VERSION "Generated from PQ35_46 ACAN KMatrix"

NS_ :

BS_:

BU_: XXX AFS Airbag Allrad AppGW_SK BAP_Tester BMS_Hybrid Bremse_ESP_AU714 Bremse_ESP_EPB_EBC460Vi Bremse_MK100_ESC Bremse_MK60EC Bremse_MK70MABS Bremse_TRW_EBC450M Bremse_TRW_ESP Daempfer EPB_TRW EPB_TRW_VW411CS ESP_AU316 FLA Gateway_PQ35 Getriebe_AG6 Getriebe_DL800_R8 Getriebe_DL800_ZSG_R8 Getriebe_DQ Getriebe_DQ_Hyb Getriebe_Sele Gurtmikro_PQ35 HCA LEH_Hybrid LH_EPS_APA LH_EPS_ZF_2G LH_EPS_ZF_3G LPG_Interface_Box LWR LWS Magne_Ride Motor_Diesel Motor_Hybrid Motor_Otto Motor_Slave PDC_PLA Quersperre_VAQ RKA_Plus SAK Waehlhebel Waehlhebel_Sele

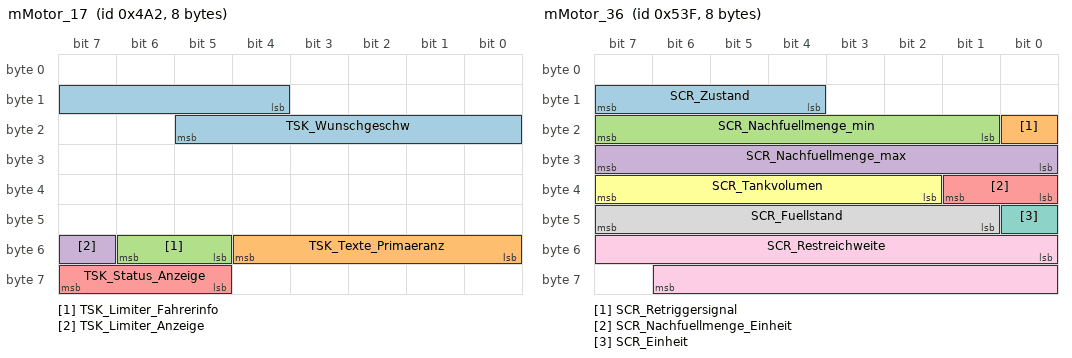
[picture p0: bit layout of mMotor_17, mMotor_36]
BO_ 1186 mMotor_17: 8 XXX
 SG_ TSK_Wunschgeschw : 12|10@1+ (0.32,0) [0|326.72] "Unit_KiloMeterPerHour" Gateway_PQ35
 SG_ TSK_Texte_Primaeranz : 48|5@1+ (1,0) [0|14] "" Gateway_PQ35
 SG_ TSK_Limiter_Fahrerinfo : 53|2@1+ (1,0) [0|3] "" Gateway_PQ35
 SG_ TSK_Limiter_Anzeige : 55|1@1+ (1,0) [0|1] "" Gateway_PQ35
 SG_ TSK_Status_Anzeige : 61|3@1+ (1,0) [0|7] "" Gateway_PQ35

BO_ 1343 mMotor_36: 8 XXX
 SG_ SCR_Zustand : 12|4@1+ (1,0) [0|15] "" Gateway_PQ35
 SG_ SCR_Retriggersignal : 16|1@1+ (1,0) [0|1] "" Gateway_PQ35
 SG_ SCR_Nachfuellmenge_min : 17|7@1+ (0.25,0) [0|31.5] "" Gateway_PQ35
 SG_ SCR_Nachfuellmenge_max : 24|8@1+ (0.25,0) [0|63.5] "" Gateway_PQ35
 SG_ SCR_Nachfuellmenge_Einheit : 32|2@1+ (1,0) [0|3] "" Gateway_PQ35
 SG_ SCR_Tankvolumen : 34|6@1+ (1,0) [0|63] "" Gateway_PQ35
 SG_ SCR_Einheit : 40|1@1+ (1,0) [0|1] "" Gateway_PQ35
 SG_ SCR_Fuellstand : 41|7@1+ (1,0) [0|100] "Unit_PerCent" Gateway_PQ35
 SG_ SCR_Restreichweite : 48|15@1+ (1,0) [0|32767] "" Gateway_PQ35

BO_ 1160 mMotor_6: 8 XXX
 SG_ MO6_Checksum : 0|8@1+ (1,0) [0|255] "" Getriebe_AG6
 SG_ MO6_SollM_Getr : 8|8@1+ (0.39,0) [0|99.06] "Unit_PerCent" Getriebe_DL800_R8,Getriebe_DQ,Getriebe_DQ_Hyb,Getriebe_Sele
 SG_ MO6_Ist_Moment : 16|8@1+ (0.39,0) [0|99.06] "Unit_PerCent" Gateway_PQ35,Getriebe_AG6,Getriebe_DL800_R8,Getriebe_DQ,Getriebe_DQ_Hyb,Getriebe_Sele
 SG_ MO6_Hoeheninfo : 24|8@1+ (0.0078125,0) [0|1.984375] "" Getriebe_AG6,Getriebe_DL800_R8,Getriebe_DQ,Getriebe_DQ_Hyb
 SG_ MO6_GRA_Soll : 32|8@1+ (0.024,-3.984) [-3.984|2.088] "Unit_MeterPerSeconSquar" Getriebe_AG6,Getriebe_DL800_R8,Getriebe_DQ,Getriebe_DQ_Hyb
 SG_ MO6_MomIntGeEing : 40|8@1+ (0.3921568627450980392156862745098,0) [0|100] "Unit_PerCent" Getriebe_DL800_R8,Getriebe_DQ,Getriebe_DQ_Hyb
 SG_ MO6_FF_Mux00 : 48|8@1+ (0.3921568627450980392156862745098,0) [0|100] "Unit_PerCent" BMS_Hybrid,Getriebe_AG6,Getriebe_DL800_R8,Getriebe_DL800_ZSG_R8,Getriebe_DQ,Getriebe_DQ_Hyb,Getriebe_Sele,LEH_Hybrid
 SG_ MO6_FF_Mux01 : 48|8@1+ (0.3921568627450980392156862745098,0) [0|100] "Unit_PerCent" BMS_Hybrid,Getriebe_AG6,Getriebe_DL800_R8,Getriebe_DL800_ZSG_R8,Getriebe_DQ,Getriebe_DQ_Hyb,Getriebe_Sele,LEH_Hybrid
 SG_ MO6_FF_Mux02 : 48|8@1+ (1,-40) [-40|215] "Unit_DegreCelsi" BMS_Hybrid,Getriebe_AG6,Getriebe_DL800_R8,Getriebe_DL800_ZSG_R8,Getriebe_DQ,Getriebe_DQ_Hyb,Getriebe_Sele,LEH_Hybrid
 SG_ MO6_FF_Mux03 : 48|8@1+ (3.13725490196078,0) [0|799.9999999999989] "Unit_PerCent" BMS_Hybrid,Getriebe_AG6,Getriebe_DL800_R8,Getriebe_DL800_ZSG_R8,Getriebe_DQ,Getriebe_DQ_Hyb,Getriebe_Sele,LEH_Hybrid
 SG_ MO6_FF_Mux04 : 48|8@1+ (0.3921568627450980392156862745098,0) [0|100] "Unit_PerCent" BMS_Hybrid,Getriebe_AG6,Getriebe_DL800_R8,Getriebe_DL800_ZSG_R8,Getriebe_DQ,Getriebe_DQ_Hyb,Getriebe_Sele,LEH_Hybrid
 SG_ MO6_FF_Mux05 : 48|8@1+ (1,0) [255|255] "" XXX
 SG_ MO6_FF_Mux06 : 48|8@1+ (1,0) [255|255] "" XXX
 SG_ MO6_FF_Mux07 : 48|8@1+ (1,0) [255|255] "" XXX
 SG_ MO6_FF_Mux08 : 48|8@1+ (1,0) [255|255] "" XXX
 SG_ MO6_FF_Mux09 : 48|8@1+ (1,0) [255|255] "" XXX
 SG_ MO6_FF_Mux10 : 48|8@1+ (1,0) [255|255] "" XXX
 SG_ MO6_FF_Mux11 : 48|8@1+ (1,0) [255|255] "" XXX
 SG_ MO6_FF_Mux12 : 48|8@1+ (1,0) [255|255] "" XXX
 SG_ MO6_FF_Mux13 : 48|8@1+ (1,0) [255|255] "" XXX
 SG_ MO6_FF_Mux14 : 48|8@1+ (1,0) [255|255] "" XXX
 SG_ MO6_FF_Mux15 : 48|8@1+ (1,0) [255|255] "" XXX
 SG_ MO6_Freigabe_GRA : 56|1@1+ (1,0) [0|1] "" Getriebe_AG6,Getriebe_DL800_R8,Getriebe_DQ,Getriebe_DQ_Hyb
 SG_ MO6_Schutz_Toel : 57|1@1+ (1,0) [0|1] "" Getriebe_AG6
 SG_ MO6_Luftpfad_akt : 58|1@1+ (1,0) [0|1] "" XXX
 SG_ MO6_RegPartikel : 59|1@1+ (1,0) [0|1] "" Getriebe_AG6,Getriebe_DL800_R8,Getriebe_DQ,Getriebe_DQ_Hyb
 SG_ MO6_Zaehler : 60|4@1+ (1,0) [0|15] "" BMS_Hybrid,Getriebe_AG6,Getriebe_DL800_R8,Getriebe_DL800_ZSG_R8,Getriebe_DQ,Getriebe_DQ_Hyb,LEH_Hybrid

BO_ 1162 mMotor_8: 8 XXX
 SG_ MO8_Checksumme : 0|8@1+ (1,0) [0|255] "" Gateway_PQ35,Magne_Ride
 SG_ MO8_AnzeigeDZ : 8|12@1+ (3,0) [0|12282] "Unit_MinutInver" AppGW_SK,Gateway_PQ35
 SG_ MO_Effizienzmodus : 20|1@1+ (1,0) [0|1] "" Gateway_PQ35
 SG_ MO8_SGT_Soundakt : 21|1@1+ (1,0) [0|1] "" Gateway_PQ35,SAK
 SG_ MO8_Spoiler_ausf : 22|1@1+ (1,0) [0|1] "" Gateway_PQ35
 SG_ MO8_Sportschalter : 23|1@1+ (1,0) [0|1] "" Gateway_PQ35,Getriebe_Sele,Magne_Ride
 SG_ MO8_LampeDZBegr : 24|1@1+ (1,0) [0|1] "" Gateway_PQ35,Getriebe_Sele
 SG_ MO8_Enable_Oeldr_Motor : 25|1@1+ (1,0) [0|1] "" Gateway_PQ35
 SG_ MO8_Oeldr_Warn_Motor : 26|1@1+ (1,0) [0|1] "" Gateway_PQ35
 SG_ MO8_Avus_Motorschutz : 27|2@1+ (1,0) [0|3] "" Gateway_PQ35,Getriebe_Sele
 SG_ MO8_Anzeigecode : 29|1@1+ (1,0) [0|1] "" AppGW_SK,Gateway_PQ35
 SG_ MO_P_verriegelt : 30|2@1+ (1,0) [0|3] "" Gateway_PQ35
 SG_ MO8_GRA_v_Wunsch : 32|9@1+ (1,0) [0|511] "Unit_KiloMeterPerHour" Gateway_PQ35
 SG_ MO_Schaltempf_verfbar : 41|1@1+ (1,0) [0|1] "" AppGW_SK,Gateway_PQ35
 SG_ MO8_Nachlauf_ZWP : 42|6@1+ (15,0) [0|945] "Unit_Secon" Gateway_PQ35
 SG_ MO_Istgang : 48|4@1+ (1,0) [0|9] "" Gateway_PQ35
 SG_ MO_Sollgang : 52|4@1+ (1,0) [0|15] "" AppGW_SK,Gateway_PQ35
 SG_ MO8_Zaehler : 60|4@1+ (1,0) [0|15] "" Gateway_PQ35,Magne_Ride

BO_ 1800 mMotor_CNG_1: 8 XXX
 SG_ MC1_Anz_Betrieb : 0|1@1+ (1,0) [0|1] "" Gateway_PQ35
 SG_ MC1_Schalter : 1|1@1+ (1,0) [0|1] "" Gateway_PQ35
 SG_ MC1_akt_Betrieb : 2|1@1+ (1,0) [0|1] "" Gateway_PQ35
 SG_ MC1_CNG_LPG : 3|1@1+ (1,0) [0|1] "" Gateway_PQ35
 SG_ MO_LPG_Tankstopp : 4|1@1+ (1,0) [0|1] "" Gateway_PQ35
 SG_ MO_Erdgasqualitaet : 5|3@1+ (1,0) [0|7] "" Gateway_PQ35
 SG_ MC1_Fuellungsgrad : 8|8@1+ (0.4,0) [0|101.2] "Unit_PerCent" Gateway_PQ35
 SG_ MC1_Verbrauch : 16|15@1+ (1,0) [0|32767] "Unit_MilliGram" Gateway_PQ35
 SG_ MC1_Verbrauch_LPG : 16|15@1+ (1,0) [0|32767] "Unit_MicroLiter" Gateway_PQ35
 SG_ MC1_Ueb_Verbr : 31|1@1+ (1,0) [0|1] "" Gateway_PQ35
 SG_ MO_AnzeigeGasbetrieb : 32|4@1+ (1,0) [0|7] "" Gateway_PQ35
 SG_ MO_Gastemperatur : 48|8@1+ (1,-51) [-50|150] "Unit_DegreCelsi" Gateway_PQ35
 SG_ MO_Verbrauchsaequivalent : 56|8@1+ (0.008,0) [0.008|2] "Unit_None" Gateway_PQ35

BO_ 1562 mMotor_EV_1: 8 XXX
 SG_ MEV1_Checksumme : 0|8@1+ (1,0) [0|255] "" XXX
 SG_ MEV1_Zaehler : 8|4@1+ (1,0) [0|15] "" XXX
 SG_ MO_Red_FahrleistungsLampe : 12|1@1+ (1,0) [0|1] "" XXX
 SG_ Ladestecker_gesteckt : 13|1@1+ (1,0) [0|1] "" XXX
 SG_ Ladevorgang_aktiv : 14|1@1+ (1,0) [0|1] "" Gateway_PQ35
 SG_ HV_Bordnetz_aktiv : 15|1@1+ (1,0) [0|1] "" Gateway_PQ35
 SG_ HV_Bordnetz_A_Status : 16|5@1+ (1,0) [0|31] "" XXX
 SG_ HV_PTC_LeistRed : 21|2@1+ (1,0) [0|3] "" XXX
 SG_ HV_PTC_aus : 23|1@1+ (1,0) [0|1] "" XXX
 SG_ Ladestecker_verr_Status : 24|2@1+ (1,0) [0|3] "" XXX
 SG_ HV_Anf_ReichweiteNV : 26|2@1+ (1,0) [0|3] "" Gateway_PQ35
 SG_ MO_Wahl_Pos : 28|3@1+ (1,0) [0|6] "" XXX
 SG_ QB_Ladestecker_gesteckt : 32|1@1+ (1,0) [0|1] "" XXX
 SG_ MO_Fehler_Notabschaltung_Klima : 33|2@1+ (1,0) [0|3] "" XXX
 SG_ QB_Ladezustand_HV_Batterie : 37|1@1+ (1,0) [0|1] "" XXX
 SG_ BMS_Temperierung_Anf : 44|3@1+ (1,0) [0|7] "" XXX
 SG_ Energieinhalt_HV_Batt : 47|9@1+ (0.1,0) [0|50.9] "Unit_KiloWattHour" XXX
 SG_ Ladezustand_HV_Batterie : 56|8@1+ (0.5,0) [0|100] "Unit_PerCent" XXX

BO_ 1154 mMotor_Hybrid_1: 8 XXX
 SG_ MH1_VM_Mom_oE : 0|8@1+ (0.8,-100) [-100|103.2] "Unit_PerCent" Getriebe_DQ_Hyb
 SG_ MH1_IstStatusK0 : 8|2@1+ (1,0) [0|3] "" Getriebe_DQ_Hyb
 SG_ MH1_Startmodus_PQ35 : 10|1@1+ (1,0) [0|1] "" Getriebe_DQ_Hyb
 SG_ MH1_VM_aktiv : 11|1@1+ (1,0) [0|1] "" Getriebe_DQ_Hyb
 SG_ MH1_Zielzustand_Hybrid : 12|3@1+ (1,0) [0|7] "" Getriebe_DQ_Hyb
 SG_ MH1_Schaltverh : 15|1@1+ (1,0) [0|1] "" Getriebe_DQ_Hyb
 SG_ MH1_VerlParam_Msum : 16|2@1+ (1,0) [0|3] "" Getriebe_DQ_Hyb
 SG_ MH1_MomVerlauf_EM : 18|6@1+ (5,0) [0|315] "Unit_NewtoMeter" Getriebe_DQ_Hyb
 SG_ MH1_E_Faktor : 20|4@1+ (1,0) [0|15] "" Getriebe_DQ_Hyb
 SG_ MH1_Drehzahl_VM : 24|16@1+ (0.25,0) [0|16256] "Unit_MinutInver" BMS_Hybrid,Getriebe_DQ_Hyb,LEH_Hybrid
 SG_ MH1_max_ind_VM_Mom : 40|8@1+ (0.39,0) [0|99.06] "Unit_PerCent" XXX
 SG_ MH1_Notstart : 48|1@1+ (1,0) [0|1] "" Getriebe_DQ_Hyb
 SG_ MH1_LowSpeedModus : 51|1@1+ (1,0) [0|1] "" Getriebe_DQ_Hyb
 SG_ MH1_ACCGRA_aktiv : 52|1@1+ (1,0) [0|1] "" Getriebe_DQ_Hyb
 SG_ MH1_EMode_Info : 53|2@1+ (1,0) [0|3] "" Getriebe_DQ_Hyb
 SG_ MH1_QB_Bremspedalwert : 55|1@1+ (1,0) [0|1] "" XXX
 SG_ MH1_Bremspedalwert : 56|8@1+ (0.4,0) [0|100] "Unit_PerCent" Getriebe_DQ_Hyb

BO_ 399 mMotor_LPG_01: 8 XXX
 SG_ Motor_LPG_01_Reserve : 0|64@1+ (1,0) [0|0] "" LPG_Interface_Box

BO_ 1823 mMotorslave_Istverbau: 1 XXX
 SG_ MSI_KD_Fehler : 0|1@1+ (1,0) [0|1] "" Gateway_PQ35

BO_ 1428 mNiveau_2: 8 XXX
 SG_ NI2_Checksum : 0|8@1+ (1,0) [0|255] "" AFS,Gateway_PQ35,LWR
 SG_ NI2_Zaehler : 8|4@1+ (1,0) [0|15] "" AFS,Gateway_PQ35,LWR
 SG_ NI2_Hoehenflag : 12|1@1+ (1,0) [0|1] "" AFS,Gateway_PQ35
 SG_ NI2_Hoehe_VL : 16|8@1+ (1,-127) [-127|126] "Unit_MilliMeter" AFS,Gateway_PQ35,LWR
 SG_ NI2_Hoehe_VL_Roh : 16|8@1+ (0.4,0) [0|100] "Unit_PerCent" AFS,Gateway_PQ35
 SG_ NI2_Hoehe_VR : 24|8@1+ (1,-127) [-127|126] "Unit_MilliMeter" AFS,Gateway_PQ35,LWR
 SG_ NI2_Hoehe_VR_Roh : 24|8@1+ (0.4,0) [0|100] "Unit_PerCent" AFS,Gateway_PQ35
 SG_ NI2_Hoehe_HL : 32|8@1+ (1,-127) [-127|126] "Unit_MilliMeter" AFS,Gateway_PQ35,LWR
 SG_ NI2_Hoehe_HL_Roh : 32|8@1+ (0.4,0) [0|100] "Unit_PerCent" AFS,Gateway_PQ35
 SG_ NI2_Hoehe_HR : 40|8@1+ (1,-127) [-127|126] "Unit_MilliMeter" AFS,Gateway_PQ35,LWR
 SG_ NI2_Hoehe_HR_Roh : 40|8@1+ (0.4,0) [0|100] "Unit_PerCent" AFS,Gateway_PQ35
 SG_ NI2_AufbBeschl_VL : 48|8@1+ (0.08,-10.08) [-10.08|10.08] "Unit_MeterPerSeconSquar" AFS,Gateway_PQ35
 SG_ NI2_AufbBeschl_VR : 56|8@1+ (0.08,-10.08) [-10.08|10.08] "Unit_MeterPerSeconSquar" AFS,Gateway_PQ35

BO_ 1349 mParkhilfe_3: 4 XXX
 SG_ PA3_System_codierung : 0|1@1+ (1,0) [0|1] "" Gateway_PQ35
 SG_ PA3_Anlage_defekt : 1|1@1+ (1,0) [0|1] "" Gateway_PQ35
 SG_ PA3_Taster_aktiviert : 2|1@1+ (1,0) [0|1] "" Gateway_PQ35
 SG_ PA3_Rueckwaertsgang_aktiv : 3|1@1+ (1,0) [0|1] "" Gateway_PQ35
 SG_ PA3_Geschwindigkeit_aus : 4|1@1+ (1,0) [0|1] "" Gateway_PQ35
 SG_ PA3_Tongeber_v_defekt : 5|1@1+ (1,0) [0|1] "" Gateway_PQ35
 SG_ PA3_Tongeber_h_defekt : 6|1@1+ (1,0) [0|1] "" Gateway_PQ35
 SG_ PA3_Audioabsenkung_Anforderung : 7|1@1+ (1,0) [0|1] "" Gateway_PQ35
 SG_ PA3_Eis_aus : 8|1@1+ (1,0) [0|1] "" Gateway_PQ35
 SG_ PA3_Schlechtweg_aus : 9|1@1+ (1,0) [0|1] "" Gateway_PQ35
 SG_ PA3_KD_Fehler : 15|1@1+ (1,0) [0|1] "" Gateway_PQ35
 SG_ PA3_Sensor_hll_defekt : 16|1@1+ (1,0) [0|1] "" Gateway_PQ35
 SG_ PA3_Sensor_hlm_defekt : 17|1@1+ (1,0) [0|1] "" Gateway_PQ35
 SG_ PA3_Sensor_hrm_defekt : 18|1@1+ (1,0) [0|1] "" Gateway_PQ35
 SG_ PA3_Sensor_hrr_defekt : 19|1@1+ (1,0) [0|1] "" Gateway_PQ35
 SG_ PA3_Sensor_vll_defekt : 20|1@1+ (1,0) [0|1] "" Gateway_PQ35
 SG_ PA3_Sensor_vlm_defekt : 21|1@1+ (1,0) [0|1] "" Gateway_PQ35
 SG_ PA3_Sensor_vrm_defekt : 22|1@1+ (1,0) [0|1] "" Gateway_PQ35
 SG_ PA3_Sensor_vrr_defekt : 23|1@1+ (1,0) [0|1] "" Gateway_PQ35
 SG_ PA3_Bereit : 24|1@1+ (1,0) [0|1] "" Gateway_PQ35
 SG_ PA3_Bereich_vo : 26|2@1+ (1,0) [0|3] "" Gateway_PQ35
 SG_ PA3_Bereich_hi : 28|2@1+ (1,0) [0|3] "" Gateway_PQ35
 SG_ PA3_Akust_aus : 30|1@1+ (1,0) [0|1] "" Gateway_PQ35
 SG_ PA3_Aufbau_erk : 31|1@1+ (1,0) [0|1] "" Gateway_PQ35

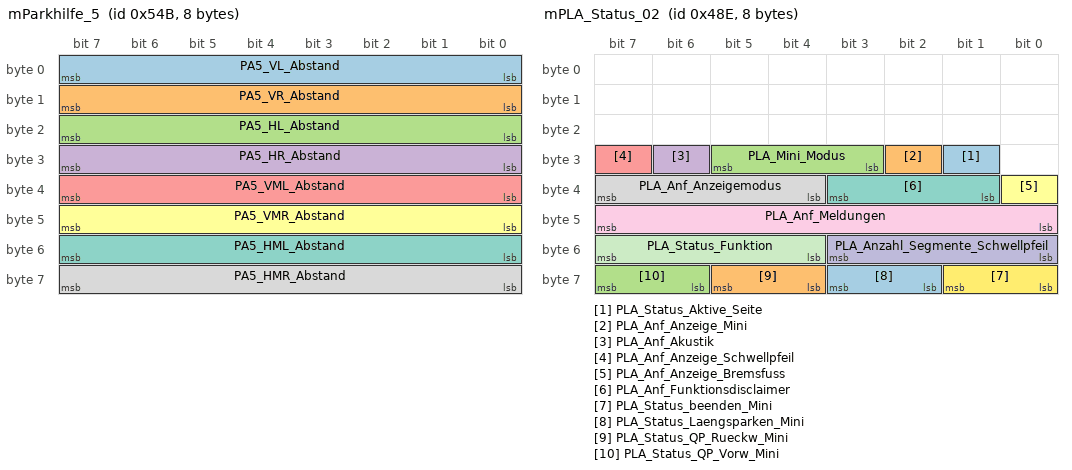
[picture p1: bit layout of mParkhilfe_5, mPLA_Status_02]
BO_ 1355 mParkhilfe_5: 8 XXX
 SG_ PA5_VL_Abstand : 0|8@1+ (1,0) [0|254] "Unit_CentiMeter" Gateway_PQ35
 SG_ PA5_VR_Abstand : 8|8@1+ (1,0) [0|254] "Unit_CentiMeter" Gateway_PQ35
 SG_ PA5_HL_Abstand : 16|8@1+ (1,0) [0|254] "Unit_CentiMeter" Gateway_PQ35
 SG_ PA5_HR_Abstand : 24|8@1+ (1,0) [0|254] "Unit_CentiMeter" Gateway_PQ35
 SG_ PA5_VML_Abstand : 32|8@1+ (1,0) [0|254] "Unit_CentiMeter" Gateway_PQ35
 SG_ PA5_VMR_Abstand : 40|8@1+ (1,0) [0|254] "Unit_CentiMeter" Gateway_PQ35
 SG_ PA5_HML_Abstand : 48|8@1+ (1,0) [0|254] "Unit_CentiMeter" Gateway_PQ35
 SG_ PA5_HMR_Abstand : 56|8@1+ (1,0) [0|254] "Unit_CentiMeter" Gateway_PQ35

BO_ 1166 mPLA_Status_02: 8 XXX
 SG_ PLA_Status_Aktive_Seite : 25|1@1+ (1,0) [0|1] "" Gateway_PQ35
 SG_ PLA_Anf_Anzeige_Mini : 26|1@1+ (1,0) [0|1] "" Gateway_PQ35
 SG_ PLA_Mini_Modus : 27|3@1+ (1,0) [0|3] "" Gateway_PQ35
 SG_ PLA_Anf_Akustik : 30|1@1+ (1,0) [0|1] "" Gateway_PQ35
 SG_ PLA_Anf_Anzeige_Schwellpfeil : 31|1@1+ (1,0) [0|1] "" Gateway_PQ35
 SG_ PLA_Anf_Anzeige_Bremsfuss : 32|1@1+ (1,0) [0|1] "" Gateway_PQ35
 SG_ PLA_Anf_Funktionsdisclaimer : 33|3@1+ (1,0) [0|3] "" Gateway_PQ35
 SG_ PLA_Anf_Anzeigemodus : 36|4@1+ (1,0) [0|15] "" Gateway_PQ35
 SG_ PLA_Anf_Meldungen : 40|8@1+ (1,0) [0|0] "" Gateway_PQ35
 SG_ PLA_Anzahl_Segmente_Schwellpfeil : 48|4@1+ (1,0) [0|15] "" Gateway_PQ35
 SG_ PLA_Status_Funktion : 52|4@1+ (1,0) [0|15] "" Gateway_PQ35
 SG_ PLA_Status_beenden_Mini : 56|2@1+ (1,0) [0|3] "" Gateway_PQ35
 SG_ PLA_Status_Laengsparken_Mini : 58|2@1+ (1,0) [0|3] "" Gateway_PQ35
 SG_ PLA_Status_QP_Rueckw_Mini : 60|2@1+ (1,0) [0|3] "" Gateway_PQ35
 SG_ PLA_Status_QP_Vorw_Mini : 62|2@1+ (1,0) [0|3] "" Gateway_PQ35

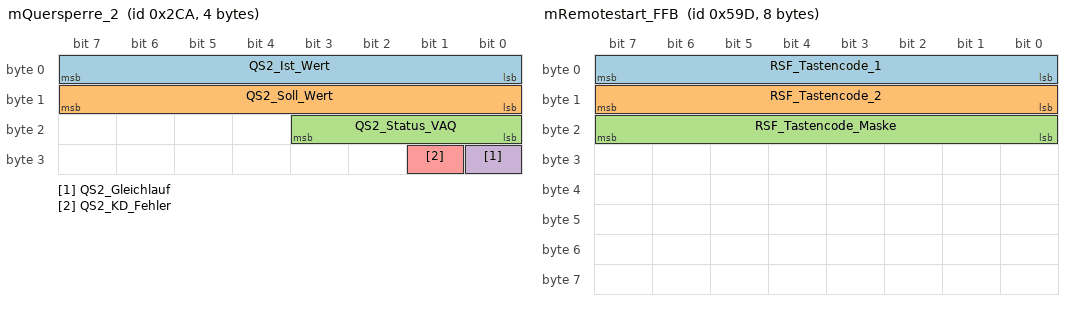
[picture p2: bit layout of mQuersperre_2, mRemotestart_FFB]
BO_ 714 mQuersperre_2: 4 XXX
 SG_ QS2_Ist_Wert : 0|8@1+ (10,0) [0|2540] "Unit_NewtoMeter" Bremse_MK60EC
 SG_ QS2_Soll_Wert : 8|8@1+ (10,0) [0|2540] "Unit_NewtoMeter" Bremse_MK60EC
 SG_ QS2_Status_VAQ : 16|4@1+ (1,0) [0|6] "" Bremse_MK60EC
 SG_ QS2_Gleichlauf : 24|1@1+ (1,0) [0|1] "" Bremse_MK60EC
 SG_ QS2_KD_Fehler : 25|1@1+ (1,0) [0|1] "" Gateway_PQ35

BO_ 1437 mRemotestart_FFB: 8 XXX
 SG_ RSF_Tastencode_1 : 0|8@1+ (1,0) [1|255] "Unit_None" Motor_Diesel,Motor_Otto
 SG_ RSF_Tastencode_2 : 8|8@1+ (1,0) [1|255] "Unit_None" Motor_Diesel,Motor_Otto
 SG_ RSF_Tastencode_Maske : 16|8@1+ (1,0) [1|255] "Unit_None" Motor_Diesel,Motor_Otto

BO_ 16 MSG1_WFS_Anfrage: 8 XXX
 SG_ MSG1_WFS_RND : 0|32@1+ (1,0) [0|4294967295] "" Gateway_PQ35
 SG_ MSG1_WFS_CRC : 32|32@1+ (1,0) [0|4294967295] "" Gateway_PQ35

BO_ 20 MSG2_WFS_Anfrage: 8 XXX
 SG_ MSG2_WFS_RND : 0|32@1+ (1,0) [0|4294967295] "" Gateway_PQ35
 SG_ MSG2_WFS_CRC : 32|32@1+ (1,0) [0|4294967295] "" Gateway_PQ35

BO_ 22 MSG3_WFS_Anfrage: 8 XXX
 SG_ MSG3_WFS_RND : 0|32@1+ (1,0) [0|4294967295] "" Gateway_PQ35
 SG_ MSG3_WFS_CRC : 32|32@1+ (1,0) [0|4294967295] "" Gateway_PQ35

BO_ 24 MSG4_WFS_Anfrage: 8 XXX
 SG_ MSG4_WFS_RND : 0|32@1+ (1,0) [0|4294967295] "" Gateway_PQ35
 SG_ MSG4_WFS_CRC : 32|32@1+ (1,0) [0|4294967295] "" Gateway_PQ35

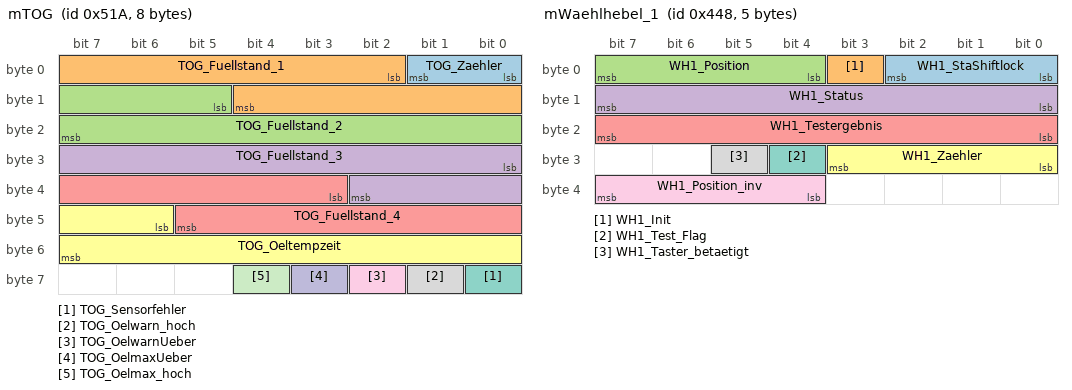
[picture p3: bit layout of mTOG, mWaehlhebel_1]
BO_ 1306 mTOG: 8 XXX
 SG_ TOG_Zaehler : 0|2@1+ (1,0) [0|3] "" XXX
 SG_ TOG_Fuellstand_1 : 2|11@1+ (0.5,100) [101|1123] "Unit_MilliSecon" Motor_Diesel,Motor_Hybrid,Motor_Otto
 SG_ TOG_Fuellstand_2 : 13|11@1+ (0.5,100) [101|1123] "Unit_MilliSecon" Motor_Diesel,Motor_Hybrid,Motor_Otto
 SG_ TOG_Fuellstand_3 : 24|11@1+ (0.5,100) [101|1123] "Unit_MilliSecon" Motor_Diesel,Motor_Hybrid,Motor_Otto
 SG_ TOG_Fuellstand_4 : 35|11@1+ (0.5,100) [101|1123] "Unit_MilliSecon" Motor_Diesel,Motor_Hybrid,Motor_Otto
 SG_ TOG_Oeltempzeit : 46|10@1+ (0.125,0) [0.25|127] "Unit_MilliSecon" Motor_Diesel,Motor_Hybrid,Motor_Otto
 SG_ TOG_Sensorfehler : 56|1@1+ (1,0) [0|1] "" Motor_Diesel,Motor_Hybrid,Motor_Otto
 SG_ TOG_Oelwarn_hoch : 57|1@1+ (1,0) [0|1] "" Motor_Diesel,Motor_Hybrid,Motor_Otto
 SG_ TOG_OelwarnUeber : 58|1@1+ (1,0) [0|1] "" XXX
 SG_ TOG_OelmaxUeber : 59|1@1+ (1,0) [0|1] "" XXX
 SG_ TOG_Oelmax_hoch : 60|1@1+ (1,0) [0|1] "" XXX

BO_ 1937 mTP_Dyn_ABS_2: 8 XXX
 SG_ TPDyn_ABS_2 : 0|64@1+ (1,0) [0|0] "" XXX

BO_ 1904 mTP_Dyn_ADR_1: 8 XXX
 SG_ TPDyn_ADR_1 : 0|64@1+ (1,0) [0|0] "" XXX

BO_ 1896 mTP_Dyn_Airbag_1: 8 XXX
 SG_ TPDyn_Airbag_1 : 0|64@1+ (1,0) [0|0] "" Airbag

BO_ 1906 mTP_Dyn_Daempfer_1: 8 XXX
 SG_ TPDyn_Daempfer_1 : 0|64@1+ (1,0) [0|0] "" Daempfer,Magne_Ride

BO_ 1940 mTP_Dyn_EPB_1: 8 XXX
 SG_ TPDyn_EPB_1 : 0|64@1+ (1,0) [0|0] "" EPB_TRW

BO_ 1864 mTP_Dyn_FLA_1: 8 XXX
 SG_ TPDyn_FLA_1 : 0|64@1+ (1,0) [0|0] "" FLA

BO_ 1888 mTP_Dyn_Getriebe_1: 8 XXX
 SG_ TPDyn_Getriebe_1 : 0|64@1+ (1,0) [0|0] "" Getriebe_AG6,Getriebe_DQ,Getriebe_DQ_Hyb,Getriebe_Sele

BO_ 1889 mTP_Dyn_Getriebe_2: 8 XXX
 SG_ TPDyn_Getriebe_2 : 0|64@1+ (1,0) [0|0] "" Getriebe_AG6,Getriebe_DQ,Getriebe_DQ_Hyb,Getriebe_Sele

BO_ 1956 mTP_Dyn_LDW_1: 8 XXX
 SG_ TPDyn_LDW_1 : 0|64@1+ (1,0) [0|0] "" XXX

BO_ 1957 mTP_Dyn_LDW_2: 8 XXX
 SG_ TPDyn_LDW_2 : 0|64@1+ (1,0) [0|0] "" HCA

BO_ 1960 mTP_Dyn_Lenkhilfe_1: 8 XXX
 SG_ TPDyn_Lenkhilfe_1 : 0|64@1+ (1,0) [0|0] "" LH_EPS_APA,LH_EPS_ZF_2G

BO_ 1961 mTP_Dyn_Lenkhilfe_2: 8 XXX
 SG_ TPDyn_Lenkhilfe_2 : 0|64@1+ (1,0) [0|0] "" LH_EPS_APA,LH_EPS_ZF_2G

BO_ 1924 mTP_Dyn_LWR_1: 8 XXX
 SG_ TPDyn_Dyn_LWR_1 : 0|64@1+ (1,0) [0|0] "" AFS,LWR

BO_ 1925 mTP_Dyn_LWR_2: 8 XXX
 SG_ TPDyn_Dyn_LWR_2 : 0|64@1+ (1,0) [0|0] "" AFS,LWR

BO_ 1952 mTP_Dyn_LWS: 8 XXX
 SG_ TPDyn_LWS : 0|64@1+ (1,0) [0|0] "" XXX

BO_ 1856 mTP_Dyn_Motor_1: 8 XXX
 SG_ TPDyn_Motor_1 : 0|64@1+ (1,0) [0|0] "" Motor_Diesel,Motor_Hybrid,Motor_Otto

BO_ 1857 mTP_Dyn_Motor_2: 8 XXX
 SG_ TPDyn_Motor_2 : 0|64@1+ (1,0) [0|0] "" Motor_Diesel,Motor_Hybrid,Motor_Otto

BO_ 1858 mTP_Dyn_Motor_3: 8 XXX
 SG_ TPDyn_Motor_3 : 0|64@1+ (1,0) [0|0] "" Motor_Diesel,Motor_Hybrid,Motor_Otto

BO_ 1859 mTP_Dyn_Motor_4: 8 XXX
 SG_ TPDyn_Motor_4 : 0|64@1+ (1,0) [0|0] "" Motor_Diesel,Motor_Hybrid,Motor_Otto

BO_ 1978 mTP_Dyn_PLA_PDC: 8 XXX
 SG_ TPDyn_PLA_PDC : 0|64@1+ (1,0) [0|0] "" PDC_PLA

BO_ 1880 mTP_Dyn_Quersperre_1: 8 XXX
 SG_ TPDyn_Quersperre_1 : 0|64@1+ (1,0) [0|0] "" Quersperre_VAQ

BO_ 1881 mTP_Dyn_Quersperre_2: 8 XXX
 SG_ TPDyn_Quersperre_2 : 0|64@1+ (1,0) [0|0] "" Quersperre_VAQ

BO_ 1875 mTP_Dyn_RKA_Plus_2: 8 XXX
 SG_ TPDyn_RKA_Plus_2 : 0|64@1+ (1,0) [0|0] "" RKA_Plus

BO_ 1920 mTP_Dyn_WFS_1: 8 XXX
 SG_ TPDyn_WFS_1 : 0|64@1+ (1,0) [0|0] "" Gateway_PQ35

BO_ 1921 mTP_Dyn_WFS_2: 8 XXX
 SG_ TPDyn_WFS_2 : 0|64@1+ (1,0) [0|0] "" Gateway_PQ35

BO_ 523 mTP_Er_ADR: 7 XXX
 SG_ ADR_TP_Er : 0|56@1+ (1,0) [0|0] "" Gateway_PQ35

BO_ 517 mTP_Er_Airbag: 7 XXX
 SG_ Airbag_TP_Er : 0|56@1+ (1,0) [0|0] "" Gateway_PQ35

BO_ 522 mTP_Er_Allrad: 7 XXX
 SG_ Allrad_TP_Er : 0|56@1+ (1,0) [0|0] "" Gateway_PQ35

BO_ 524 mTP_Er_Daempfer: 7 XXX
 SG_ Daempfer_TP_Er : 0|56@1+ (1,0) [0|0] "" Gateway_PQ35

BO_ 537 mTP_Er_EPB: 7 XXX
 SG_ EPB_TP_Er : 0|56@1+ (1,0) [0|0] "" Gateway_PQ35

BO_ 534 mTP_Er_FLA: 7 XXX
 SG_ FLA_TP_Er : 0|56@1+ (1,0) [0|0] "" Gateway_PQ35

BO_ 514 mTP_Er_Getriebe: 7 XXX
 SG_ Getriebe_TP_Er : 0|56@1+ (1,0) [0|0] "" Gateway_PQ35

BO_ 538 mTP_Er_LDW: 7 XXX
 SG_ LDW_TP_Er : 0|56@1+ (1,0) [0|0] "" Gateway_PQ35

BO_ 521 mTP_Er_Lenkhilfe: 7 XXX
 SG_ Lenkhilfe_TP_Er : 0|56@1+ (1,0) [0|0] "" Gateway_PQ35

BO_ 518 mTP_Er_LWR: 7 XXX
 SG_ Dyn_LWR_TP_Er : 0|56@1+ (1,0) [0|0] "" Gateway_PQ35

BO_ 531 mTP_Er_LWS: 7 XXX
 SG_ LWS_TP_Er : 0|56@1+ (1,0) [0|0] "" Gateway_PQ35

BO_ 533 mTP_Er_Mot_Slave_1: 7 XXX
 SG_ Mot_Slave_1_TP_Er : 0|56@1+ (1,0) [0|0] "" Gateway_PQ35

BO_ 513 mTP_Er_Motor: 7 XXX
 SG_ Motor_TP_Er : 0|56@1+ (1,0) [0|0] "" Gateway_PQ35

BO_ 541 mTP_Er_PLA_PDC: 7 XXX
 SG_ PLA_PDC_TP_Er : 0|56@1+ (1,0) [0|0] "" Gateway_PQ35

BO_ 536 mTP_Er_Quersperre: 7 XXX
 SG_ Quersperre_TP_Er : 0|56@1+ (1,0) [0|0] "" Gateway_PQ35

BO_ 520 mTP_Er_RKA_Plus: 7 XXX
 SG_ RKA_Plus_TP_Er : 0|56@1+ (1,0) [0|0] "" Gateway_PQ35

BO_ 532 mTP_Er_WFS: 7 XXX
 SG_ WFS_TP_Er : 0|56@1+ (1,0) [0|0] "" XXX

BO_ 1096 mWaehlhebel_1: 5 XXX
 SG_ WH1_StaShiftlock : 0|3@1+ (1,0) [0|7] "" Getriebe_DQ,Getriebe_DQ_Hyb
 SG_ WH1_Init : 3|1@1+ (1,0) [0|1] "" Getriebe_DQ,Getriebe_DQ_Hyb
 SG_ WH1_Position : 4|4@1+ (1,0) [1|15] "" Getriebe_DQ,Getriebe_DQ_Hyb
 SG_ WH1_Status : 8|8@1+ (1,0) [0|128] "" Getriebe_DQ,Getriebe_DQ_Hyb
 SG_ WH1_Testergebnis : 16|8@1+ (1,0) [0|255] "" Getriebe_DQ,Getriebe_DQ_Hyb
 SG_ WH1_Zaehler : 24|4@1+ (1,0) [0|15] "" Getriebe_DQ,Getriebe_DQ_Hyb
 SG_ WH1_Test_Flag : 28|1@1+ (1,0) [0|1] "" Getriebe_DQ,Getriebe_DQ_Hyb
 SG_ WH1_Taster_betaetigt : 29|1@1+ (1,0) [0|1] "" XXX
 SG_ WH1_Position_inv : 36|4@1+ (1,0) [0|15] "" Getriebe_DQ,Getriebe_DQ_Hyb

BO_ 1102 mWaehlhebel_2: 5 XXX
 SG_ WH2_Checksumme : 0|8@1+ (1,0) [0|255] "" Getriebe_DL800_R8,Getriebe_Sele
 SG_ WH2_Zaehler : 8|4@1+ (1,0) [0|15] "" Getriebe_DL800_R8,Getriebe_Sele
 SG_ WH2_Init : 12|1@1+ (1,0) [0|1] "" Getriebe_DL800_R8,Getriebe_Sele
 SG_ WH2_Test_Flag : 13|1@1+ (1,0) [0|1] "" Getriebe_DL800_R8,Getriebe_Sele
 SG_ WH2_Sport : 14|1@1+ (1,0) [0|1] "" Getriebe_DL800_R8,Getriebe_Sele
 SG_ WH2_Winter : 15|1@1+ (1,0) [0|1] "" Getriebe_Sele
 SG_ WH2_Position : 16|3@1+ (1,0) [0|7] "" Getriebe_DL800_R8,Getriebe_Sele
 SG_ WH2_P_Taster : 21|2@1+ (1,0) [0|3] "" Getriebe_DL800_R8
 SG_ WH2_Ruhestromfehler : 23|1@1+ (1,0) [0|1] "" Getriebe_DL800_R8,Getriebe_Sele
 SG_ WH2_Sensorarray_Einfachfehler : 24|1@1+ (1,0) [0|1] "" Getriebe_DL800_R8,Getriebe_Sele
 SG_ WH2_Sensorarray_Mehrfachfehler : 25|1@1+ (1,0) [0|1] "" Getriebe_DL800_R8,Getriebe_Sele
 SG_ WH2_Fehler_Sporttaster : 26|1@1+ (1,0) [0|1] "" Getriebe_DL800_R8,Getriebe_Sele
 SG_ WH2_Fehler_Fahrstufenanzeige : 27|1@1+ (1,0) [0|1] "" Getriebe_DL800_R8,Getriebe_Sele
 SG_ WH2_Fehler_Spannungsversorgung : 28|1@1+ (1,0) [0|1] "" Getriebe_DL800_R8,Getriebe_Sele
 SG_ WH2_Timeout_Kombi_2 : 29|1@1+ (1,0) [0|1] "" Getriebe_DL800_R8,Getriebe_Sele
 SG_ WH2_Timeout_Getriebe_5 : 30|1@1+ (1,0) [0|1] "" Getriebe_DL800_R8,Getriebe_Sele
 SG_ WH2_Timeout_Gate_Komf_1 : 31|1@1+ (1,0) [0|1] "" Getriebe_DL800_R8,Getriebe_Sele
 SG_ WH2_Testergebnis : 32|8@1+ (1,0) [0|255] "" Getriebe_DL800_R8,Getriebe_Sele

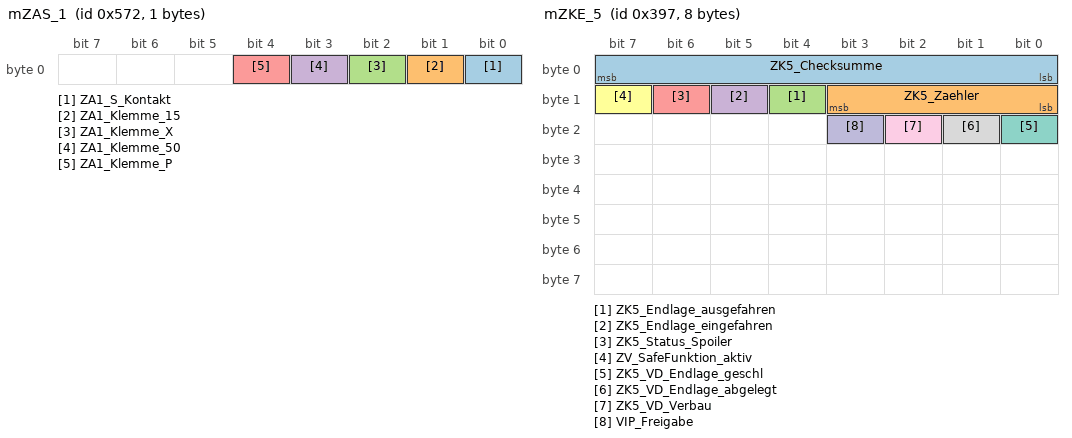
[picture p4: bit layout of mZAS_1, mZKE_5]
BO_ 1394 mZAS_1: 1 XXX
 SG_ ZA1_S_Kontakt : 0|1@1+ (1,0) [0|1] "" XXX
 SG_ ZA1_Klemme_15 : 1|1@1+ (1,0) [0|1] "" PDC_PLA
 SG_ ZA1_Klemme_X : 2|1@1+ (1,0) [0|1] "" PDC_PLA
 SG_ ZA1_Klemme_50 : 3|1@1+ (1,0) [0|1] "" XXX
 SG_ ZA1_Klemme_P : 4|1@1+ (1,0) [0|1] "" XXX

BO_ 919 mZKE_5: 8 XXX
 SG_ ZK5_Checksumme : 0|8@1+ (1,0) [0|255] "" Bremse_ESP_AU714,Bremse_MK60EC
 SG_ ZK5_Zaehler : 8|4@1+ (1,0) [0|15] "" Bremse_ESP_AU714,Bremse_MK60EC
 SG_ ZK5_Endlage_ausgefahren : 12|1@1+ (1,0) [0|1] "" Bremse_ESP_AU714,Bremse_MK60EC
 SG_ ZK5_Endlage_eingefahren : 13|1@1+ (1,0) [0|1] "" Bremse_MK60EC
 SG_ ZK5_Status_Spoiler : 14|1@1+ (1,0) [0|1] "" Bremse_MK60EC
 SG_ ZV_SafeFunktion_aktiv : 15|1@1+ (1,0) [0|1] "" XXX
 SG_ ZK5_VD_Endlage_geschl : 16|1@1+ (1,0) [0|1] "" Bremse_MK60EC,PDC_PLA
 SG_ ZK5_VD_Endlage_abgelegt : 17|1@1+ (1,0) [0|1] "" Bremse_MK60EC,PDC_PLA
 SG_ ZK5_VD_Verbau : 18|1@1+ (1,0) [0|1] "" Bremse_MK60EC,PDC_PLA
 SG_ VIP_Freigabe : 19|1@1+ (1,0) [0|1] "" XXX

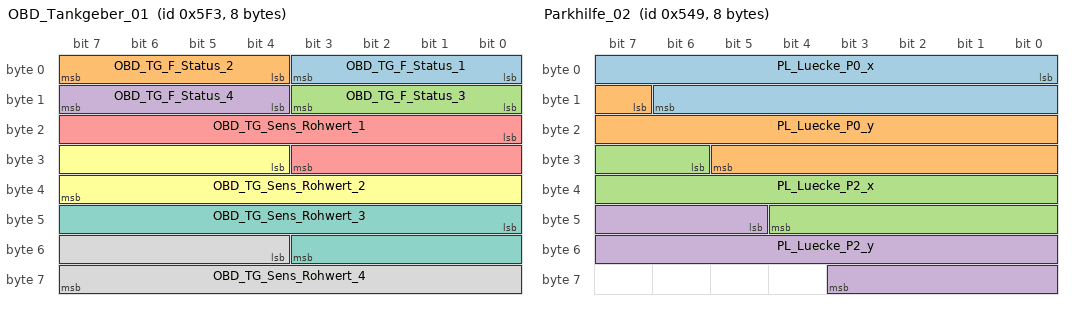
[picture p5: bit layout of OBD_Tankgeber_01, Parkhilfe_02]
BO_ 1523 OBD_Tankgeber_01: 8 XXX
 SG_ OBD_TG_F_Status_1 : 0|4@1+ (1,0) [0|15] "" Motor_Otto
 SG_ OBD_TG_F_Status_2 : 4|4@1+ (1,0) [0|15] "" Motor_Otto
 SG_ OBD_TG_F_Status_3 : 8|4@1+ (1,0) [0|15] "" Motor_Otto
 SG_ OBD_TG_F_Status_4 : 12|4@1+ (1,0) [0|15] "" Motor_Otto
 SG_ OBD_TG_Sens_Rohwert_1 : 16|12@1+ (0.5,0) [0|2047.5] "Unit_Ohm" Motor_Otto
 SG_ OBD_TG_Sens_Rohwert_2 : 28|12@1+ (0.5,0) [0|2047.5] "Unit_Ohm" Motor_Otto
 SG_ OBD_TG_Sens_Rohwert_3 : 40|12@1+ (0.5,0) [0|2047.5] "Unit_Ohm" Motor_Otto
 SG_ OBD_TG_Sens_Rohwert_4 : 52|12@1+ (0.5,0) [0|2047.5] "Unit_Ohm" Motor_Otto

BO_ 1175 Parkhilfe_01: 8 XXX
 SG_ PH_Freie_Weglaenge_Heck : 0|9@1+ (0.01,0) [0|5] "Unit_Meter" Gateway_PQ35
 SG_ PH_Freie_Weglaenge_Heck_Typ : 9|1@1+ (1,0) [0|1] "" Gateway_PQ35
 SG_ PH_nachtr_Stopp_Anf : 12|1@1+ (1,0) [0|1] "" Gateway_PQ35,Motor_Diesel,Motor_Otto
 SG_ PH_Abschaltursache : 13|3@1+ (1,0) [0|7] "" Gateway_PQ35
 SG_ PH_Opt_Anzeige_V_ein : 16|1@1+ (1,0) [1|1] "" Gateway_PQ35
 SG_ PH_Opt_Anzeige_H_ein : 17|1@1+ (1,0) [1|1] "" Gateway_PQ35
 SG_ PH_Opt_Anz_V_Hindernis : 18|1@1+ (1,0) [1|1] "" Gateway_PQ35
 SG_ PH_Opt_Anz_H_Hindernis : 19|1@1+ (1,0) [1|1] "" Gateway_PQ35
 SG_ PH_Tongeber_V_aktiv : 20|1@1+ (1,0) [1|1] "" Gateway_PQ35
 SG_ PH_Tongeber_H_aktiv : 21|1@1+ (1,0) [1|1] "" Gateway_PQ35
 SG_ PH_Tongeber_mute : 22|1@1+ (1,0) [1|1] "" Gateway_PQ35
 SG_ PH_Anf_Audioabsenkung : 23|1@1+ (1,0) [1|1] "" Gateway_PQ35
 SG_ PH_Tongeber_H_verfuegbar : 24|1@1+ (1,0) [0|1] "" Gateway_PQ35
 SG_ PLA_Anf_Aufschaltung_RVC : 25|1@1+ (1,0) [0|1] "" Gateway_PQ35
 SG_ PH_Stoermeldung : 26|4@1+ (1,0) [0|6] "" Gateway_PQ35
 SG_ PH_Anf_Verdeck : 30|2@1+ (1,0) [0|3] "" Gateway_PQ35
 SG_ PH_Frequenz_hinten : 32|4@1+ (1,0) [0|15] "" Gateway_PQ35
 SG_ PH_Lautstaerke_hinten : 36|4@1+ (1,0) [0|15] "" Gateway_PQ35
 SG_ PH_Frequenz_vorn : 40|4@1+ (1,0) [0|15] "" Gateway_PQ35
 SG_ PH_Lautstaerke_vorn : 44|4@1+ (1,0) [0|15] "" Gateway_PQ35
 SG_ PH_Trigger_Bildaufschaltung : 48|1@1+ (1,0) [0|1] "" Gateway_PQ35
 SG_ PH_StartStopp_Info : 49|2@1+ (1,0) [0|3] "" Gateway_PQ35,Motor_Diesel,Motor_Otto
 SG_ PH_Aufbauten_erk : 51|1@1+ (1,0) [0|1] "" Gateway_PQ35
 SG_ PH_BerErk_vorn : 52|2@1+ (1,0) [0|3] "" Gateway_PQ35
 SG_ PH_BerErk_hinten : 54|2@1+ (1,0) [0|3] "" Gateway_PQ35
 SG_ PH_defekt : 56|1@1+ (1,0) [1|1] "" Gateway_PQ35
 SG_ PH_gestoert : 57|1@1+ (1,0) [1|1] "" Gateway_PQ35
 SG_ PH_Systemzustand : 58|3@1+ (1,0) [0|7] "" Gateway_PQ35
 SG_ PH_Display_Kundenwunsch : 61|2@1+ (1,0) [0|3] "" Gateway_PQ35
 SG_ PH_KD_Fehler : 63|1@1+ (1,0) [0|1] "" Gateway_PQ35

BO_ 1353 Parkhilfe_02: 8 XXX
 SG_ PL_Luecke_P0_x : 0|15@1+ (2,-32767) [-32767|32767] "Unit_CentiMeter" Gateway_PQ35
 SG_ PL_Luecke_P0_y : 15|15@1+ (2,-32767) [-32767|32767] "Unit_CentiMeter" Gateway_PQ35
 SG_ PL_Luecke_P2_x : 30|15@1+ (2,-32767) [-32767|32767] "Unit_CentiMeter" Gateway_PQ35
 SG_ PL_Luecke_P2_y : 45|15@1+ (2,-32767) [-32767|32767] "Unit_CentiMeter" Gateway_PQ35

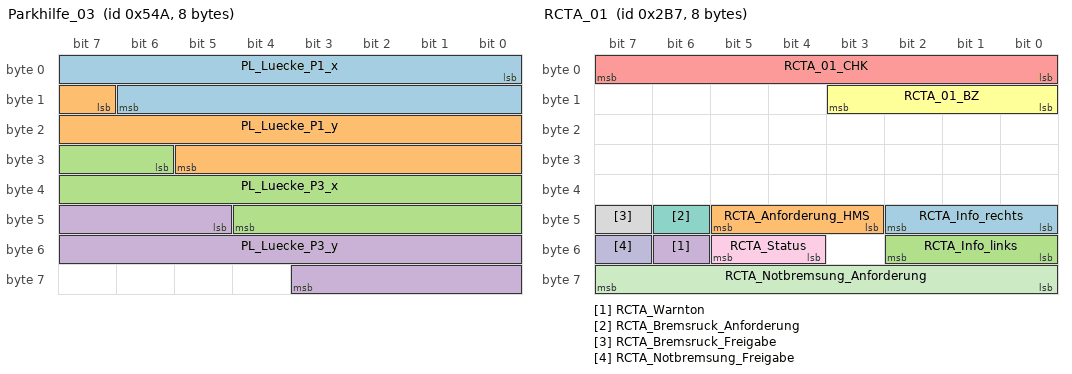
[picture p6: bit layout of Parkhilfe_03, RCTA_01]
BO_ 1354 Parkhilfe_03: 8 XXX
 SG_ PL_Luecke_P1_x : 0|15@1+ (2,-32767) [-32767|32767] "Unit_CentiMeter" Gateway_PQ35
 SG_ PL_Luecke_P1_y : 15|15@1+ (2,-32767) [-32767|32767] "Unit_CentiMeter" Gateway_PQ35
 SG_ PL_Luecke_P3_x : 30|15@1+ (2,-32767) [-32767|32767] "Unit_CentiMeter" Gateway_PQ35
 SG_ PL_Luecke_P3_y : 45|15@1+ (2,-32767) [-32767|32767] "Unit_CentiMeter" Gateway_PQ35

BO_ 695 RCTA_01: 8 XXX
 SG_ RCTA_Info_rechts : 40|3@1+ (1,0) [0|7] "" XXX
 SG_ RCTA_Anforderung_HMS : 43|3@1+ (1,0) [0|5] "" XXX
 SG_ RCTA_Info_links : 48|3@1+ (1,0) [0|7] "" XXX
 SG_ RCTA_Warnton : 54|1@1+ (1,0) [0|1] "" PDC_PLA
 SG_ RCTA_01_CHK : 0|8@1+ (1,0) [0|255] "" Bremse_ESP_EPB_EBC460Vi,Bremse_MK60EC,ESP_AU316
 SG_ RCTA_01_BZ : 8|4@1+ (1,0) [0|15] "" Bremse_ESP_EPB_EBC460Vi,Bremse_MK60EC,ESP_AU316
 SG_ RCTA_Bremsruck_Anforderung : 46|1@1+ (1,0) [0|1] "" Bremse_ESP_EPB_EBC460Vi,Bremse_MK60EC,ESP_AU316
 SG_ RCTA_Bremsruck_Freigabe : 47|1@1+ (1,0) [0|1] "" Bremse_ESP_EPB_EBC460Vi,Bremse_MK60EC,ESP_AU316
 SG_ RCTA_Status : 52|2@1+ (1,0) [0|3] "" Bremse_ESP_EPB_EBC460Vi,Bremse_MK60EC,ESP_AU316,PDC_PLA
 SG_ RCTA_Notbremsung_Freigabe : 55|1@1+ (1,0) [0|1] "" Bremse_ESP_EPB_EBC460Vi,Bremse_MK60EC,ESP_AU316
 SG_ RCTA_Notbremsung_Anforderung : 56|8@1+ (0.078,-19.812) [-19.734|0] "Unit_MeterPerSeconSquar" Bremse_ESP_EPB_EBC460Vi,Bremse_MK60EC,ESP_AU316

BO_ 2033 Req_Airbag_Deployment: 8 XXX
 SG_ Req_Airbag_Deployment : 0|64@1+ (1,0) [0|0] "" Airbag

BO_ 2041 Resp_Airbag_Deployment: 8 XXX
 SG_ Resp_Airbag_Deployment : 0|64@1+ (1,0) [0|0] "" Gateway_PQ35

BO_ 427 ESP_33: 8 XXX
 SG_ ESC_AHW_aktiv : 12|3@1+ (1,0) [0|7] "" Gateway_PQ35,PDC_PLA
 SG_ ESC_AHW_nicht_verfuegbar : 15|1@1+ (1,0) [0|1] "" Gateway_PQ35,PDC_PLA
 SG_ ESC_ANB_CM_aktiv : 16|2@1+ (1,0) [0|1] "" Gateway_PQ35
 SG_ ESC_ANB_CM_nicht_verfuegbar : 18|1@1+ (1,0) [0|1] "" Gateway_PQ35
 SG_ ESC_TSK_SRBM_Anf : 28|1@1+ (1,0) [0|1] "" Gateway_PQ35
 SG_ ESC_TSK_SRBM_nicht_verfuegbar : 29|1@1+ (1,0) [0|1] "" Gateway_PQ35
 SG_ ESC_Bremslicht_unplausibel : 37|1@1+ (1,0) [0|1] "" Gateway_PQ35
 SG_ ESC_Konsistenz_ARA : 40|1@1+ (1,0) [0|1] "" Gateway_PQ35
 SG_ ESC_Konsistenz_IPA : 41|1@1+ (1,0) [0|1] "" Gateway_PQ35,PDC_PLA
 SG_ ESC_Konsistenz_FCW : 42|1@1+ (1,0) [0|1] "" Gateway_PQ35
 SG_ ESC_Konsistenz_NV : 43|1@1+ (1,0) [0|1] "" Gateway_PQ35
 SG_ ESC_Konsistenz_TSK : 45|1@1+ (1,0) [0|1] "" Gateway_PQ35
 SG_ ESC_Konsistenz_vFGS : 46|1@1+ (1,0) [0|1] "" Gateway_PQ35
 SG_ ESC_Konsistenz_STA : 47|1@1+ (1,0) [0|1] "" Gateway_PQ35
 SG_ ESC_Konsistenz_EA : 49|1@1+ (1,0) [0|1] "" Gateway_PQ35
 SG_ ESC_Konsistenz_BFF : 50|1@1+ (1,0) [0|1] "" Gateway_PQ35,PDC_PLA
 SG_ ESC_Verz_ASIL_Verfuegbarkeit : 52|3@1+ (1,0) [0|7] "" Gateway_PQ35
 SG_ ESC_Pumpenanlauf_aktiv : 55|1@1+ (1,0) [0|1] "" Gateway_PQ35
 SG_ ESC_Konsistenz_AGW : 56|1@1+ (1,0) [0|1] "" Gateway_PQ35
 SG_ ESC_Konsistenz_KAS : 57|1@1+ (1,0) [0|1] "" Gateway_PQ35
 SG_ ESC_Konsistenz_PCF : 58|1@1+ (1,0) [0|1] "" Gateway_PQ35
 SG_ ESP_33_CHK : 0|8@1+ (1,0) [0|255] "" Gateway_PQ35,PDC_PLA
 SG_ ESP_33_BZ : 8|4@1+ (1,0) [0|15] "" Gateway_PQ35,PDC_PLA
 SG_ ESC_Warnruck_aktiv : 19|4@1+ (1,0) [0|9] "" Gateway_PQ35
 SG_ ESC_Warnruck_nicht_verfuegbar : 23|1@1+ (1,0) [0|1] "" Gateway_PQ35
 SG_ ESC_Prefill_aktiv : 24|1@1+ (1,0) [0|1] "" Gateway_PQ35,PDC_PLA
 SG_ ESC_Prefill_nicht_verfuegbar : 25|1@1+ (1,0) [0|1] "" Gateway_PQ35
 SG_ ESC_HBA_aktiv : 26|1@1+ (1,0) [0|1] "" Gateway_PQ35
 SG_ ESC_HBA_nicht_verfuegbar : 27|1@1+ (1,0) [0|1] "" Gateway_PQ35
 SG_ ESC_Verz_Reg_aktiv : 30|4@1+ (1,0) [0|15] "" Gateway_PQ35,PDC_PLA
 SG_ ESC_Verz_Reg_nicht_verfuegbar : 34|1@1+ (1,0) [0|1] "" Gateway_PQ35,PDC_PLA
 SG_ ESC_Verz_Reg_TB_nicht_verfuegbar : 35|1@1+ (1,0) [0|1] "" Gateway_PQ35
 SG_ ESC_Verz_Reg_ZB_nicht_verfuegbar : 36|1@1+ (1,0) [0|1] "" Gateway_PQ35
 SG_ ESC_Konsistenz_ACC : 38|1@1+ (1,0) [0|1] "" Gateway_PQ35
 SG_ ESC_Konsistenz_AWV : 39|1@1+ (1,0) [0|1] "" Gateway_PQ35
 SG_ ESC_Konsistenz_RCTA : 44|1@1+ (1,0) [0|1] "" Gateway_PQ35
 SG_ ESC_Fahrer_Bremsdruck_bestimmend : 48|1@1+ (1,0) [0|1] "" Gateway_PQ35,PDC_PLA
 SG_ ESC_Konsistenz_MKB : 51|1@1+ (1,0) [0|1] "" Gateway_PQ35

BO_ 1091 mBremse_RKA: 6 XXX
 SG_ RKA_Prio1_Warnung : 0|1@1+ (1,0) [0|1] "" Gateway_PQ35
 SG_ RKA_Prio2_Warnung : 1|1@1+ (1,0) [0|1] "" Gateway_PQ35
 SG_ RDK_Status : 8|1@1+ (1,0) [0|1] "" Gateway_PQ35
 SG_ RDK_neue_Solldruecke : 10|1@1+ (1,0) [0|1] "" Gateway_PQ35
 SG_ RKA_KD_Fehler : 15|1@1+ (1,0) [0|1] "" Gateway_PQ35
 SG_ RDK_Sensor_Multiplex : 16|3@1+ (1,0) [0|4] "" Gateway_PQ35
 SG_ RDK_xx_Status_Sensor : 19|1@1+ (1,0) [0|1] "" Gateway_PQ35
 SG_ RDK_xx_Color : 20|2@1+ (1,0) [0|2] "" Gateway_PQ35
 SG_ RDK_xx_Ist_Temp : 24|8@1+ (1,-60) [-60|194] "Unit_DegreCelsi" Gateway_PQ35
 SG_ RDK_xx_Ist_Druck : 32|6@1+ (0.1,0) [0|6.3] "Unit_Bar" Gateway_PQ35
 SG_ RDK_xx_Soll_Druck : 40|6@1+ (0.1,0) [0|6.3] "Unit_Bar" Gateway_PQ35
 SG_ RKA_Warnungen : 2|4@1+ (1,0) [0|15] "" Gateway_PQ35
 SG_ RKA_FMVSS_138_Warnung : 6|1@1+ (1,0) [0|1] "" AppGW_SK,Gateway_PQ35
 SG_ RKA_FMVSS_138_MIL : 7|1@1+ (1,0) [0|1] "" Gateway_PQ35
 SG_ RKA_Ack_IstZu_Solldruecke : 9|1@1+ (1,0) [0|1] "" Gateway_PQ35
 SG_ RKA_Menue : 11|1@1+ (1,0) [0|1] "" Gateway_PQ35
 SG_ RKA_Akustik : 22|1@1+ (1,0) [0|1] "" Gateway_PQ35

BO_ 1472 mEPB_1: 8 XXX
 SG_ EP1_QualNeigWi : 44|1@1+ (1,0) [0|1] "" Gateway_PQ35
 SG_ EP1_Zaehler : 0|4@1+ (1,0) [0|15] "" Bremse_MK60EC,Daempfer,Gateway_PQ35,Motor_Diesel,Motor_Otto
 SG_ EP1_Fehler_Sta : 4|2@1+ (1,0) [0|3] "" Bremse_MK60EC,Gateway_PQ35,PDC_PLA
 SG_ EP1_Sta_EPB : 6|1@1+ (1,0) [0|1] "" Bremse_MK60EC,Gateway_PQ35,Getriebe_DL800_R8,Getriebe_DQ,Getriebe_DQ_Hyb,Motor_Diesel,Motor_Otto,PDC_PLA
 SG_ EP1_Sta_Schalter : 7|1@1+ (1,0) [0|1] "" Gateway_PQ35,Motor_Diesel,Motor_Otto
 SG_ EP1_Spannkraft : 8|5@1+ (1,0) [0|30] "Unit_KiloNewto" Bremse_MK60EC,Gateway_PQ35,Getriebe_DL800_R8,Getriebe_DQ,Getriebe_DQ_Hyb
 SG_ EP1_Schalterinfo : 13|2@1+ (1,0) [0|3] "" Bremse_MK60EC,Gateway_PQ35,Getriebe_DQ,Getriebe_DQ_Hyb,Motor_Diesel,Motor_Otto
 SG_ EP1_Sta_NWS : 15|1@1+ (1,0) [0|1] "" Gateway_PQ35,Motor_Diesel,Motor_Otto
 SG_ EP1_Neig_winkel : 16|8@1+ (1,-128) [-128|127] "Unit_PerCentOfForceOfGravi" Gateway_PQ35,Motor_Diesel,Motor_Otto
 SG_ EP1_Verzoegerung : 24|8@1+ (0.048,-7.968) [-7.968|4.224] "Unit_MeterPerSeconSquar" Bremse_MK60EC,Daempfer,Gateway_PQ35
 SG_ EP1_Fehlereintr : 32|1@1+ (1,0) [0|1] "" Gateway_PQ35
 SG_ EP1_Freigabe_Ver : 33|1@1+ (1,0) [0|1] "" Bremse_MK60EC,Daempfer,Gateway_PQ35,Motor_Diesel,Motor_Otto
 SG_ EP1_AutoHold_zul : 34|1@1+ (1,0) [0|1] "" Gateway_PQ35
 SG_ EP1_AutoHold_aktiv : 35|1@1+ (1,0) [0|1] "" Gateway_PQ35,Motor_Diesel,Motor_Otto
 SG_ EP1_SleepInd : 36|1@1+ (1,0) [0|1] "" Gateway_PQ35
 SG_ EP1_Status_Kl_15 : 37|1@1+ (1,0) [0|1] "" Gateway_PQ35
 SG_ EP1_Lampe_AutoP : 38|1@1+ (1,0) [0|1] "" Gateway_PQ35
 SG_ EP1_Bremslicht : 39|1@1+ (1,0) [0|1] "" Gateway_PQ35
 SG_ EP1_Warnton1 : 40|1@1+ (1,0) [0|1] "" Gateway_PQ35
 SG_ EP1_Warnton2 : 41|1@1+ (1,0) [0|1] "" Gateway_PQ35
 SG_ EP1_AnfShLock : 42|1@1+ (1,0) [0|1] "" Gateway_PQ35
 SG_ EPB_Autoholdlampe : 43|1@1+ (1,0) [0|1] "" Gateway_PQ35
 SG_ EP1_KuppModBer : 45|2@1+ (1,0) [0|3] "" Gateway_PQ35,Motor_Diesel,Motor_Otto
 SG_ EP1_HydrHalten : 47|1@1+ (1,0) [0|1] "" Gateway_PQ35,Getriebe_DL800_R8,Getriebe_DQ,Getriebe_DQ_Hyb,Motor_Diesel,Motor_Otto
 SG_ EP1_Fkt_Lampe : 48|1@1+ (1,0) [0|1] "" Bremse_MK60EC,Gateway_PQ35
 SG_ EP1_Warnton : 49|1@1+ (1,0) [0|1] "" Gateway_PQ35
 SG_ EP1_Fehler_BKL : 50|1@1+ (1,0) [0|1] "" Gateway_PQ35
 SG_ EP1_Fehler_gelb : 51|1@1+ (1,0) [0|1] "" Gateway_PQ35
 SG_ EP1__Text : 52|4@1+ (1,0) [0|8] "" Gateway_PQ35,Getriebe_DL800_R8,Getriebe_DQ,Getriebe_DQ_Hyb
 SG_ EP1_Checksum : 56|8@1+ (1,0) [0|255] "" Bremse_MK60EC,Daempfer,Gateway_PQ35,Motor_Diesel,Motor_Otto

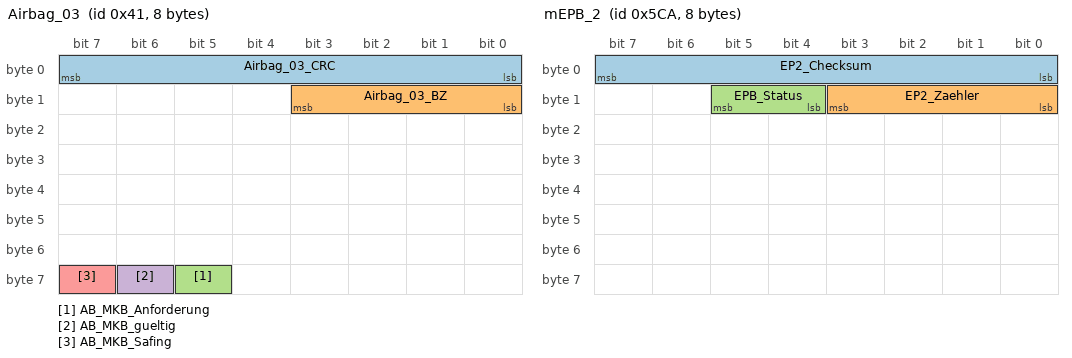
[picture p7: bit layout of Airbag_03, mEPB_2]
BO_ 65 Airbag_03: 8 XXX
 SG_ Airbag_03_CRC : 0|8@1+ (1,0) [0|255] "" Bremse_ESP_EPB_EBC460Vi,Bremse_MK100_ESC,Bremse_MK60EC,ESP_AU316
 SG_ Airbag_03_BZ : 8|4@1+ (1,0) [0|15] "" Bremse_ESP_EPB_EBC460Vi,Bremse_MK100_ESC,Bremse_MK60EC,ESP_AU316
 SG_ AB_MKB_Anforderung : 61|1@1+ (1,0) [0|1] "" Bremse_ESP_EPB_EBC460Vi,Bremse_MK100_ESC,Bremse_MK60EC,ESP_AU316
 SG_ AB_MKB_gueltig : 62|1@1+ (1,0) [0|1] "" Bremse_ESP_EPB_EBC460Vi,Bremse_MK100_ESC,Bremse_MK60EC,ESP_AU316
 SG_ AB_MKB_Safing : 63|1@1+ (1,0) [0|1] "" Bremse_ESP_EPB_EBC460Vi,Bremse_MK100_ESC,Bremse_MK60EC,ESP_AU316

BO_ 1658 BAP_Anzeige_02: 8 XXX
 SG_ BAP_Data_Anzeige_02 : 0|16@1+ (1,0) [0|65535] "" Bremse_ESP_EPB_EBC460Vi,ESP_AU316,Motor_Hybrid,PDC_PLA

BO_ 1750 BAP_Debug_Cmd: 8 XXX
 SG_ BAP_Data_Debug_Cmd : 0|16@1+ (1,0) [0|65535] "" Bremse_ESP_EPB_EBC460Vi,ESP_AU316,HCA,Motor_Hybrid,PDC_PLA

BO_ 1811 ISO_ABS_Req: 8 XXX
 SG_ ISO_ABS_Req_Data : 0|64@1+ (1,0) [0|0] "" Bremse_ESP_EPB_EBC460Vi,Bremse_MK100_ESC

BO_ 1792 ISO_Funktionaler_Req_All: 8 XXX
 SG_ ISO_ALL_01_Req_Data : 0|64@1+ (1,0) [0|0] "" AFS,Airbag,Allrad,BMS_Hybrid,Bremse_ESP_EPB_EBC460Vi,Bremse_MK100_ESC,EPB_TRW_VW411CS,FLA,Getriebe_AG6,Getriebe_DL800_R8,Getriebe_DL800_ZSG_R8,Getriebe_DQ,Getriebe_DQ_Hyb,Getriebe_Sele,Gurtmikro_PQ35,LEH_Hybrid,LH_EPS_ZF_3G,Motor_Diesel,Motor_Hybrid,Motor_Otto,PDC_PLA

BO_ 1751 BAP_Debug_Data: 8 XXX
 SG_ BAP_Debug_Data : 0|64@1+ (1,0) [0|0] "" BAP_Tester

BO_ 1771 BAP_RDK_02: 8 XXX
 SG_ BAP_Data_RDK_02 : 0|16@1+ (1,0) [0|65535] "" XXX

BO_ 1917 ISO_ABS_Resp: 8 XXX
 SG_ ISO_ABS_Resp_Data : 0|64@1+ (1,0) [0|0] "" Gateway_PQ35

BO_ 1482 mEPB_2: 8 XXX
 SG_ EP2_Checksum : 0|8@1+ (1,0) [0|255] "" Motor_Diesel,Motor_Otto
 SG_ EP2_Zaehler : 8|4@1+ (1,0) [0|15] "" Motor_Diesel,Motor_Otto
 SG_ EPB_Status : 12|2@1+ (1,0) [0|3] "" Motor_Diesel,Motor_Otto

CM_ SG_ 1186 TSK_Wunschgeschw "Zur Anzeige der Wunschgeschwindigkeit von GRA/Speedlimiter im Kombiinstrument";
CM_ SG_ 1186 TSK_Texte_Primaeranz "Trigger fuer Anzeigetexte von GRA und Limiter, GRA Temporaeranzeige (Audi) und Limiter Warnungen | | 0 keine Anzeige | 1 GRA Symbol passiv xxx km/h / mph (nur Audi) | 2 GRA Symbol aktiv xxx km/h / mph (nur Audi) | 3 Bremse ueberhitzt ! (reserv.) | 4 Limiter Modus aktiviert | 5 GRA Modus aktiviert | 6 ACC Modus aktiviert | 7 Optische Geschwindigkeitswarnung | 8 Optische und akustische Geschwindigkeitswarnung, dauerhaft (Ueberschreiten, NCAP) | 9 Optische Geschwindigkeitswarnung, dauerhaft mit einmaliger Akustik zu Beginn (Uebertreten) | 10 Limiter passiv mit Akustik (reserv.) | 11 Limiter Fehler mit Akustik (Popup + 1x Gong) | 12 Limiter Symbol passiv xxx km/h / mph (reserv. Audi) | 13 Limiter Symbol aktiv xxx km/h (reserv. Audi) | 14 Popup Geschwindigkeit zu hoch, Resume unzulaessig | 15...32 reserviert";
CM_ SG_ 1186 TSK_Limiter_Fahrerinfo "Fahrerhinweise und Warnungen des Speedlimiters";
CM_ SG_ 1186 TSK_Limiter_Anzeige "Signalisiert den Wunsch des MSG an das Kombiinstrument, seine Anzeige auf Limiter umzuschalten";
CM_ SG_ 1186 TSK_Status_Anzeige "Signalisiert den Status von GRA oder Limiter zur Anzeige im Kombiinstrument. | Der Signalwert \"Limitierung_aktiv\" wird nur verwendet fuer den Audi Speedlimiter und zeigt bei aktivier Funktion an, dass nahe an der Abregelgeschwindigkeit gefahren wird und die Limitierung greift.";
CM_ SG_ 1343 SCR_Zustand "Zustand des SCR Systems, der an das Kombi/MMI uebermittelt wird";
CM_ SG_ 1343 SCR_Retriggersignal "Trigger zur Erneuerung der SCR Kombibotschaft";
CM_ SG_ 1343 SCR_Nachfuellmenge_min "Minimal erforderliche Nachfuellmenge, damit eine Betankung erkannt wird";
CM_ SG_ 1343 SCR_Nachfuellmenge_max "Maximales Volumen, mit dem der SCR Tank nachbefuellt werden kann.";
CM_ SG_ 1343 SCR_Nachfuellmenge_Einheit "Laenderspezifische Einheit der min/max Nachfuellmenge (Liter/Gallone US/Gallone UK)";
CM_ SG_ 1343 SCR_Tankvolumen "Volumen des verbauten SCR Tanks. Dimension abhaengig von Signal SCR_Nachfuellmenge_Einheit.";
CM_ SG_ 1343 SCR_Einheit "Laenderspezifische Einheit der Restreichweite (km oder mi)";
CM_ SG_ 1343 SCR_Fuellstand "Minimal erforderliche Nachfuellmenge, damit eine Betankung erkannt wird";
CM_ SG_ 1343 SCR_Restreichweite "Minimal erforderliche Nachfuellmenge, damit eine Betankung erkannt wird";
CM_ SG_ 1160 MO6_Checksum "Pruefsumme mit Endwert 0x0, Definition im CAN Lastenheft (HS-CAN V4.2a, LS-CAN V1.42)";
CM_ SG_ 1160 MO6_SollM_Getr "Sollmoment ohne P und D Anteil des Leerlaufreglers, ohne Antiruckelfunktion und ohne Getriebeeingriff | (nicht PL71-Hybrid) | Sollmoment fuer Getriebe";
CM_ SG_ 1160 MO6_Ist_Moment "Istmoment ohne P und D Anteil des Leerlaufreglers, ohne Antiruckelfunktion und ohne Getriebeeingriff | | Hybrid: | EM-Momente muessen beruecksichtigt werden. Soll bei kleiner Dynamik und Abwesenheit langfristiger Eingriffe identisch sein zu innerem Moment oE (Motor 1). | Unterschiede existieren je nach Motorstand, ob langfristige Eingriffe enthalten sind | Istmoment fuer Getriebe";
CM_ SG_ 1160 MO6_Hoeheninfo "Korrekturfaktor Hoehe (1 entspricht 1013 mbar; 0,9 entspricht 1000m; 0,8 entspricht 2000m; 1,1 entspricht -1000m) | (Korrekturfaktor linear skaliert: delta Hoehe 1000m entsprechen delta Druck 101,3 mbar)";
CM_ SG_ 1160 MO6_GRA_Soll "Die im Motor-SG integrierte GRA gibt hier eine 'gesteuerte' Soll-Beschleunigung aus | FEH = GRA aus | FFH = nicht erlaubt | GRA Sollbeschleunigung";
CM_ SG_ 1160 MO6_MomIntGeEing "Nur fuer Getriebe mit 'alter' Momentenschnittstelle: | 100 % entspricht volle Verfuegbarkeit aktuell vorhanden. | 0 % entspricht Integral bis Limit gefuellt, erhoehender Eingriff kann aktuell nicht beruecksichtigt werden oder erhoehender Eingriff ist in diesem Projekt nicht moeglich (applikativ deaktiviert) oder aufgrund eines Fehlers nicht verfuegbar. | | Hybrid: | Ueberwachungsfunktion (E-Gassicherheit) muss um E-Maschinenanteile erweitert werden. Getriebe soll nur eine \"Tasse Diesel\" sehen. | Rueckmeldung Momentenintegral Getriebeeingriff";
CM_ SG_ 1160 MO6_FF_Mux00 "Uebertragung von Messgroessen an das Getriebesteuergeraet fuer Freeze Frame Abspeicherung bei Getriebefehlern (nur NAR) | Calculated Load Value (PID $04)";
CM_ SG_ 1160 MO6_FF_Mux01 "Uebertragung von Messgroessen an das Getriebesteuergeraet fuer Freeze Frame Abspeicherung bei Getriebefehlern (nur NAR) | Absolute Throttle Position (PID $11)";
CM_ SG_ 1160 MO6_FF_Mux02 "Uebertragung von Messgroessen an das Getriebesteuergeraet fuer Freeze Frame Abspeicherung bei Getriebefehlern (nur NAR) | Engine Coolant Temperature (PID $05)";
CM_ SG_ 1160 MO6_FF_Mux03 "Uebertragung von Messgroessen an das Getriebesteuergeraet fuer Freeze Frame Abspeicherung bei Getriebefehlern (nur NAR) | Absolute Load Value (PID $43)";
CM_ SG_ 1160 MO6_FF_Mux04 "Uebertragung von Messgroessen an das Getriebesteuergeraet fuer Freeze Frame Abspeicherung bei Getriebefehlern (nur NAR) | Accelerator Pedal Position D (PID $49)";
CM_ SG_ 1160 MO6_FF_Mux05 "Uebertragung von Messgroessen an das Getriebesteuergeraet fuer Freeze Frame Abspeicherung bei Getriebefehlern (nur NAR)";
CM_ SG_ 1160 MO6_FF_Mux06 "Uebertragung von Messgroessen an das Getriebesteuergeraet fuer Freeze Frame Abspeicherung bei Getriebefehlern (nur NAR)";
CM_ SG_ 1160 MO6_FF_Mux07 "Uebertragung von Messgroessen an das Getriebesteuergeraet fuer Freeze Frame Abspeicherung bei Getriebefehlern (nur NAR)";
CM_ SG_ 1160 MO6_FF_Mux08 "Uebertragung von Messgroessen an das Getriebesteuergeraet fuer Freeze Frame Abspeicherung bei Getriebefehlern (nur NAR)";
CM_ SG_ 1160 MO6_FF_Mux09 "Uebertragung von Messgroessen an das Getriebesteuergeraet fuer Freeze Frame Abspeicherung bei Getriebefehlern (nur NAR)";
CM_ SG_ 1160 MO6_FF_Mux10 "Uebertragung von Messgroessen an das Getriebesteuergeraet fuer Freeze Frame Abspeicherung bei Getriebefehlern (nur NAR)";
CM_ SG_ 1160 MO6_FF_Mux11 "Uebertragung von Messgroessen an das Getriebesteuergeraet fuer Freeze Frame Abspeicherung bei Getriebefehlern (nur NAR)";
CM_ SG_ 1160 MO6_FF_Mux12 "Uebertragung von Messgroessen an das Getriebesteuergeraet fuer Freeze Frame Abspeicherung bei Getriebefehlern (nur NAR)";
CM_ SG_ 1160 MO6_FF_Mux13 "Uebertragung von Messgroessen an das Getriebesteuergeraet fuer Freeze Frame Abspeicherung bei Getriebefehlern (nur NAR)";
CM_ SG_ 1160 MO6_FF_Mux14 "Uebertragung von Messgroessen an das Getriebesteuergeraet fuer Freeze Frame Abspeicherung bei Getriebefehlern (nur NAR)";
CM_ SG_ 1160 MO6_FF_Mux15 "Uebertragung von Messgroessen an das Getriebesteuergeraet fuer Freeze Frame Abspeicherung bei Getriebefehlern (nur NAR)";
CM_ SG_ 1160 MO6_Freigabe_GRA "Sollbeschleunigung bzw. Bremseeingriff in Byte 5 freigegeben (zukuenftig Entfall geplant) | GRA-Bremseingriff-Freigabe";
CM_ SG_ 1160 MO6_Schutz_Toel "Bei einer Toel > 150degC wird das Uebertemperaturschutzbit dann gesetzt und das Getriebe schaltet vom 4. Gang in den 5. Gang bei Vmax. Bei einer Toel < 125degC wird dieses Bit zurueck gesetzt und das Getriebe schaltet dann bei Vmax vom 5. Gang wieder in den 4. Gang zurueck. (nur D2GP mit 2 MSG-Konzept) | Bei einer Ueberschreitung der Kuehlmitteltemperaturschwelle wird das Uebertemperaturschutz-Bit als Hochschaltaufforderung an das Getriebe gesetzt (neu im D1/Colorado und PQ35/46) | Oeltemperaturschutz / Uebertemperaturschutz";
CM_ SG_ 1160 MO6_Luftpfad_akt "Getriebeeingriff wird zusaetzlich zum Zuendungspfad auch ueber den Luftpfad umgesetzt (nur VW D1) | Luftpfad aktiv";
CM_ SG_ 1160 MO6_RegPartikel "Fuer die Partikelfilterregeneration wird das Getriebe aufgefordert, ein drehzahlintensiveres Schaltprogramm zu aktivieren (Nur EDC16C Audi D3 / Audi C6!) / VW D1/Colorado/ PQ35/46) | (Z. Zt.: Mindestdrehzahl im Getriebe appliziert; Zuk. geplant: Uebertragung der Mindestdrehzahl in Motor 3, Byte 7) | Getriebeeingriff Partikelfilterregeneration";
CM_ SG_ 1160 MO6_Zaehler "Botschaftszaehler zur Erkennung fehlender und veraltetet Botschaften, Definition im CAN-Lastenheft";
CM_ SG_ 1162 MO8_Checksumme "Pruefsumme mit Endwert 0x0, Definition im CAN Lastenheft (HS-CAN V4.2a, LS-CAN V1.42)";
CM_ SG_ 1162 MO8_AnzeigeDZ "Optimierte Anzeigedrehzahl | | Im VW361/7, VW360/7, VW120/7 wird das Signal als Powermeter genutzt: | 0 ... 4092, Faktor 1 | 0 = Unteres Ende Bremsen/grau; | 340 = Unteres Ende CHARGE; | 1020 = READY; | 1870 = Oberes Ende EFFICIENCY; | 3400 = 100%; | 4080 = MAX; | 4093 = Init/OFF";
CM_ SG_ 1162 MO_Effizienzmodus "Bei Handschaltern wird das Fahrprogramm Effizienz signalisiert.";
CM_ SG_ 1162 MO8_SGT_Soundakt "Ansteuerung des Stellgliedtest Soundaktuator (AU716, TTNF)";
CM_ SG_ 1162 MO8_Spoiler_ausf "Spoiler ausfahren";
CM_ SG_ 1162 MO8_Sportschalter "nur AU714 | Sportschalter";
CM_ SG_ 1162 MO8_LampeDZBegr "Im Audi RS/4 und AU714 | Lampe Drehzahlbegrenzung";
CM_ SG_ 1162 MO8_Enable_Oeldr_Motor "Schaltet die interne Oeldruckauswertung im Kombiinstrument ab und aktiviert die Auswertung des Bits \"Oeldr_Warn_Motor\"";
CM_ SG_ 1162 MO8_Oeldr_Warn_Motor "Loest im Kombiinstrument die rote Prio1-Oeldruckwarnung (inkl. 3xBeep) aus; die Warnausloesung erfolgt nur bei gleichzeitig gesetztem \"Enable_Oeldr_Motor\"";
CM_ SG_ 1162 MO8_Avus_Motorschutz "Warntexte zum Kombi fuer den Fall des Avus-Notlauf. Priowarnung, kann parallel mit anderen Warnungen im Mitteldisplay angezeigt werden.";
CM_ SG_ 1162 MO8_Anzeigecode "Info, wie MO8_AnzeigeDZ zu interpretieren ist";
CM_ SG_ 1162 MO_P_verriegelt "Signal stellt den Status des Signals p_verriegelt auf den Fahrzeugbus zur Verfuegung. | Nutzer ist die Funktion Verlassenswarnung im Kombi, die den Fahrer vorm Verrollen des Fahrzeugs warnt.";
CM_ SG_ 1162 MO8_GRA_v_Wunsch "Wunschgeschwindigkeit GRA vom Motor an Kombi zur Anzeige im Mitteldisplay (nicht AU714)";
CM_ SG_ 1162 MO_Schaltempf_verfbar "Info, ob Schaltempfehlung im Fzg. in mMotor_8 verfuegbar. Statischer Wert, aendert sich fuer ein Fzg. nicht!";
CM_ SG_ 1162 MO8_Nachlauf_ZWP "Die Zusatzwasserpumpe soll bei Kl. 15 aus (Nachlauf) die erhoehte Temperatur im Motorraum bei Bedarf noch abfuehren koennen. (nur Audi)";
CM_ SG_ 1162 MO_Istgang "Aktueller Gang fuer Anzeige Hochschaltempfehlung (gueltig, wenn MO_Schaltempf_verfbar = 1). | | Anzeige im Kombi: | Sollgang == Istgang ==> Anzeige Istgang | Sollgang != Istgang ==> Schaltempfehlung | Sollgang == Istgang == 0 ==> keine Anzeige";
CM_ SG_ 1162 MO_Sollgang "Motor sendet den Sollgang in den der Fahrer schalten soll. Wird im Kombi als Hochschaltempfehlung hervorgehoben (gueltig, wenn MO_Schaltempf_verfbar = 1). | | Anzeige im Kombi: | Sollgang == Istgang ==> Anzeige Istgang | Sollgang != Istgang ==> Schaltempfehlung | Sollgang == Istgang == 0 ==> keine Anzeige | Sollgang == 15 ==> Schaltempfehlung in N";
CM_ SG_ 1162 MO8_Zaehler "Definition nach CAN-Lastenheft";
CM_ SG_ 1800 MC1_Anz_Betrieb "Kombiinstrument zeigt die Gasbetriebsart an | Motor steuert die Anzeige mit diesem Bit | Blinken der Anzeige wird durch Setzen und Loeschen des Bits nachgebildet (z.B. wenn der Fahrer auf leeren Gastank schalten will) | Betriebsart fuer Anzeige";
CM_ SG_ 1800 MC1_Schalter "In diesem Bit wird die Schalterstellung ausgegeben (nicht fuer die Anzeige im Kombi !) | Anmerkung: die aktuelle Betriebsart kann von der eingestellten abweichen | Betriebsart Schalterstellung";
CM_ SG_ 1800 MC1_akt_Betrieb "Motor faehrt mit Benzin oder Gas | Aktuelle Betriebsart";
CM_ SG_ 1800 MC1_CNG_LPG "0 Es gilt MC1_Verbrauch | 1 Es gilt MC1_Verbrauch_LPG und MO_LPG_Tankstopp";
CM_ SG_ 1800 MO_LPG_Tankstopp "Der im LPG-SG integrierte Tankalgorithmus hat einen Tankstopp (LPG-Tank) erkannt.";
CM_ SG_ 1800 MO_Erdgasqualitaet "Erdgas-Qualitaet abgestuft in 70%, 80%, 90% und 100% (bei CNG bezogen auf 100% Methan). | Berechnung erfolgt einmalig nach jeder Betankungserkennung.";
CM_ SG_ 1800 MC1_Fuellungsgrad "Gefilterter temperaturkompensierter Gasdruckwert als Prozentwert vom Maximalwert wird im Kombi als Zeiger dargestellt | Fuellungsgrad CNG und LPG";
CM_ SG_ 1800 MC1_Verbrauch "Motor-Steuergeraet interner Verbrauchszaehler, der vom Kombi zyklisch ausgelesen wird, um die Gasmenge zur Verbrauchsberechnung aufzusummieren; aus diesem Zaehlerstand werden Momentan- und Durchschnitts-verbrauch berechnet; das Ueberlauf-Bit (Byte 4, Bit 7) ist zu beruecksichtigen | CNG-Verbrauchssignal";
CM_ SG_ 1800 MC1_Verbrauch_LPG "Motor-Steuergeraet interner Verbrauchszaehler, der vom Kombi zyklisch ausgelesen wird, um die Gasmenge zur Verbrauchsberechnung aufzusummieren; aus diesem Zaehlerstand werden Momentan- und Durchschnitts-verbrauch berechnet; das Ueberlauf-Bit (Byte 4, Bit 7) ist zu beruecksichtigen | LPG-Verbrauchssignal";
CM_ SG_ 1800 MC1_Ueb_Verbr "Der Motor-Steuergeraet interne Verbrauchszaehler ist mindestens einmal uebergelaufen. Dieses Bit wird genutzt, um erkennen zu koennen, dass das Motorsteuergeraet aus dem Reset-Zustand hochlaeuft | Erdgasverbrauch-Ueberlauf";
CM_ SG_ 1800 MO_AnzeigeGasbetrieb "Anzeige des Betriebszustands bei Umschaltung zwischen Gas- und Benzinbetrieb";
CM_ SG_ 1800 MO_Gastemperatur "Gastemperatur im Kraftstoff-Rail zur Anzeige in der MFA";
CM_ SG_ 1800 MO_Verbrauchsaequivalent "Faktor zur Umrechnung des aktuellen/letzten Verbrauchs im LPG/CNG-Betrieb auf einen aequivalenten Benzin-Verbrauch (zur Ermittlung der Gesamtreichweite)";
CM_ SG_ 1562 MEV1_Checksumme "Pruefsumme mit Endwert 0x0, Definition im CAN Lastenheft (HS-CAN V4.2a, LS-CAN V1.42)";
CM_ SG_ 1562 MEV1_Zaehler "Botschaftszaehler, Definition im CAN-Lastenheft";
CM_ SG_ 1562 MO_Red_FahrleistungsLampe "Ansteuerung der Turtle-Mode Lampe fuer E-Traktion Fahrzeuge";
CM_ SG_ 1562 Ladestecker_gesteckt "Signalisiert ein gestecktes Ladekabel.";
CM_ SG_ 1562 Ladevorgang_aktiv "Signalisiert einen aktiven Ladevorgang. Ladegeraete und DC/DC-Wandler aktiv.";
CM_ SG_ 1562 HV_Bordnetz_aktiv "Signalisiert ein aktives Hochvoltbordnetz. HV-Schuetze geschlossen. Im Fehlerfall wird das Bit nicht gesetzt.(Klemmende Schuetze)";
CM_ SG_ 1562 HV_Bordnetz_A_Status "Status Aktivierung HV_Bordnetz. Abbruchursache HV-Bordnetz bei Kl.15 aus. | 0 = Kl.15 aus. HV-Bordnetz kann aktiviert werden | 1 = Kl.15 ein. Aktivierung nur fuer Sofortladung oder bei Fahrbereitschaft | 2 = Keine Aktivierung: Schluessel erkannt | 3 = Keine Aktivierung: Wegrollsperre nicht aktiviert | 4 = Keine Aktivierung: Fzg-Geschwindigkeit > 0km/h | 5 = Keine Aktivierung: Pedal betaetigt | 6 = Keine Aktivierung: DWA ausgeloest | 7 = Keine Aktivierung: Warnblinker aktiv | 8 = Keine Aktivierung: Fehler HV-Netz | 9 = Keine Aktivierung: Ladezustand / Netzversorgung";
CM_ SG_ 1562 HV_PTC_LeistRed "Anforderung an die Klimasteuerung, die Leistungsaufnahme des HV-PTC bei schlechtem SOC und in bestimmten Fahrsituationen zu begrenzen. | (Das bereits bestehende Signal \"Klimakompressor aus\" Motor5, Byte2, Bit5 als stets umzusetzende Anforderung bleib)";
CM_ SG_ 1562 HV_PTC_aus "MSG schaltet HV-PTC aus";
CM_ SG_ 1562 Ladestecker_verr_Status "Signalisiert einen verriegelten Ladestecker";
CM_ SG_ 1562 HV_Anf_ReichweiteNV "Mit diesem Signal kann von der Hochvoltseite bei kritischem Energieinhalt der HV - Batterie ein Beitrag (kundenmerkbar!) aus der Niedervoltseite gefordert werden, um noch eine Ladestelle zu erreichen.";
CM_ SG_ 1562 MO_Wahl_Pos "Waehlhebelposition | (Im VW120/7 ist der Waehlhebel am Sub/Hybrid-CAN des Motors angeschlossen)";
CM_ SG_ 1562 QB_Ladestecker_gesteckt "Definition nach CAN-Lastenheft | Qualifizierungsbit zu \"Ladestecker_gesteckt\".";
CM_ SG_ 1562 MO_Fehler_Notabschaltung_Klima "Das Signal dient der schnellen Abschaltung der Klimakomponenten (EKK, HV-Heizung) durch den HV-Koordinator (MSG) nach einem HV-Interlock Ereignis.";
CM_ SG_ 1562 QB_Ladezustand_HV_Batterie "Definition nach CAN-Lastenheft | Qualifizierungsbit zu \"Ladezustand_HV_Batterie\".";
CM_ SG_ 1562 BMS_Temperierung_Anf "Temperierungsbedarf der HV-Batterie";
CM_ SG_ 1562 Energieinhalt_HV_Batt "Effektiv nutzbarer Energieinhalt der Hochvoltbatterie";
CM_ SG_ 1562 Ladezustand_HV_Batterie "Aktueller Ladezustand der HV-Batterie in %. (SOC)";
CM_ SG_ 1154 MH1_VM_Mom_oE "Verbrenner-Fahrmoment abzueglich Verbrenner-Verlustmoment. Vorzeichenbehaftet. | Fuer Benutzung in Getriebe-Schaltstrategie | Verbrenner-Moment ohne Eingriff";
CM_ SG_ 1154 MH1_IstStatusK0 "Status 'offen' muss eine voll geoeffnete Kupplung sicherstellen. | Ist-Status K0";
CM_ SG_ 1154 MH1_Startmodus_PQ35 "Hybridsteuerung (MSG) zeigt an, auf welche Weise gestartet werden soll (nur PQ35 Hybrid) | Startmodus Impuls / Direkt PQ35";
CM_ SG_ 1154 MH1_VM_aktiv "0 = VMotor wird nicht aktiv gehalten (nVM < n_min und keine LL-Regelung aktiv) | 1 = VMotor aktiv (ab der ersten Einspritzung; gilt auch fuer Schubbetrieb, wenn VMotor spaetestens durch LL-Regelung befeuert wuerde) | Verwendung zur Bestimmung des Ist-Zustandes";
CM_ SG_ 1154 MH1_Zielzustand_Hybrid "Ziel - Hybrid-Betriebszustaende";
CM_ SG_ 1154 MH1_Schaltverh "Schaltungen werden an den DZ-Grenzen (Nullgas-Schaltdrehzahl und Kickdown-Schaltdrehzahl) ausgefuehrt | Schaltverhinderung";
CM_ SG_ 1154 MH1_VerlParam_Msum "Wenn Byte 7, Bit 4 = 1 (GRA/ACC aktiv), erhalten in Abhaengigkeit von den Bits 1, 0 (Byte 3) die Bits 7..2 (Byte 3) folgende Bedeutung: | Bit 1,0 =00: max. umsetzbares langfr. Rekup-Moment | Bit 1,0 =01: Knickdrehzahl d. langfr. Rekup-Kurve | Bit 1,0 =10: max. verfuegbares langfr. pos. EM-Moment | Bit 1,0 =11: Knickdrehzahl d. langfristigen pos. EM-Kurve | Selektor Momentenverlauf EM";
CM_ SG_ 1154 MH1_MomVerlauf_EM "Wenn Byte 7, Bit 4 = 1 (GRA/ACC aktiv): | Momentenverlaufsinformation EM | Umrechnung: | M = 315/63 * i Nm (i = unsigned int der 6 Bits), wenn Byte 3, Bit 1,0 = 0 oder 2 | N = 3150/63 * i min-1 (i = unsigned int der 6 Bits) , wenn Byte 3, Bit 1,0 = 1 oder 3";
CM_ SG_ 1154 MH1_E_Faktor "Wenn Byte 7, Bit 4 = 0 (GRA/ACC nicht aktiv): E-Faktor. | Signed Nibble (Zweierkomplement), verwendet vom GSG zur Interpolation zwischen VM-Kennfeld und dem Rekuperations-Grenzkennfeld (negative Werte des E-Faktors) bzw. dem Boost-Grenzkennfeld (positive Werte des E-Faktors). | 0000 = VM-Kennfeld (keine Interpolation) | 0001..0111 = dez +1..+7 Interpolation zwischen VM-Kennfeld und Boost-Kennfeld | 1000..1111 = dez -8..-1 Interpolation zwischen VM-Kennfeld und Rekup.-Kennfeld | E-Faktor";
CM_ SG_ 1154 MH1_Drehzahl_VM "fuer OBD freeze frame | Drehzahl Verbrennungsmotor";
CM_ SG_ 1154 MH1_max_ind_VM_Mom "inneres maximal moegliches VM-Moment bei einer Drehzahl (z. B. Rauchbegrenzung oder Fehlerfall). | Verwendet von GSG bei GRA/ACC-Betrieb | Max. moegliches indiziertes VM-Moment";
CM_ SG_ 1154 MH1_Notstart "Kennzeichnung eines Notstarts zur sofortigen Ansteuerung der K0 durch das Getriebe";
CM_ SG_ 1154 MH1_LowSpeedModus "MSG legt fest: | 0 = klassisches Ausrollen/Anfahren mit N_mot >= N_Leerlauf_VM | 1 = elektr. Ausrollen/Anfahren mit geschl. Triebstrang mit N_mot < N_Leerlauf_VM | Low-Speed-Modus";
CM_ SG_ 1154 MH1_ACCGRA_aktiv "Zeigt an, ob GRA/ACC aktiv ist. | Wird zusammen mit Byte 3 / Bits 1..0 als Selektor fuer die Bedeutung der Bits 7..2 (Byte 3) benutzt";
CM_ SG_ 1154 MH1_EMode_Info "Hybrid-Mode der Motorsteuerung zur Beeinflussung der Schaltkennfelder im Getriebe. Nicht-Hybridfahrzeuge senden den Initwert.";
CM_ SG_ 1154 MH1_QB_Bremspedalwert "Qualifizierungsbit nach CAN-LH";
CM_ SG_ 1154 MH1_Bremspedalwert "Bremspedalwegsensor vom Motor eingelesen";
CM_ SG_ 1823 MSI_KD_Fehler "Info fuer Diagnose; bei gesetztem Bit befindet sich mindestens ein Kundendienstfehler im Fehlerspeicher des Motorslave";
CM_ SG_ 1428 NI2_Checksum "Pruefsumme mit Endwert 0x0, Definition im CAN Lastenheft (HS-CAN V4.2a, LS-CAN V1.42)";
CM_ SG_ 1428 NI2_Zaehler "Freilaufender Botschaftszaehler";
CM_ SG_ 1428 NI2_Hoehenflag "legt fest, wie die Hoehenwerte in Byte 3-6 interpretiert werden muessen";
CM_ SG_ 1428 NI2_Hoehe_VL "aktueller Hoehensensorwert vorne links | 0x7F entspricht NN | im Audi C6, VW D1 ungefiltertes Signal";
CM_ SG_ 1428 NI2_Hoehe_VL_Roh "aktueller Hoehensensorwert vorne links, ungefiltert, Rohwert";
CM_ SG_ 1428 NI2_Hoehe_VR "aktueller Hoehensensorwert vorne rechts | 0x7F entspricht NN | im Audi C6, VW D1 ungefiltertes Signal";
CM_ SG_ 1428 NI2_Hoehe_VR_Roh "aktueller Hoehensensorwert vorne rechts, ungefiltert, Rohwert";
CM_ SG_ 1428 NI2_Hoehe_HL "aktueller Hoehensensorwert hinten links | 0x7F entspricht NN | im Audi C6, VW D1 ungefiltertes Signal";
CM_ SG_ 1428 NI2_Hoehe_HL_Roh "aktueller Hoehensensorwert hinten links, ungefiltert, Rohwert";
CM_ SG_ 1428 NI2_Hoehe_HR "aktueller Hoehensensorwert hinten rechts | 0x7F entspricht NN | im Audi C6, VW D1 ungefiltertes Signal";
CM_ SG_ 1428 NI2_Hoehe_HR_Roh "aktueller Hoehensensorwert hinten rechts, ungefiltert, Rohwert";
CM_ SG_ 1428 NI2_AufbBeschl_VL "Aufbaubeschleunigung VL | (fuer aktive Wankstabilisierung)";
CM_ SG_ 1428 NI2_AufbBeschl_VR "Aufbaubeschleunigung VR | (fuer aktive Wankstabilisierung)";
CM_ SG_ 1349 PA3_System_codierung "0 = 4 Kanal PDC | 1 = 8 Kanal PDC | | Bei VW: | 0 = hinten | 1 = Vorn und Hinten | | 8/4-Kanal-Anlage";
CM_ SG_ 1349 PA3_Anlage_defekt "1 = PDC wurde aufgrund eines Defektes deaktiviert | Anlage defekt";
CM_ SG_ 1349 PA3_Taster_aktiviert "1 = Anlage wurde manuell ueber Einschalttaster aktiviert | Aktivierung durch Taster (Nur 8-Kanal)";
CM_ SG_ 1349 PA3_Rueckwaertsgang_aktiv "1 = Anlage wurde durch Einlegen des Rueckwaertsgangs aktiviert";
CM_ SG_ 1349 PA3_Geschwindigkeit_aus "1 = Durch Erreichen von vMax PDC wurde die PDC abgeschaltet";
CM_ SG_ 1349 PA3_Tongeber_v_defekt "1 = Tongeber Vorne ist defekt";
CM_ SG_ 1349 PA3_Tongeber_h_defekt "1 = Tongeber Hinten ist defekt";
CM_ SG_ 1349 PA3_Audioabsenkung_Anforderung "1= Anforderung an das Audiosystem fuer Absenkung der Lautstaerke";
CM_ SG_ 1349 PA3_Eis_aus "1 = Wegen erkanntem Eis auf den Sensoren wurde die PDC abgeschaltet";
CM_ SG_ 1349 PA3_Schlechtweg_aus "1 = Aufgrund von signalisierten Schlechtweginformationen wurde die PDC abgeschaltet";
CM_ SG_ 1349 PA3_KD_Fehler "1 = mindestens ein Fehler ist im Kundendienstfehlerspeicher eingetragen";
CM_ SG_ 1349 PA3_Sensor_hll_defekt "0 = Sensor OK / 1 = Sensor defekt | Sensor hinten links links defekt";
CM_ SG_ 1349 PA3_Sensor_hlm_defekt "0 = Sensor OK / 1 = Sensor defekt | Sensor hinten links mitte defekt";
CM_ SG_ 1349 PA3_Sensor_hrm_defekt "0 = Sensor OK / 1 = Sensor defekt | Sensor hinten rechts mitte defekt";
CM_ SG_ 1349 PA3_Sensor_hrr_defekt "0 = Sensor OK / 1 = Sensor defekt | Sensor hinten rechts rechts defekt";
CM_ SG_ 1349 PA3_Sensor_vll_defekt "0 = Sensor OK / 1 = Sensor defekt | Sensor vorn links links defekt";
CM_ SG_ 1349 PA3_Sensor_vlm_defekt "0 = Sensor OK / 1 = Sensor defekt | Sensor vorn links mitte defekt";
CM_ SG_ 1349 PA3_Sensor_vrm_defekt "0 = Sensor OK / 1 = Sensor defekt | Sensor vorn rechts mitte defekt";
CM_ SG_ 1349 PA3_Sensor_vrr_defekt "0 = Sensor OK / 1 = Sensor defekt | Sensor vorn rechts rechts defekt";
CM_ SG_ 1349 PA3_Bereit "1 = PDC ist Betriebsbereit und kann aktiviert werden";
CM_ SG_ 1349 PA3_Bereich_vo "0 = Initwert (Ausserhalb Gefahrenbereich) | 1 = Vorwarnbereich nur NFZ | 2 = Hauptwarnbereich | 3 = Kollisionsbereich | Bereichserkennung vorn";
CM_ SG_ 1349 PA3_Bereich_hi "0 = Initwert (Ausserhalb Gefahrenbereich) | 1 = Vorwarnbereich nur NFZ | 2 = Hauptwarnbereich | 3 = Kollisionsbereich | Bereichserkennung hinten";
CM_ SG_ 1349 PA3_Akust_aus "1 = Tonausgabe der ParkDistanceControll manuell abgeschaltet | Akustische Ausgabe der PDC abschalten";
CM_ SG_ 1349 PA3_Aufbau_erk "Aufbauten erkannt";
CM_ SG_ 1355 PA5_VL_Abstand "FFh = kein Hindernis im Erfassungsbereich | Abstand vorne links";
CM_ SG_ 1355 PA5_VR_Abstand "FFh = kein Hindernis im Erfassungsbereich | Abstand vorne rechts";
CM_ SG_ 1355 PA5_HL_Abstand "FFh = kein Hindernis im Erfassungsbereich | Abstand hinten links";
CM_ SG_ 1355 PA5_HR_Abstand "FFh = kein Hindernis im Erfassungsbereich | Abstand hinten rechts";
CM_ SG_ 1355 PA5_VML_Abstand "FFh = kein Hindernis im Erfassungsbereich | Abstand vorne mitte links";
CM_ SG_ 1355 PA5_VMR_Abstand "FFh = kein Hindernis im Erfassungsbereich | Abstand vorne mitte rechts";
CM_ SG_ 1355 PA5_HML_Abstand "FFh = kein Hindernis im Erfassungsbereich | Abstand hinten mitte links";
CM_ SG_ 1355 PA5_HMR_Abstand "FFh = kein Hindernis im Erfassungsbereich | Abstand hinten mitte rechts";
CM_ SG_ 1166 PLA_Status_Aktive_Seite "Anzeige der zu parkenden Seite";
CM_ SG_ 1166 PLA_Anf_Anzeige_Mini "Laut MQB 28.09.2012: Init-Wert auf 0 gesetzt; Kommentar angepasst;";
CM_ SG_ 1166 PLA_Mini_Modus "Art des vom PLA zur Darstellung angeforderten Minis. Wird angezeigt, wenn PLA_Anf_Anzeige_Mini=1.";
CM_ SG_ 1166 PLA_Anf_Akustik "Anzeige, ob das PLA einen Gong im Kombi anfordert, Gong soll mit dem Uebergang 0->1 abgespielt werden.";
CM_ SG_ 1166 PLA_Anf_Anzeige_Schwellpfeil "Anzeige, ob PLA im Kombi den Schwellpfeil zur Darstellung der Restwegstrecke im aktuellen Zug anfordert";
CM_ SG_ 1166 PLA_Anf_Anzeige_Bremsfuss "Anzeige, ob PLA die Anzeige eines Bremsfusses anfordert";
CM_ SG_ 1166 PLA_Anf_Funktionsdisclaimer "Anforderung des Funktionsdisclaimer durch PLA";
CM_ SG_ 1166 PLA_Anf_Anzeigemodus "Anzeigemodus das vom PLA je nach Parkszenario beim Kombi angefordert wird";
CM_ SG_ 1166 PLA_Anf_Meldungen "Anforderung der Meldungen: | 0 - Keine Meldung | 1-127 niederprio. Meldungen | 128-255 hochprio. Meldungen";
CM_ SG_ 1166 PLA_Anzahl_Segmente_Schwellpfeil "Wird ein Schwellpfeil angezeigt, gibt dieses Signal die Laenge des breiten Balkens in Anzahl der Segmente (max. Laenge: 15 Segmente). | | Wird keine Anzeige der Schwellpfeile angefordert, muss die Anzahl Segmente 0 sein.";
CM_ SG_ 1166 PLA_Status_Funktion "Funktionsstati, die die einzelnen Schritte innerhalb eines Parkszenarios anzeigen.";
CM_ SG_ 1166 PLA_Status_beenden_Mini "Status Anzeige beendet Mini";
CM_ SG_ 1166 PLA_Status_Laengsparken_Mini "Status Anzeige Laengsparken Mini";
CM_ SG_ 1166 PLA_Status_QP_Rueckw_Mini "Status Anzeige Querparken rueckwaerts Mini";
CM_ SG_ 1166 PLA_Status_QP_Vorw_Mini "Status Anzeige Querparken vorwaerts Mini";
CM_ SG_ 714 QS2_Ist_Wert "Aktuell eingestelltes Kupplungs-(Sperr-)Moment";
CM_ SG_ 714 QS2_Soll_Wert "Bei Fremdsteuerung durch ESP erscheint hier der Wunschsperrgrat, den die Sperre ohne ESP einstellen wuerde. | Im unbeeinflussten Fall sind Ist- und Sollwert identisch";
CM_ SG_ 714 QS2_Status_VAQ "Statusmaschine: VAQ Status";
CM_ SG_ 714 QS2_Gleichlauf "Dient der Qualifizierung des Ist-Sperrmoments, da dieses nicht waehrend Gleichlauf berechnet werden kann";
CM_ SG_ 714 QS2_KD_Fehler "Bei gesetztem Bit ist mindestens ein Kundendienstfehler eingetragen";
CM_ SG_ 1437 RSF_Tastencode_1 "Uebertragung des FFB-Tastencode Remotestart zum MSG, damit MSG unabhaengig vom BCM den Remotestart-Befehl auswerten kann.";
CM_ SG_ 1437 RSF_Tastencode_2 "Uebertragung des FFB-Tastencode Remotestart zum MSG, damit MSG unabhaengig vom BCM den Remotestart-Befehl auswerten kann.";
CM_ SG_ 1437 RSF_Tastencode_Maske "Uebertragung des FFB-Tastencode Remotestart zum MSG, damit MSG unabhaengig vom BCM den Remotestart-Befehl auswerten kann.";
CM_ SG_ 16 MSG1_WFS_RND "Zufallszahl Anfrage";
CM_ SG_ 20 MSG2_WFS_RND "Zufallszahl Anfrage";
CM_ SG_ 22 MSG3_WFS_RND "Zufallszahl Anfrage";
CM_ SG_ 24 MSG4_WFS_RND "Zufallszahl Anfrage";
CM_ SG_ 1306 TOG_Zaehler "Zaehler wird mit jeder Botschaft inkrementiert";
CM_ SG_ 1306 TOG_Fuellstand_1 "Fuellstand im ersten Zeitfenster";
CM_ SG_ 1306 TOG_Fuellstand_2 "Fuellstand im zweiten Zeitfenster";
CM_ SG_ 1306 TOG_Fuellstand_3 "Fuellstand im dritten Zeitfenster";
CM_ SG_ 1306 TOG_Fuellstand_4 "Fuellstand im vierten Zeitfenster";
CM_ SG_ 1306 TOG_Oeltempzeit "Oeltemperaturzeit aus max. 4 Zeitfenstern";
CM_ SG_ 1306 TOG_Sensorfehler "Sensorfehler";
CM_ SG_ 1306 TOG_Oelwarn_hoch "Oelwarnschwelle plus Offset ueberschritten | (wird in mKombi_2 verwendet, falls bei WIV3.2 der TOG-Sensor nicht direkt am Kombi angeschlossen ist, siehe mKombi_2, Byte 1, Bit 1)";
CM_ SG_ 1306 TOG_OelwarnUeber "nur fuer WIV 3.1 im Audi C6 | Oelwarnschwelle ueberschritten";
CM_ SG_ 1306 TOG_OelmaxUeber "nur fuer WIV 3.1 im Audi C6 | Maximums-Oelfuellstand ueberschritten";
CM_ SG_ 1306 TOG_Oelmax_hoch "nur fuer WIV 3.1 im Audi C6 | Maximums-Oelfuellstand plus Offset ueberschritten";
CM_ SG_ 1937 TPDyn_ABS_2 "ABS | TP 2.0 Empfangskanal 2 fuer ABS_SG";
CM_ SG_ 1904 TPDyn_ADR_1 "ADR | TP 2.0 Empfangskanal 1 fuer ADR_SG";
CM_ SG_ 1896 TPDyn_Airbag_1 "Airbag | TP 2.0 Empfangskanal 1 fuer Airbag_SG";
CM_ SG_ 1906 TPDyn_Daempfer_1 "Daempfer | TP 2.0 Empfangskanal 1 fuer Daempfer_SG | | Verwendet auch als ISO Request fuer Daempfer_SG";
CM_ SG_ 1940 TPDyn_EPB_1 "EPB | TP 2.0 Empfangskanal 1 fuer EPB_SG";
CM_ SG_ 1864 TPDyn_FLA_1 "Quersperre | TP 2.0 Empfangskanal 1 fuer FLA_SG";
CM_ SG_ 1888 TPDyn_Getriebe_1 "Getriebe | TP 2.0 Empfangskanal 1 fuer Getriebe_SG";
CM_ SG_ 1889 TPDyn_Getriebe_2 "Getriebe | TP 2.0 Empfangskanal 2 fuer Getriebe_SG";
CM_ SG_ 1956 TPDyn_LDW_1 "LDW | TP 2.0 Empfangskanal fuer LDW_SG";
CM_ SG_ 1957 TPDyn_LDW_2 "LDW | TP 2.0 Empfangskanal fuer LDW_SG";
CM_ SG_ 1960 TPDyn_Lenkhilfe_1 "Lenkhilfe | TP 2.0 Empfangskanal 1 fuer Lenkhilfe_SG";
CM_ SG_ 1961 TPDyn_Lenkhilfe_2 "Lenkhilfe | TP 2.0 Empfangskanal 2 fuer Lenkhilfe_SG";
CM_ SG_ 1924 TPDyn_Dyn_LWR_1 "Dyn_LWR | TP 2.0 Empfangskanal 1 fuer Dyn_LWR_SG";
CM_ SG_ 1925 TPDyn_Dyn_LWR_2 "Dyn_LWR | TP 2.0 Empfangskanal 2 fuer Dyn_LWR_SG";
CM_ SG_ 1952 TPDyn_LWS "LWS | TP 2.0 Empfangskanal fuer Lenkwinkelsensor";
CM_ SG_ 1856 TPDyn_Motor_1 "Motor | TP 2.0 Empfangskanal 1 fuer Motor_SG";
CM_ SG_ 1857 TPDyn_Motor_2 "Motor | TP 2.0 Empfangskanal 2 fuer Motor_SG";
CM_ SG_ 1858 TPDyn_Motor_3 "Motor | TP 2.0 Empfangskanal 3 fuer Motor_SG";
CM_ SG_ 1859 TPDyn_Motor_4 "Motor | TP 2.0 Empfangskanal 4 fuer Motor_SG";
CM_ SG_ 1978 TPDyn_PLA_PDC "PLA_PDC | TP 2.0 Empfangskanal fuer PLA_SG";
CM_ SG_ 1880 TPDyn_Quersperre_1 "Quersperre | TP 2.0 Empfangskanal 1 fuer Quersperre_SG";
CM_ SG_ 1881 TPDyn_Quersperre_2 "Quersperre | TP 2.0 Empfangskanal 2 fuer Quersperre_SG";
CM_ SG_ 1875 TPDyn_RKA_Plus_2 "RKA_Plus | TP 2.0 Empfangskanal 2 fuer RKA_Plus";
CM_ SG_ 1920 TPDyn_WFS_1 "Wegfahrsperre, Diagnose | TP 2.0 Empfangskanal 1 fuer Wegfahrsperre";
CM_ SG_ 1921 TPDyn_WFS_2 "Wegfahrsperre, Kommunikation Anlernen | TP 2.0 Empfangskanal 1 fuer Wegfahrsperre";
CM_ SG_ 523 ADR_TP_Er "TP 2.0 Eroeffnungskanal";
CM_ SG_ 517 Airbag_TP_Er "TP 2.0 Eroeffnungskanal";
CM_ SG_ 522 Allrad_TP_Er "TP 2.0 Eroeffnungskanal";
CM_ SG_ 524 Daempfer_TP_Er "TP 2.0 Eroeffnungskanal";
CM_ SG_ 537 EPB_TP_Er "TP 2.0 Eroeffnungskanal";
CM_ SG_ 534 FLA_TP_Er "TP 2.0 Eroeffnungskanal";
CM_ SG_ 514 Getriebe_TP_Er "TP 2.0 Eroeffnungskanal";
CM_ SG_ 538 LDW_TP_Er "TP 2.0 Eroeffnungskanal";
CM_ SG_ 521 Lenkhilfe_TP_Er "TP 2.0 Eroeffnungskanal";
CM_ SG_ 518 Dyn_LWR_TP_Er "TP 2.0 Eroeffnungskanal";
CM_ SG_ 531 LWS_TP_Er "TP 2.0 Eroeffnungskanal";
CM_ SG_ 533 Mot_Slave_1_TP_Er "TP 2.0 Eroeffnungskanal";
CM_ SG_ 513 Motor_TP_Er "TP 2.0 Eroeffnungskanal";
CM_ SG_ 541 PLA_PDC_TP_Er "TP 2.0 Eroeffnungskanal";
CM_ SG_ 536 Quersperre_TP_Er "TP 2.0 Eroeffnungskanal";
CM_ SG_ 520 RKA_Plus_TP_Er "TP 2.0 Eroeffnungskanal";
CM_ SG_ 532 WFS_TP_Er "Wegfahrsperre | TP 2.0 Eroeffnungskanal";
CM_ SG_ 1096 WH1_StaShiftlock "Status der Shiftlockansteuerung | Shiftlock aktiv bedeutet, der Shiftlockmagnet wird so angesteuert, dass die mechanische Verriegelung greifen wuerde, wenn die entsprechende Position des Waehlhebels vorliegen wuerde. Dies kann bedeuten, stromlos verriegelt oder bestromt verriegelt. | Die Bits geben den Status der Shiftlockansteuerung seitens des Waehlhebelmoduls wieder, falls die Ansteuerung durch das Waehlhebelmodul erfolgt. Andernfalls wird der Initwert 000b versendet";
CM_ SG_ 1096 WH1_Init "Das Bit zeigt dem Empfaenger an, dass der Waehlhebel in der Initialisierung war (z.B. Reset). Das Signal steht fuer 500ms ab Sendebeginn auf 1, danach dauerhaft auf 0.";
CM_ SG_ 1096 WH1_Position "Die Codierung der Waehlhebelposition entspricht der Codierung in der Getriebe1 Botschaft";
CM_ SG_ 1096 WH1_Status "Das Waehlhebelmodul liefert aktuelle Fehlerzustaende. Die Fehlereintraege werden im Getriebesteuergeraet abgelegt. | 0 = fehlerfrei | 1 = Shiftlockfehler (wird aktuell im DQ nicht ausgewertet) | 2 = Reserve | 4 = Reserve | 8 = Reserve | 16 = Reserve (ZF: LED Fehler, wird im DQ aktuell nicht ausgewertet) | 32 = Einfacher Sensorfehler (wird aktuell im DQ nicht ausgewertet) | 64 = Einfacher Sensorfehler | 128 = Mehrfacher Sensorfehler";
CM_ SG_ 1096 WH1_Testergebnis "Ergebnis des Controllertests initiert durch Testfreigabeflag und Testparameter 1 + 2 aus Getriebe 4 | Hier wird in Verbindung mit dem 'Test aktiv Flag' das gueltige Testergebnis eines noch zu definierenden Frage- und Antwortspiels zur Ueberpruefung des Mikrokontrollers uebertragen. Die Aufgabenstellung erfolgt ueber die beiden Bytes 'Testparameter 1 + 2', sowie ueber das Bit 'Testfreigabeflag' in der exklusiv fuer den Waehlhebel gesendeten 'Getriebe 4' Botschaft. | Die Pruefung wird regelmaessig nach einer Zeit t_Test_delay nach jeder Waehlhebelbedienung durchgefuehrt.";
CM_ SG_ 1096 WH1_Zaehler "Freilaufender Botschaftszaehler | Dient der Synchronisierung der Getriebebotschaften und stellt sicher, dass der Waehlhebelrechner noch lebt, damit der Testmode nicht laenger wie zwei Zyklen (20ms) aktiviert ist.";
CM_ SG_ 1096 WH1_Test_Flag "Controllertestergebnis gueltig, Waehlhebelposition kann evtl. nicht aktuell sein | Test aktiv Flag (Waehlhebel 1)";
CM_ SG_ 1096 WH1_Taster_betaetigt "Waehlhebeltaster z.B. S-Taste betaetigt";
CM_ SG_ 1096 WH1_Position_inv "Bitweise Inverse Codierung der Waehlhebelposition aus Byte 1, Bit 7..4 | Bemerkungen zur Multiplex-Information: Shiftlock aktiv bedeutet, der Shiftlockmagnet wird so angesteuert, dass die mechanische Verriegelung greifen wuerde, wenn die entsprechende Position des Waehlhebels vorliegen wuerde. Dies kann bedeuten, stromlos verriegelt oder bestromt verriegelt. | Beim FSI mit DS-Getriebe soll der stromlos verriegelte Shift-Lock einsetzen. | Die Bits geben den Status der Shiftlockansteuerung seitens des Waehlhebelmoduls wieder, falls die Ansteuerung durch das Waehlhebelmodul erfolgt. Andernfalls wird der Initwert 000b versendet | Waehlhebelposition invers (Waehlhebel 1)";
CM_ SG_ 1102 WH2_Checksumme "Pruefsumme mit Endwert 0x0, Definition im CAN Lastenheft (HS-CAN V4.2a, LS-CAN V1.42)";
CM_ SG_ 1102 WH2_Zaehler "Freilaufender Botschaftszaehler | Dient der Synchronisierung der Getriebebotschaften und stellt sicher, dass der Waehlhebelrechner noch lebt, damit der Testmode nicht laenger wie zwei Zyklen (20ms) aktiviert ist.";
CM_ SG_ 1102 WH2_Init "Das Bit zeigt dem Empfaenger an, dass der Waehlhebel in der Initialisierung war (z.B. Reset). Das Signal steht fuer 500ms ab Sendebeginn auf 1, danach dauerhaft auf 0.";
CM_ SG_ 1102 WH2_Test_Flag "Controllertestergebnis gueltig, Waehlhebelposition kann evtl. nicht aktuell sein";
CM_ SG_ 1102 WH2_Sport "Das Bit zeigt an, dass der Fahrer den Sportmodus gewaehlt hat";
CM_ SG_ 1102 WH2_Winter "Das Bit zeigt an, dass der Fahrer den Wintermodus gewaehlt hat.";
CM_ SG_ 1102 WH2_Position "Waehlhebel mit zwei stabilen Positionen (X und U). Zwischen X und U liegt die Zwischenposition V. Von X kann nach R getippt werden, der Waehlhebel faellt danach zurueck in X. Von U kann nach +, - und D getippt werden.";
CM_ SG_ 1102 WH2_P_Taster "Anzeige, ob der P-Taster gedrueckt ist";
CM_ SG_ 1102 WH2_Ruhestromfehler "Die Waehlhebelelektronik enthaelt eine interne geschaltete Kl. 30 mit der die Hallsensoren versorgt werden. Bei Durchlegiertem Treiber werden die Hallsensoren dauerhaft versorgt, was zu einer erhoehten Ruhestromaufnahme fuehrt. In diesem Fall wird das Bit gesetzt.";
CM_ SG_ 1102 WH2_Sensorarray_Einfachfehler "Wird ein Einzelfehler im Sensorarray des Waehlhebels erkannt, so wird dieses Bit gesetzt. Seitens Getriebesteuergeraet erfolgt ein Fehlerspeichereintrag. Der Waehlhebel funktioniert normal weiter.";
CM_ SG_ 1102 WH2_Sensorarray_Mehrfachfehler "Wird ein Mehrfachfehler im Sensorarray des Waehlhebels erkannt, so wird dieses Bit gesetzt. Seitens Getriebesteuergeraet erfolgt ein Fehlerspeichereintrag. Der Waehlhebel wird deaktiviert. Im Kombstrument wird die Prioritaet 2 Warnmeldung \"Waehlhjebel defekt, kein R-Gang\" angezeigt.";
CM_ SG_ 1102 WH2_Fehler_Sporttaster "Wird eine Unterbrechung der Verbindung zum Sporttaster erkannt, so wird dieses Bit gesetzt. Seitens Getriebesteuergeraet erfolgt ein Fehlerspeichereintrag. Der Waehlhebel funktioniert normal. Aktivierung der Sportfunktion nicht moeglich.";
CM_ SG_ 1102 WH2_Fehler_Fahrstufenanzeige "Wird eine Falschausleuchtung der Getriebeposition am Waehlhebel detektiert (Kurzschluss oder Unterbrechung des entsprechenden LED Treibers), so wird dieses Bit gesetzt. Seitens Getriebesteuergeraet erfolgt ein Fehlerspeichereintrag. Der Waehlhebel funktioniert normal. Die Positionsanzeige am Waehlhebel wird bei Treiberunterbrechung abgeschaltet (keine Position ausgeleuchtet) und bei Treiberkurzschluss komplett eingeschaltet (alle Positionen ausgeleuchtet). | Anzeige im Waehlhebel defekt";
CM_ SG_ 1102 WH2_Fehler_Spannungsversorgung "Verlaesst die Versorgungsspannung den Bereich in dem ein stoerungsfreier Betrieb des Waehlhebels gesichert ist, so wird dieses Bit gesetzt. Seitens Getriebesteuergeraet erfolgt ein Fehlerspeichereintrag. Der Waehlhebel funktioniert normal. | Unter-/ Ueberspannungsfehler";
CM_ SG_ 1102 WH2_Timeout_Kombi_2 "Der Waehlhebel empfaengt vom Kombi das Signal Kl58d fuer den Dimmwert der Anzeige am Waehlhebel. Wird diese Botschaft nicht mehr empfangen, so wird der Dimmwert von der Hardware Kl58s verwendet. Ist auch Kl58s nicht verfuegbar wird der maximale Helligkeitswert eingestellt. Seitens Getriebesteuergeraet erfolgt ein Fehlerspeichereintrag. Der Waehlhebel funktioniert normal.";
CM_ SG_ 1102 WH2_Timeout_Getriebe_5 "Die Uebertragung der Waehlhebelposition an das Getriebesteuergeraet ist durch ein Frage-Antwort Spiel abgesichert, dass die korrekte Bedienung von Getriebe_5 und Waehlhebel_2 Botschaft voraussetzt. Fehlt die Botschalt Getriebe_5, so wird dieses Bit gesetzt. Der Waehlhebel wird deaktiviert, die Anzeige am Waehlhebel wird nicht mehr ausgeleuchtet. Seitens Getriebesteuergeraet erfolgt ein Fehlerspeichereintrag.";
CM_ SG_ 1102 WH2_Timeout_Gate_Komf_1 "Der Waehlhebel empfaengt aus der Gateway_Komfort_1 Botschaft das Sleep Acknowledge Bit zur Beendigung des Nachlaufes nach Kl. 15 AUS. Fehlt die Botschalt Gateway_Komfort_1, so wird dieses Bit gesetzt. Seitens Getriebesteuergeraet erfolgt ein Fehlerspeichereintrag. Der Waehlhebel funktioniert bis Kl.15 AUS normal. Nach Klemme 15 AUS wird der Waehlhebel nun 750ms nach dem Abschalten der Klemme 58s deaktiviert.";
CM_ SG_ 1102 WH2_Testergebnis "Ergebnis des Controllertests initiert durch Testfreigabeflag und Testparameter 1 + 2 aus Getriebe 5 | Hier wird in Verbindung mit dem 'Test aktiv Flag' das gueltige Testergebnis eines noch zu definierenden Frage- und Antwortspiels zur Ueberpruefung des Mikrokontrollers uebertragen. Die Aufgabenstellung erfolgt ueber die beiden Bytes 'Testparameter 1 + 2', sowie ueber das Bit 'Testfreigabeflag' in der exklusiv fuer den Waehlhebel gesendeten 'Getriebe 5'- Botschaft. | Die Pruefung wird regelmaessig nach einer Zeit t_Test_delay nach jeder Waehlhebelbedienung durchgefuehrt.";
CM_ SG_ 1394 ZA1_S_Kontakt "1 = Schluessel steckt | 0 = kein Schluessel im Zuendschloss, bzw. kein S-Kontakt | S-Kontakt (Schluessel steckt)";
CM_ SG_ 1394 ZA1_Klemme_15 "1 = Klemme 15 ein | 0 = Klemme 15 aus | Sollzustand | Klemme 15 (Zuendung ein)";
CM_ SG_ 1394 ZA1_Klemme_X "Sollzustand Klemme X (Startvorgang) | 0 = keine Spannung | 1 = Spannung vorhanden, entspricht Kl. 15 ausser im Startvorgang | Das Signal wird im VW47x nicht bedient";
CM_ SG_ 1394 ZA1_Klemme_50 "Sollzustand Klemme 50 (Starten) | 0 = Klemme 50 aus | 1 = Klemme 50 ein | Das Signal wird im VW47x nicht bedient";
CM_ SG_ 1394 ZA1_Klemme_P "1 = Klemme P ein (Parklichtstellung)";
CM_ SG_ 919 ZK5_Checksumme "Pruefsumme mit Endwert 0x0, Definition im CAN Lastenheft (HS-CAN V4.2a, LS-CAN V1.42)";
CM_ SG_ 919 ZK5_Zaehler "Botschaftszaehler zur Erkennung fehlender ZKE_5-Botschaften | Definition gemaess Lastenheft";
CM_ SG_ 919 ZK5_Endlage_ausgefahren "1 = Endlage erreicht | Spoiler in Endlage ausgefahren";
CM_ SG_ 919 ZK5_Endlage_eingefahren "1 = Endlage erreicht | Spoiler in Endlage eingefahren";
CM_ SG_ 919 ZK5_Status_Spoiler "Status Spoiler (Spiegelung des WL-Bits zum Kombi)";
CM_ SG_ 919 ZV_SafeFunktion_aktiv "Statusuebermittlung ob die Safe Funktion im Fzg. aktiv ist. Das Kombi benoetigt das Signal, um den Text Safelock aktiv anzuzeigen.";
CM_ SG_ 919 ZK5_VD_Endlage_geschl "Verdeck geschlossen und Endlage erreicht";
CM_ SG_ 919 ZK5_VD_Endlage_abgelegt "Verdeck geoeffnet und in Endlage abgelegt";
CM_ SG_ 919 ZK5_VD_Verbau "Verbau manuelles oder automatisches Verdeck";
CM_ SG_ 919 VIP_Freigabe "Vituelles Pedal ist freigeschaltet.";
CM_ SG_ 1523 OBD_TG_F_Status_1 "Fehlerstatus Tankfuellstandsgeber (OBD relevanter Sensor fuer Tankleckdiagnose) | 0 = kein Fehler / Init / nicht verbaut | 1 = KS- (Kurzschluss nach Masse -> Widerstand zu klein) | 2 = KS+ (nicht verwendet) | 3 = OC (Leitungsunterbrechung) (nicht verwendet) | 4 = OOR+ (out of range high) (nicht verwendet) | 5 = OOR- (out of range low) (nicht verwendet) | 6 = RC+ (Signal unplausibel hoch) (nicht verwendet) | 7 = RC- (Signal unplausibel niedrig) (nicht verwendet) | 8 = KS+/OC (Kurzschluss nach Plus / Leitungsunterbrechung -> Widerstand zu gross / Geberbruch) | 9 = KS-/OC (nicht verwendet) | 10 = KS-/KS+ (nicht verwendet) | 11 = KS-/KS+/OC (Allgemeiner elektrischer Fehler -> Geber defekt / Geber unplausibel) | 12 = frei | 13 = frei | 14 = frei | 15 = frei";
CM_ SG_ 1523 OBD_TG_F_Status_2 "Fehlerstatus Tankfuellstandsgeber (OBD relevanter Sensor fuer Tankleckdiagnose) | 0 = kein Fehler / Init / nicht verbaut | 1 = KS- (Kurzschluss nach Masse -> Widerstand zu klein) | 2 = KS+ (nicht verwendet) | 3 = OC (Leitungsunterbrechung) (nicht verwendet) | 4 = OOR+ (out of range high) (nicht verwendet) | 5 = OOR- (out of range low) (nicht verwendet) | 6 = RC+ (Signal unplausibel hoch) (nicht verwendet) | 7 = RC- (Signal unplausibel niedrig) (nicht verwendet) | 8 = KS+/OC (Kurzschluss nach Plus / Leitungsunterbrechung -> Widerstand zu gross / Geberbruch) | 9 = KS-/OC (nicht verwendet) | 10 = KS-/KS+ (nicht verwendet) | 11 = KS-/KS+/OC (Allgemeiner elektrischer Fehler -> Geber defekt / Geber unplausibel) | 12 = frei | 13 = frei | 14 = frei | 15 = frei";
CM_ SG_ 1523 OBD_TG_F_Status_3 "Fehlerstatus Tankfuellstandsgeber (OBD relevanter Sensor fuer Tankleckdiagnose) | 0 = kein Fehler / Init / nicht verbaut | 1 = KS- (Kurzschluss nach Masse -> Widerstand zu klein) | 2 = KS+ (nicht verwendet) | 3 = OC (Leitungsunterbrechung) (nicht verwendet) | 4 = OOR+ (out of range high) (nicht verwendet) | 5 = OOR- (out of range low) (nicht verwendet) | 6 = RC+ (Signal unplausibel hoch) (nicht verwendet) | 7 = RC- (Signal unplausibel niedrig) (nicht verwendet) | 8 = KS+/OC (Kurzschluss nach Plus / Leitungsunterbrechung -> Widerstand zu gross / Geberbruch) | 9 = KS-/OC (nicht verwendet) | 10 = KS-/KS+ (nicht verwendet) | 11 = KS-/KS+/OC (Allgemeiner elektrischer Fehler -> Geber defekt / Geber unplausibel) | 12 = frei | 13 = frei | 14 = frei | 15 = frei";
CM_ SG_ 1523 OBD_TG_F_Status_4 "Fehlerstatus Tankfuellstandsgeber (OBD relevanter Sensor fuer Tankleckdiagnose) | 0 = kein Fehler / Init / nicht verbaut | 1 = KS- (Kurzschluss nach Masse -> Widerstand zu klein) | 2 = KS+ (nicht verwendet) | 3 = OC (Leitungsunterbrechung) (nicht verwendet) | 4 = OOR+ (out of range high) (nicht verwendet) | 5 = OOR- (out of range low) (nicht verwendet) | 6 = RC+ (Signal unplausibel hoch) (nicht verwendet) | 7 = RC- (Signal unplausibel niedrig) (nicht verwendet) | 8 = KS+/OC (Kurzschluss nach Plus / Leitungsunterbrechung -> Widerstand zu gross / Geberbruch) | 9 = KS-/OC (nicht verwendet) | 10 = KS-/KS+ (nicht verwendet) | 11 = KS-/KS+/OC (Allgemeiner elektrischer Fehler -> Geber defekt / Geber unplausibel) | 12 = frei | 13 = frei | 14 = frei | 15 = frei";
CM_ SG_ 1523 OBD_TG_Sens_Rohwert_1 "Rohwert des Tankgebers, nur gefiltert (gleitender Mittelwert), Ausgabe im 500ms-Raster";
CM_ SG_ 1523 OBD_TG_Sens_Rohwert_2 "Rohwert des Tankgebers, nur gefiltert (gleitender Mittelwert), Ausgabe im 500ms-Raster";
CM_ SG_ 1523 OBD_TG_Sens_Rohwert_3 "Rohwert des Tankgebers, nur gefiltert (gleitender Mittelwert), Ausgabe im 500ms-Raster";
CM_ SG_ 1523 OBD_TG_Sens_Rohwert_4 "Rohwert des Tankgebers, nur gefiltert (gleitender Mittelwert), Ausgabe im 500ms-Raster";
CM_ SG_ 1175 PH_Freie_Weglaenge_Heck "Freie Weglaenge Heck. Die freie Weglaenge kann dabei durch Hindernisse oder den maximalen Sichtbereich beschraenkt sein. Siehe Signal Freie_Weglaenge_Heck_Typ";
CM_ SG_ 1175 PH_Freie_Weglaenge_Heck_Typ "Beschreibt die Begrenzung der freien Weglaenge hinter dem Fahrzeug. Gehoert somit zum Signal Freie_Weglaenge_Heck. Die freie Weglaenge kann bei einem gemessenen Objekt enden oder bei der maximalen Sensorreichweite.";
CM_ SG_ 1175 PH_nachtr_Stopp_Anf "Dieses Signal dient dem Motor als Trigger, dass ein nachtraeglicher Motorstopp eingeleitet werden kann, wenn es die Bedingungen des StSt Koordinators dies zulassen.";
CM_ SG_ 1175 PH_Abschaltursache "Abschaltursache bleibt bis zur naechsten Aktivierung bzw. bis KL15 aus gesetzt | 0 = keine, bzw. System aktiv | 1 = Abschaltung durch Herausnahme R-Gang | 2 = Abschaltung ueber Geschwindigkeit | 3 = Abschaltung ueber PDC-Taster | 4 = Abschaltung wegen PLA | 5 = Abschaltung durch Kl.15 Bit=0 | 7 = Fehler-/gestoert Zustand, System noch aktiv";
CM_ SG_ 1175 PH_Opt_Anzeige_V_ein "OPS vorne ist im Display aktiv bzw. Anzeigemodule vorne sind eingeschaltet | Optische Anzeige vorn aktiv";
CM_ SG_ 1175 PH_Opt_Anzeige_H_ein "OPS hinten ist im Display aktiv bzw. Anzeigemodule hinten sind eingeschaltet | Optische Anzeige hinten aktiv";
CM_ SG_ 1175 PH_Opt_Anz_V_Hindernis "mindestens 1 Segment wird fuer den vorderen Detekionsbereich dargestellt, also ein Hindernis ist im Detektionsbereich | Optische Anzeige vorn Hindernis";
CM_ SG_ 1175 PH_Opt_Anz_H_Hindernis "mindestens 1 Segment wird fuer den hinteren Detekionsbereich dargestellt, also ein Hindernis ist im Detektionsbereich | Optische Anzeige hinten Hindernis";
CM_ SG_ 1175 PH_Tongeber_V_aktiv "Rohsignal fuer \"Tongeber vorne wird angesteuert\", verlaengerbar mit Nachlauftimer | Tongeber vorn aktiv";
CM_ SG_ 1175 PH_Tongeber_H_aktiv "Rohsignal fuer \"Tongeber hinten wird angesteuert\", verlaengerbar mit Nachlauftimer | Tongeber hinten aktiv";
CM_ SG_ 1175 PH_Tongeber_mute "1 = Tongeber stummgeschaltet; | Tongeber Mute";
CM_ SG_ 1175 PH_Anf_Audioabsenkung "1 = Anforderung an das Audiosystem fuer Absenkung der Lautstaerke";
CM_ SG_ 1175 PH_Tongeber_H_verfuegbar "Tongeber ist fuer die Tonausgabe fuer externe Funktionen verfuegbar. PDC ist aktiv und Tongeber ist nicht gestoert.";
CM_ SG_ 1175 PLA_Anf_Aufschaltung_RVC "Anforderung der Aufschaltung RVC durch PLA";
CM_ SG_ 1175 PH_Stoermeldung "Meldung einer Stoerung der PDC an das Kombi";
CM_ SG_ 1175 PH_Anf_Verdeck "Anforderung an ein Verdeck-System, die vom Fahrer angeforderte Oeffnung/Schliessung zu verhindern";
CM_ SG_ 1175 PH_Frequenz_hinten "Uebertragung der aktuell im APS Steuergeraet gespeicherten Werte fuer Tongeber Frequenz hinten";
CM_ SG_ 1175 PH_Lautstaerke_hinten "Uebertragung der aktuell im APS Steuergeraet gespeicherten Werte fuer Tongeber Lautstaerke hinten";
CM_ SG_ 1175 PH_Frequenz_vorn "Uebertragung der aktuell im APS Steuergeraet gespeicherten Werte fuer Tongeber Frequenz vorne";
CM_ SG_ 1175 PH_Lautstaerke_vorn "Uebertragung der aktuell im APS Steuergeraet gespeicherten Werte fuer Tongeber Lautstaerke vorn.";
CM_ SG_ 1175 PH_Trigger_Bildaufschaltung "nur Audi fuer OPS in der RNS-E";
CM_ SG_ 1175 PH_StartStopp_Info "Stopp-Freigabe/Start-Anforderung fuer den Start-Stopp-Koordinator";
CM_ SG_ 1175 PH_defekt "ein Fehler ist aufgetreten, der die Parkhilfe in den Fehlerzustand versetzt, Signal bleibt bis zur naechsten \"Gut-Aktivierung\" gesetzt";
CM_ SG_ 1175 PH_gestoert "eine Stoerung ist aufgetreten, der die Parkhilfe in einen \"gestoert-Zustand\" versetzt, z.B. massiver Fremdultraschall, Vereisung, Schnee";
CM_ SG_ 1175 PH_Systemzustand "Aktivierungsursache wird fuer die Dauer der Aktivierung gemeldet | Im Fehlerfall bei aktivem System wechselt das Signal auf \"7\" | (siehe auch \"Abschaltursache\")";
CM_ SG_ 1175 PH_Display_Kundenwunsch "Anzeige der aktuell verwendeten Parameter bzgl. Kundenwunsch Displayanziege bei Aktivierung (nicht zwingend die abgespeicherten !)";
CM_ SG_ 1175 PH_KD_Fehler "mindestens ein Fehler ist im Kundendienstfehlerspeicher eingetragen";
CM_ SG_ 1353 PL_Luecke_P0_x "x-Koordinate des Punktes P0";
CM_ SG_ 1353 PL_Luecke_P0_y "y-Koordinate des Punktes P0";
CM_ SG_ 1353 PL_Luecke_P2_x "x-Koordinate des Punktes P2";
CM_ SG_ 1353 PL_Luecke_P2_y "y-Koordinate des Punktes P2";
CM_ SG_ 1354 PL_Luecke_P1_x "x-Koordinate des Punktes P1";
CM_ SG_ 1354 PL_Luecke_P1_y "y-Koordinate des Punktes P1";
CM_ SG_ 1354 PL_Luecke_P3_x "x-Koordinate des Punktes P3";
CM_ SG_ 1354 PL_Luecke_P3_y "y-Koordinate des Punktes P3";
CM_ SG_ 695 RCTA_Info_rechts "Das alte RCTA_Info wird aufgeteilt in RCTA_Info_links und RCTA_Info_rechts. Damit sollen Richtungsblinken oder aehnliches aufgrund der RCTA-Funtkion moeglich gemacht werden. | | Dieser Parameter ist eine zusaetzliche Information zu RCTA. Andere Systeme koennen hier Informationen aus RCTA erlangen. Hier ist kodiert, ob RCTA eine Gefahr erkennt und wie gefaehrdend die erkannte Situation ist. | | Es ist hier nicht kodiert, ob die Gefahr von links oder von rechts droht. Sondern die hoechste Gefahr links oder rechts bestimmt die hoechste Gefahr fuer das Gesamtfahrzeug. | | Die Informationen gliedern sich in folgende Stufen: | - nichts erkannt | - blind erkannt | - frei erkannt. | - unkritisch erkannt | - relevant erkannt | - kritisch erkannt | - sehr kritisch erkannt | - Kollision steht bevor";
CM_ SG_ 695 RCTA_Anforderung_HMS "Nach einer Notbremsung durch RCTA muss das Fahrzeug halten. Deshalb ist eine HMS-Anforderung mit der Notbremsung erforderlich.";
CM_ SG_ 695 RCTA_Info_links "Das alte RCTA_Info wird aufgeteilt in RCTA_Info_links und RCTA_Info_rechts. Damit sollen Richtungsblinken oder aehnliches aufgrund der RCTA-Funtkion moeglich gemacht werden. | | Dieser Parameter ist eine zusaetzliche Information zu RCTA. Andere Systeme koennen hier Informationen aus RCTA erlangen. Hier ist kodiert, ob RCTA eine Gefahr erkennt und wie gefaehrdend die erkannte Situation ist. | | Es ist hier nicht kodiert, ob die Gefahr von links oder von rechts droht. Sondern die hoechste Gefahr links oder rechts bestimmt die hoechste Gefahr fuer das Gesamtfahrzeug. | | Die Informationen gliedern sich in folgende Stufen: | - nichts erkannt | - blind erkannt | - frei erkannt. | - unkritisch erkannt | - relevant erkannt | - kritisch erkannt | - sehr kritisch erkannt | - Kollision steht bevor";
CM_ SG_ 695 RCTA_Warnton "Ansteuerung APS Tongeber fuer Warnton von RCTA. (Dauerton)";
CM_ SG_ 695 RCTA_01_CHK "Pruefsumme mit Endwert 0x0, Definition im CAN Lastenheft (HS-CAN V4.2a, LS-CAN V1.42)";
CM_ SG_ 695 RCTA_Bremsruck_Anforderung "RCTA_Bremsruck_Anforderung ist die Anforderung an das Bremssystem einen kurzen Bremsruck auszufuehren. Mit dem Signal \"RCTA_Bremsruck_Freigabe\" zusammen wird der Ruck ausgefuehrt. Dadurch soll der Fahrer auf eine moegliche Kollision hingewiesen und zum Bremsen animiert werden.";
CM_ SG_ 695 RCTA_Bremsruck_Freigabe "RCTA_Bremsruck_Freigabe ist die eigentliche Auforderung (mit dem Signal \"RCTA_Bremsruck_Anforderung\") an das Bremssystem einen kurzen Bremsruck auszufuehren. Dadurch soll der Fahrer auf eine moegliche Kollision hingewiesen und zum Bremsen animiert werden.";
CM_ SG_ 695 RCTA_Status "RCTA_Status ist die Rueckmeldung, ob das System ueberhaupt aktiv ist. Moegliche Zustaende sind: Das System ist aus; Das System ist nur passiv (laeuft, ist aber ohne Funktionalitaet); Das System ist aktiv; Das System ist fehlerhaft";
CM_ SG_ 695 RCTA_Notbremsung_Freigabe "RCTA_Notbremsung_Freigabe ist die eigentliche Auforderung (mit dem Signal \"Notbremsung_Anforderung_Wert\") an das Bremssystem eine Notfallbremsung einzuleiten. Dadurch sollen groessere Schaeden am Fahrzeug vermieden werden.";
CM_ SG_ 695 RCTA_Notbremsung_Anforderung "RCTA_Notbremsung_Anforderung ist die Anforderung der Funktion RCTA an das Bremssystem. Mit dem Signal \"Notbremsung_Freigabe\" zusammen wird die Bremsung eingeleitet. Dadurch sollen groessere Schaeden am Fahrzeug verhindert werden.";
CM_ SG_ 427 ESC_AHW_aktiv "Rueckmeldung Anhaltewegregelung aktiv";
CM_ SG_ 427 ESC_AHW_nicht_verfuegbar "Rueckmeldung Anhaltewegregelung nicht verfuegbar";
CM_ SG_ 427 ESC_ANB_CM_aktiv "Rueckmeldung ANB_CM (Autom_Notbremsung_Collision_Mitigation) aktiv";
CM_ SG_ 427 ESC_ANB_CM_nicht_verfuegbar "Rueckmeldung ANB_CM nicht verfuegbar";
CM_ SG_ 427 ESC_TSK_SRBM_Anf "Quittierung fuer TSK (SRBM=Summenradbremsmoment) Anforderung";
CM_ SG_ 427 ESC_TSK_SRBM_nicht_verfuegbar "Rueckmeldung TSK (SRBM= Summenradbremsmoment) nicht verfuegbar";
CM_ SG_ 427 ESC_Bremslicht_unplausibel "Plausibilisierung der Rueckmeldeinformation von BCM/AAG bezueglich Anforderung ESC_Bremslicht";
CM_ SG_ 427 ESC_Konsistenz_ARA "Rueckmeldung Konsistenz der ARA Botschaften";
CM_ SG_ 427 ESC_Konsistenz_IPA "Rueckmeldung Konsistenz der IPA Botschaften";
CM_ SG_ 427 ESC_Konsistenz_FCW "Rueckmeldung Konsistenz der FCW Botschaften";
CM_ SG_ 427 ESC_Konsistenz_NV "Rueckmeldung Konsistenz der NightVision Botschaften";
CM_ SG_ 427 ESC_Konsistenz_TSK "Rueckmeldung Konsistenz der TSK Botschaften";
CM_ SG_ 427 ESC_Konsistenz_vFGS "Rueckmeldung Konsistenz der vFGS Botschaften";
CM_ SG_ 427 ESC_Konsistenz_STA "Rueckmeldung Konsistenz der STA Botschaften";
CM_ SG_ 427 ESC_Konsistenz_EA "Rueckmeldung Konsistenz der EA Botschaften (HCA)";
CM_ SG_ 427 ESC_Konsistenz_BFF "Rueckmeldung Konsistenz der Verzoegerungsanforderung an das ESC-Steuergeraet der Funktion \"Bremsen im freien Fahren\" vom PDC_PLA_ARA-Steuergeraet";
CM_ SG_ 427 ESC_Verz_ASIL_Verfuegbarkeit "Gibt die Verfuegbarkeit der VZM-Regelung an, wobei folgende Zustaende beruecksichtigt werden: | -Nicht Verfuegbarkeit wegen Sonderbetriebszustaenden (z.B. Produktionsmodus) | -ueber VZM abgebaute Fahrzeuggeschwindigkeit bei Verzoegerungen a>5m/s2, wobei gilt | <=18km/h -> QM | <=40km/h -> ASIL A | <=65km/h -> ASIL B | >65km/h -> ASIL C und D";
CM_ SG_ 427 ESC_Pumpenanlauf_aktiv "Bestaetigung der Durchfuehrung eines Vorsteuerpumpenanlaufes";
CM_ SG_ 427 ESC_Konsistenz_AGW "Rueckmeldung Konsistenz der AGW-Botschaft an das ESC.";
CM_ SG_ 427 ESC_Konsistenz_KAS "Rueckmeldung Konsistenz fuer Kreuzungsassistent-Anforderungen";
CM_ SG_ 427 ESC_Konsistenz_PCF "Rueckmeldung der Konsistenz der PCF-Anforderungen";
CM_ SG_ 427 ESP_33_CHK "Pruefsumme mit Endwert 0x0, Definition im CAN Lastenheft (HS-CAN V4.2a, LS-CAN V1.42)";
CM_ SG_ 427 ESC_Warnruck_aktiv "Rueckmeldung Warnruck aktiv";
CM_ SG_ 427 ESC_Warnruck_nicht_verfuegbar "Rueckmeldung Warnruck nicht verfuegbar";
CM_ SG_ 427 ESC_Prefill_aktiv "Rueckmeldung Prefill aktiv";
CM_ SG_ 427 ESC_Prefill_nicht_verfuegbar "Rueckmeldung Prefill nicht verfuegbar";
CM_ SG_ 427 ESC_HBA_aktiv "Rueckmeldung HBA (hydraulischer Bremsassistent) aktiv";
CM_ SG_ 427 ESC_HBA_nicht_verfuegbar "Rueckmeldung HBA (hydraulischer Bremsassistent) nicht verfuegbar";
CM_ SG_ 427 ESC_Verz_Reg_aktiv "Rueckmeldung Verzoegerungsregelung aktiv";
CM_ SG_ 427 ESC_Verz_Reg_nicht_verfuegbar "Rueckmeldung Verzoegerungsregelung nicht verfuegbar";
CM_ SG_ 427 ESC_Verz_Reg_TB_nicht_verfuegbar "Rueckmeldung Verzoegerungsregelung (Teilbremsung) nicht verfuegbar";
CM_ SG_ 427 ESC_Verz_Reg_ZB_nicht_verfuegbar "Rueckmeldung Verzoegerungsregelung ZB (Zielbremsung) nicht verfuegbar";
CM_ SG_ 427 ESC_Konsistenz_ACC "Rueckmeldung Konsistenz der ACC Botschaften";
CM_ SG_ 427 ESC_Konsistenz_AWV "Rueckmeldung Konsistenz der AWV Botschaften";
CM_ SG_ 427 ESC_Konsistenz_RCTA "Rueckmeldung Konsistenz der RCTA (Rear Cross Traffic Alert) Botschaften";
CM_ SG_ 427 ESC_Fahrer_Bremsdruck_bestimmend "Das Signal zeigt an, dass der Fahrer Bremsdruck bestimmend ist";
CM_ SG_ 427 ESC_Konsistenz_MKB "Rueckmeldung Konsistenz fuer MKB-Verzoegerungsanforderung";
CM_ SG_ 1091 RKA_Prio1_Warnung "1 = Prio 1 Warnung | Prio 1 Warnung fuer Kombi";
CM_ SG_ 1091 RKA_Prio2_Warnung "1 = Prio 2 Warnung | Prio 2 Warnung fuer Kombi";
CM_ SG_ 1091 RDK_Status "RDK Status Ein/Aus | 0 = System aus | 1 = System ein";
CM_ SG_ 1091 RDK_neue_Solldruecke "0 = keine neuen Solldruecke | 1 = es liegen neue Solldruecke vor | RDK hat neue Solldruecke erkannt";
CM_ SG_ 1091 RKA_KD_Fehler "1 = mindestens ein Kundendienstfehler im Steuergeraet vorhanden";
CM_ SG_ 1091 RDK_Sensor_Multiplex "0x00 = vl | 0x01 = vr | 0x02 = hl | 0x03 = hr | 0x04 = RR | Multiplexinformation fuer die Auswahl eines Reifens";
CM_ SG_ 1091 RDK_xx_Status_Sensor "0 = Sensorwert ungueltig | 1 = Sensorwert gueltig (xx = vl, vr, hl, hr, RR) | Status des einzelnen Sensors in Abhaengigkeit von Byte 3, Bit 0...2";
CM_ SG_ 1091 RDK_xx_Color "0 = gruen | 1 = gelb | 2 = rot (xx = vl, vr, hl, hr, RR) | Farbdarstellung der Reifen im Kombi in Abhaengigkeit von Byte 3, Bit 0...2";
CM_ SG_ 1091 RDK_xx_Ist_Temp "Reifentemperatur_xx (xx = vl, vr, hl, hr) | Isttemperatur des Reifens in Abhaengigkeit von Byte 3, Bit 0...2";
CM_ SG_ 1091 RDK_xx_Ist_Druck "Istreifendruck_xx (xx = vl, vr, hl, hr) | Istdruck des Reifens in Abhaengigkeit von Byte 3, Bit 0...2";
CM_ SG_ 1091 RDK_xx_Soll_Druck "Sollreifendruck_xx (xx = vl, vr, hl, hr, RR) | Solldruck des Reifens in Abhaengigkeit von Byte 3, Bit 0...2";
CM_ SG_ 1091 RKA_Warnungen "Warnmeldungen fuers Kombi";
CM_ SG_ 1091 RKA_FMVSS_138_Warnung "1 = Warnlampe FMVSS 138";
CM_ SG_ 1091 RKA_Ack_IstZu_Solldruecke "Bestaetigung fuer MMI/Kombi, dass neue Solldruecke ueberwacht werden | Die aktuellen Istdruecke wurden zu neuen Solldruecken uebernommen";
CM_ SG_ 1091 RKA_Menue "Fuer den Fall des Verbaus eines RKA-Tasters am ESP kann ueber dieses Signal das Menue deaktiviert werden. | Z. Zt. unterstuetzt in TRW-ESP fuer VW47x und VW416GP | RB 9.0 China aktuell (2014) nicht unterstuetzt, jedoch fuer alle zukuenftigen Projekte (z. B. Global Market) bei Verwendung RKA+ in dieser Botschaft umzusetzen! | U. a. im T5GP wird kein expliziter Initwert unterstuetzt, sondern mit der ersten Botschaft der korrekte Wert gesendet (Kombi-Auswertung und Entscheidung einer Menue-Darstellung mit dem ersten empfangenen Wert!).";
CM_ SG_ 1091 RKA_Akustik "genutzt fuer separate Akustik RKA-System | | Hinweis: fuer Projekte VW428, VW464, VW316GP, VW47x zu 45/12, VW120 zu 22/13, VW253 zu 29/12, VW250 zu 45/12.";
CM_ SG_ 1472 EP1_QualNeigWi "Mitteilung z. Zt. fuer ACC um unter bestimmten Zustaenden mitzuteilen, dass Neigungswinkel temporaer ungueltig ist. | Beispiel: Selbsttest Neigungswinkelsensor | Erstmalig Audi C6 | Qualifizierungsbit Neigungswinkel";
CM_ SG_ 1472 EP1_Zaehler "Freilaufender Botschaftszaehler";
CM_ SG_ 1472 EP1_Fehler_Sta "Fehlerstatus Parkbremse";
CM_ SG_ 1472 EP1_Sta_EPB "Gibt den Zustand der EPB-Aktuatoren an. Verknuepfung mit Fehlerstatus; wenn z.B. 'Linke Seite Fehlerhaft' und 'Bremse geschlossen', dann ist nur die rechte Seite geschlossen. Das Bit gesetzt, wenn auf einer Seite Spannkraft aufgebaut wird. Wenn auf beiden Seiten keine Spannkraft mehr vorhanden ist, wird Bit wieder zurueckgesetzt. | Status Parkbremse";
CM_ SG_ 1472 EP1_Sta_Schalter "Auch bei vollen Funktion kann kurzfristig ein Schalterfehler vorliegen | Schalterstatus Parkbremse";
CM_ SG_ 1472 EP1_Spannkraft "Erzeugte Spannkraft. Bezieht sich auf die Aktuatoren";
CM_ SG_ 1472 EP1_Schalterinfo "Spiegelt die Schalterstellung wider | Schalterinfo Parkbremse";
CM_ SG_ 1472 EP1_Sta_NWS "Funktion des Neigungswinkelsensors | 1: Dauerhafter Ausfall oder Fehler Neigungswinkelgeber | Status Neigungswinkelgeber";
CM_ SG_ 1472 EP1_Neig_winkel "Neigungswinkelsignal";
CM_ SG_ 1472 EP1_Verzoegerung "Steuerungsanforderung an andere Systeme (z.B. ESP), um waehrend der Fahrt, durch den Handbremsschalter ausgeloest, zu Bremsen (ECD-Funktion). | Verzoegerungsanforderung (EPB)";
CM_ SG_ 1472 EP1_Fehlereintr "Bei gesetztem Bit ist mindestens ein Kundendienstfehler eingetragen";
CM_ SG_ 1472 EP1_Freigabe_Ver "Freigabe Verzoegerungs-Anforderung";
CM_ SG_ 1472 EP1_AutoHold_zul "Mit diesem Bit soll das Kombi den Menuepunkt 'Auto Hold' zur Verfuegung stellen und das Bit 'Auto Hold umschalten' (Kombi_3, Byte 3, Bit 6) bedienen. | (geplant fuer PQ46 ab 22/08, VW469) | Personalisierung Auto Hold zulaessig";
CM_ SG_ 1472 EP1_AutoHold_aktiv "Funktion 'Auto Hold' ist in der EPB aktiviert und wird im Kombi zur Anzeige gebracht (nur gueltig, wenn Byte 5, Bit 2 Personalisierung zulaesst) | (geplant fuer PQ46 ab 22/08, VW469) | Auto Hold aktiviert";
CM_ SG_ 1472 EP1_SleepInd "Sleep Indication | NMHigh-Teilnehmer der PQ35/46 muessen das Signal nach Kl.-15 aus weiterhin bedienen oder dauerhaft auf 1 = 'Sleep bereit' setzen!";
CM_ SG_ 1472 EP1_Status_Kl_15 "Klemme 15 am EPB-Steuergeraet | Statusbit Klemme 15";
CM_ SG_ 1472 EP1_Lampe_AutoP "Fahrerwunsch 'Auto Hold': im Stillstand wird die Parkstellung eingenommen (nur im PQ46) | Funktionslampe Auto Hold";
CM_ SG_ 1472 EP1_Bremslicht "Bremslichtansteuerung bei dynamischer Abbremsung (nur im PQ46)";
CM_ SG_ 1472 EP1_Warnton1 "PQ46-Kombi loest einmal Warnton aus | wird nur zusammen mit gelber Fehlerlampe (Byte 7, Bit 3) gesetzt";
CM_ SG_ 1472 EP1_Warnton2 "PQ46-Kombi loest dreimal Warnton | wird zusammen mit roter Fehlerlampe (Byte 7, Bit 2) gesetzt";
CM_ SG_ 1472 EP1_AnfShLock "EPB kann manuell nur bei betaetigter Fussbremse geoeffnet werden. Wenn Bit gesetzt ist zeigt PQ46-Kombi die Shift-Lock-Lampe an | Anforderung Shift-Lock-Lampe";
CM_ SG_ 1472 EPB_Autoholdlampe "Autoholdlampe im Kombi, gruenes P | 0x0 = Lampe aus (Autohold inaktiv) | 0x1 = Lampe ein (Autohold aktiv)";
CM_ SG_ 1472 EP1_KuppModBer "Nur fuer Handschalter. Wird auf 01 gesetzt, wenn das PWM-Signal des Kupplungspedalsensors im Bereich zwischen 80%-Signalpegel und Minimum liegt. | Der Zustand 10b kann derzeit nur von Audi bedient werden, da der PQ46-Sensor keine Plausibilisierung des Signalverlaufes durchfuehren kann. | Gueltig fuer VW: Das Signal wird auf 01 gesetzt, wenn der Kupplungspedalweg von der Stellung unbetaetigt aus ca. 50mm ueberschreitet. | Kupplungsmodulationsbereich";
CM_ SG_ 1472 EP1_HydrHalten "Bit wird gesetzt, wenn das Fahrzeug im Auto-Hold-Modus hydraulisch gehalten wird | Hydraulisches Halten aktiv (Auto-Hold)";
CM_ SG_ 1472 EP1_Fkt_Lampe "Bit wird nur gesetzt, wenn volle Spannkraft auf beiden Seiten erreicht | PQ46: Bit wird gesetzt, wenn BKL direkt vom EPB-SG als Funktionslampe angesteuert wird";
CM_ SG_ 1472 EP1_Warnton "Bit wird gesetzt, wenn bei v > 0 eine Fahreranforderung schliessen vorhanden ist (ECD angefordert) | PQ46-Kombi sendet Warnton (600 Hz) solange dieses Bit gesetzt ist | Warnton (EPB 1)";
CM_ SG_ 1472 EP1_Fehler_BKL "Die BKL dient als rote Fehlerlampe fuer die EPB. Sie wird vom EPB-SG aktiv ausgeschaltet. | Genaue Bedienung des Signals (Projekte/Termine) ist bei der Fachabteilung nachzufragen.";
CM_ SG_ 1472 EP1_Fehler_gelb "Fehlerlampe fuer nicht 'liegenbleiberelevante' Fehler | Fehlerlampe (gelb)";
CM_ SG_ 1472 EP1__Text "0000 keine Textanzeige im Kombi | 0001 Neigungswinkel zu gross (nicht PQ46) | 0010 Parkbremse von Hand oeffnen | 0011 EPB in Diagnose (nicht PQ46) | 0100 Bremspedal betaetigen (wird solange angezeigt, wie Fahrer das Bedienteil drueckt und Bremspedal nicht betaetigt) | 0101 Parkbremse bei laufendem Motor schliessen (nicht PQ46) | 1000 Fehler Parkbremse Bedienungsanleitung beachten (nur PQ46) | Anmerkung: Es kann immer nur ein Text gleichzeitig ausgegeben werden";
CM_ SG_ 1472 EP1_Checksum "Pruefsumme mit Endwert 0x0, Definition im CAN Lastenheft (HS-CAN V4.2a, LS-CAN V1.42)";
CM_ SG_ 65 Airbag_03_CRC "\"Berechnung siehe Lastenheft \"End-to-End Kommunikationsabsicherung\"\" | Endwerte siehe Begleitdokument \"S-PDU Kennungsfolgen\" | Kennungsfolge: | 0x93,0xb0,0x9d,0xf1,0x09,0xe8,0x88,0x5e,0x36,0xfa,0xa8,0xa1,0x67,0x84,0xca,0x4f | | Im AU210PA gilt die stat. Kennungsfolge: | 0x67,0x67,0x67,0x67,0x67,0x67,0x67,0x67,0x67,0x67,0x67,0x67,0x67,0x67,0x67,0x67";
CM_ SG_ 65 Airbag_03_BZ "freilaufender Botschaftszaehler";
CM_ SG_ 65 AB_MKB_Anforderung "Anforderung Multi-Kollisions-Bremsung";
CM_ SG_ 65 AB_MKB_gueltig "Multi-Kollisions-Bremsung im Airbag freigeschaltet";
CM_ SG_ 65 AB_MKB_Safing "Safing fuer Multi-Kollisions-Bremsung";
CM_ SG_ 1658 BAP_Data_Anzeige_02 "ASG: RNS, Radio => FSG: OPS, HYB";
CM_ SG_ 1750 BAP_Data_Debug_Cmd "BAP Debug Cmd";
CM_ SG_ 1811 ISO_ABS_Req_Data "ISO Request Kanal";
CM_ SG_ 1792 ISO_ALL_01_Req_Data "ISO Request Kanal";
CM_ SG_ 1751 BAP_Debug_Data "BAP Debug Data";
CM_ SG_ 1771 BAP_Data_RDK_02 "FSG: RDK, BCM => ASG: KBI";
CM_ SG_ 1917 ISO_ABS_Resp_Data "ISO Response Kanal";
CM_ SG_ 1482 EP2_Checksum "Pruefsumme mit Endwert 0x0, Definition im CAN Lastenheft (HS-CAN V4.2a, LS-CAN V1.42)";
CM_ SG_ 1482 EP2_Zaehler "Freilaufender Botschaftszaehler";
CM_ SG_ 1482 EPB_Status "Gibt den Zustand der EPB-Aktuatoren an.";
BA_DEF_ BO_ "GenMsgCycleTime" INT 0 65535;
BA_DEF_ BO_ "GenMsgSendType" STRING ;
BA_DEF_ SG_ "GenSigSendType" STRING ;
BA_DEF_DEF_ "GenMsgCycleTime" 0;
BA_DEF_DEF_ "GenMsgSendType" "";
BA_DEF_DEF_ "GenSigSendType" "";
BA_ "GenMsgCycleTime" BO_ 1186 500;
BA_ "GenMsgSendType" BO_ 1186 "Cyclic";
BA_ "GenSigSendType" SG_ 1186 TSK_Wunschgeschw "OnChange";
BA_ "GenSigSendType" SG_ 1186 TSK_Texte_Primaeranz "OnChange";
BA_ "GenSigSendType" SG_ 1186 TSK_Limiter_Fahrerinfo "OnChange";
BA_ "GenSigSendType" SG_ 1186 TSK_Limiter_Anzeige "OnChange";
BA_ "GenSigSendType" SG_ 1186 TSK_Status_Anzeige "OnChange";
BA_ "GenMsgCycleTime" BO_ 1343 1000;
BA_ "GenMsgSendType" BO_ 1343 "Cyclic";
BA_ "GenSigSendType" SG_ 1343 SCR_Zustand "Cyclic";
BA_ "GenSigSendType" SG_ 1343 SCR_Retriggersignal "Cyclic";
BA_ "GenSigSendType" SG_ 1343 SCR_Nachfuellmenge_min "Cyclic";
BA_ "GenSigSendType" SG_ 1343 SCR_Nachfuellmenge_max "Cyclic";
BA_ "GenSigSendType" SG_ 1343 SCR_Nachfuellmenge_Einheit "Cyclic";
BA_ "GenSigSendType" SG_ 1343 SCR_Tankvolumen "Cyclic";
BA_ "GenSigSendType" SG_ 1343 SCR_Einheit "Cyclic";
BA_ "GenSigSendType" SG_ 1343 SCR_Fuellstand "Cyclic";
BA_ "GenSigSendType" SG_ 1343 SCR_Restreichweite "Cyclic";
BA_ "GenMsgCycleTime" BO_ 1160 10;
BA_ "GenMsgSendType" BO_ 1160 "Cyclic";
BA_ "GenSigSendType" SG_ 1160 MO6_Checksum "Cyclic";
BA_ "GenSigSendType" SG_ 1160 MO6_SollM_Getr "Cyclic";
BA_ "GenSigSendType" SG_ 1160 MO6_Ist_Moment "Cyclic";
BA_ "GenSigSendType" SG_ 1160 MO6_Hoeheninfo "Cyclic";
BA_ "GenSigSendType" SG_ 1160 MO6_GRA_Soll "Cyclic";
BA_ "GenSigSendType" SG_ 1160 MO6_MomIntGeEing "Cyclic";
BA_ "GenSigSendType" SG_ 1160 MO6_FF_Mux00 "NoSigSendType";
BA_ "GenSigSendType" SG_ 1160 MO6_FF_Mux01 "NoSigSendType";
BA_ "GenSigSendType" SG_ 1160 MO6_FF_Mux02 "NoSigSendType";
BA_ "GenSigSendType" SG_ 1160 MO6_FF_Mux03 "NoSigSendType";
BA_ "GenSigSendType" SG_ 1160 MO6_FF_Mux04 "NoSigSendType";
BA_ "GenSigSendType" SG_ 1160 MO6_FF_Mux05 "NoSigSendType";
BA_ "GenSigSendType" SG_ 1160 MO6_FF_Mux06 "NoSigSendType";
BA_ "GenSigSendType" SG_ 1160 MO6_FF_Mux07 "NoSigSendType";
BA_ "GenSigSendType" SG_ 1160 MO6_FF_Mux08 "NoSigSendType";
BA_ "GenSigSendType" SG_ 1160 MO6_FF_Mux09 "NoSigSendType";
BA_ "GenSigSendType" SG_ 1160 MO6_FF_Mux10 "NoSigSendType";
BA_ "GenSigSendType" SG_ 1160 MO6_FF_Mux11 "NoSigSendType";
BA_ "GenSigSendType" SG_ 1160 MO6_FF_Mux12 "NoSigSendType";
BA_ "GenSigSendType" SG_ 1160 MO6_FF_Mux13 "NoSigSendType";
BA_ "GenSigSendType" SG_ 1160 MO6_FF_Mux14 "NoSigSendType";
BA_ "GenSigSendType" SG_ 1160 MO6_FF_Mux15 "NoSigSendType";
BA_ "GenSigSendType" SG_ 1160 MO6_Freigabe_GRA "Cyclic";
BA_ "GenSigSendType" SG_ 1160 MO6_Schutz_Toel "Cyclic";
BA_ "GenSigSendType" SG_ 1160 MO6_Luftpfad_akt "Cyclic";
BA_ "GenSigSendType" SG_ 1160 MO6_RegPartikel "Cyclic";
BA_ "GenSigSendType" SG_ 1160 MO6_Zaehler "Cyclic";
BA_ "GenMsgCycleTime" BO_ 1162 20;
BA_ "GenMsgSendType" BO_ 1162 "Cyclic";
BA_ "GenSigSendType" SG_ 1162 MO8_Checksumme "Cyclic";
BA_ "GenSigSendType" SG_ 1162 MO8_AnzeigeDZ "Cyclic";
BA_ "GenSigSendType" SG_ 1162 MO_Effizienzmodus "Cyclic";
BA_ "GenSigSendType" SG_ 1162 MO8_SGT_Soundakt "Cyclic";
BA_ "GenSigSendType" SG_ 1162 MO8_Spoiler_ausf "Cyclic";
BA_ "GenSigSendType" SG_ 1162 MO8_Sportschalter "Cyclic";
BA_ "GenSigSendType" SG_ 1162 MO8_LampeDZBegr "Cyclic";
BA_ "GenSigSendType" SG_ 1162 MO8_Enable_Oeldr_Motor "Cyclic";
BA_ "GenSigSendType" SG_ 1162 MO8_Oeldr_Warn_Motor "Cyclic";
BA_ "GenSigSendType" SG_ 1162 MO8_Avus_Motorschutz "Cyclic";
BA_ "GenSigSendType" SG_ 1162 MO8_Anzeigecode "Cyclic";
BA_ "GenSigSendType" SG_ 1162 MO_P_verriegelt "Cyclic";
BA_ "GenSigSendType" SG_ 1162 MO8_GRA_v_Wunsch "Cyclic";
BA_ "GenSigSendType" SG_ 1162 MO_Schaltempf_verfbar "Cyclic";
BA_ "GenSigSendType" SG_ 1162 MO8_Nachlauf_ZWP "Cyclic";
BA_ "GenSigSendType" SG_ 1162 MO_Istgang "Cyclic";
BA_ "GenSigSendType" SG_ 1162 MO_Sollgang "Cyclic";
BA_ "GenSigSendType" SG_ 1162 MO8_Zaehler "Cyclic";
BA_ "GenMsgCycleTime" BO_ 1800 200;
BA_ "GenMsgSendType" BO_ 1800 "Cyclic";
BA_ "GenSigSendType" SG_ 1800 MC1_Anz_Betrieb "Cyclic";
BA_ "GenSigSendType" SG_ 1800 MC1_Schalter "Cyclic";
BA_ "GenSigSendType" SG_ 1800 MC1_akt_Betrieb "Cyclic";
BA_ "GenSigSendType" SG_ 1800 MC1_CNG_LPG "Cyclic";
BA_ "GenSigSendType" SG_ 1800 MO_LPG_Tankstopp "NoSigSendType";
BA_ "GenSigSendType" SG_ 1800 MO_Erdgasqualitaet "Cyclic";
BA_ "GenSigSendType" SG_ 1800 MC1_Fuellungsgrad "Cyclic";
BA_ "GenSigSendType" SG_ 1800 MC1_Verbrauch "NoSigSendType";
BA_ "GenSigSendType" SG_ 1800 MC1_Verbrauch_LPG "NoSigSendType";
BA_ "GenSigSendType" SG_ 1800 MC1_Ueb_Verbr "Cyclic";
BA_ "GenSigSendType" SG_ 1800 MO_AnzeigeGasbetrieb "Cyclic";
BA_ "GenSigSendType" SG_ 1800 MO_Gastemperatur "Cyclic";
BA_ "GenSigSendType" SG_ 1800 MO_Verbrauchsaequivalent "Cyclic";
BA_ "GenMsgCycleTime" BO_ 1562 500;
BA_ "GenMsgSendType" BO_ 1562 "Cyclic";
BA_ "GenSigSendType" SG_ 1562 MEV1_Checksumme "Cyclic";
BA_ "GenSigSendType" SG_ 1562 MEV1_Zaehler "Cyclic";
BA_ "GenSigSendType" SG_ 1562 MO_Red_FahrleistungsLampe "Cyclic";
BA_ "GenSigSendType" SG_ 1562 Ladestecker_gesteckt "Cyclic";
BA_ "GenSigSendType" SG_ 1562 Ladevorgang_aktiv "OnChange";
BA_ "GenSigSendType" SG_ 1562 HV_Bordnetz_aktiv "Cyclic";
BA_ "GenSigSendType" SG_ 1562 HV_Bordnetz_A_Status "OnChange";
BA_ "GenSigSendType" SG_ 1562 HV_PTC_LeistRed "Cyclic";
BA_ "GenSigSendType" SG_ 1562 HV_PTC_aus "Cyclic";
BA_ "GenSigSendType" SG_ 1562 Ladestecker_verr_Status "Cyclic";
BA_ "GenSigSendType" SG_ 1562 HV_Anf_ReichweiteNV "Cyclic";
BA_ "GenSigSendType" SG_ 1562 MO_Wahl_Pos "OnChange";
BA_ "GenSigSendType" SG_ 1562 QB_Ladestecker_gesteckt "Cyclic";
BA_ "GenSigSendType" SG_ 1562 MO_Fehler_Notabschaltung_Klima "OnChange";
BA_ "GenSigSendType" SG_ 1562 QB_Ladezustand_HV_Batterie "Cyclic";
BA_ "GenSigSendType" SG_ 1562 BMS_Temperierung_Anf "Cyclic";
BA_ "GenSigSendType" SG_ 1562 Energieinhalt_HV_Batt "Cyclic";
BA_ "GenSigSendType" SG_ 1562 Ladezustand_HV_Batterie "Cyclic";
BA_ "GenMsgCycleTime" BO_ 1154 20;
BA_ "GenMsgSendType" BO_ 1154 "Cyclic";
BA_ "GenSigSendType" SG_ 1154 MH1_VM_Mom_oE "Cyclic";
BA_ "GenSigSendType" SG_ 1154 MH1_IstStatusK0 "Cyclic";
BA_ "GenSigSendType" SG_ 1154 MH1_Startmodus_PQ35 "Cyclic";
BA_ "GenSigSendType" SG_ 1154 MH1_VM_aktiv "Cyclic";
BA_ "GenSigSendType" SG_ 1154 MH1_Zielzustand_Hybrid "Cyclic";
BA_ "GenSigSendType" SG_ 1154 MH1_Schaltverh "Cyclic";
BA_ "GenSigSendType" SG_ 1154 MH1_VerlParam_Msum "NoSigSendType";
BA_ "GenSigSendType" SG_ 1154 MH1_MomVerlauf_EM "NoSigSendType";
BA_ "GenSigSendType" SG_ 1154 MH1_E_Faktor "NoSigSendType";
BA_ "GenSigSendType" SG_ 1154 MH1_Drehzahl_VM "Cyclic";
BA_ "GenSigSendType" SG_ 1154 MH1_max_ind_VM_Mom "Cyclic";
BA_ "GenSigSendType" SG_ 1154 MH1_Notstart "Cyclic";
BA_ "GenSigSendType" SG_ 1154 MH1_LowSpeedModus "Cyclic";
BA_ "GenSigSendType" SG_ 1154 MH1_ACCGRA_aktiv "Cyclic";
BA_ "GenSigSendType" SG_ 1154 MH1_EMode_Info "Cyclic";
BA_ "GenSigSendType" SG_ 1154 MH1_QB_Bremspedalwert "Cyclic";
BA_ "GenSigSendType" SG_ 1154 MH1_Bremspedalwert "Cyclic";
BA_ "GenMsgCycleTime" BO_ 399 10;
BA_ "GenMsgSendType" BO_ 399 "Cyclic";
BA_ "GenSigSendType" SG_ 399 Motor_LPG_01_Reserve "Cyclic";
BA_ "GenMsgCycleTime" BO_ 1823 100;
BA_ "GenMsgSendType" BO_ 1823 "Cyclic";
BA_ "GenSigSendType" SG_ 1823 MSI_KD_Fehler "Cyclic";
BA_ "GenMsgCycleTime" BO_ 1428 25;
BA_ "GenMsgSendType" BO_ 1428 "Cyclic";
BA_ "GenSigSendType" SG_ 1428 NI2_Checksum "Cyclic";
BA_ "GenSigSendType" SG_ 1428 NI2_Zaehler "Cyclic";
BA_ "GenSigSendType" SG_ 1428 NI2_Hoehenflag "Cyclic";
BA_ "GenSigSendType" SG_ 1428 NI2_Hoehe_VL "NoSigSendType";
BA_ "GenSigSendType" SG_ 1428 NI2_Hoehe_VL_Roh "NoSigSendType";
BA_ "GenSigSendType" SG_ 1428 NI2_Hoehe_VR "NoSigSendType";
BA_ "GenSigSendType" SG_ 1428 NI2_Hoehe_VR_Roh "NoSigSendType";
BA_ "GenSigSendType" SG_ 1428 NI2_Hoehe_HL "NoSigSendType";
BA_ "GenSigSendType" SG_ 1428 NI2_Hoehe_HL_Roh "NoSigSendType";
BA_ "GenSigSendType" SG_ 1428 NI2_Hoehe_HR "NoSigSendType";
BA_ "GenSigSendType" SG_ 1428 NI2_Hoehe_HR_Roh "NoSigSendType";
BA_ "GenSigSendType" SG_ 1428 NI2_AufbBeschl_VL "NoSigSendType";
BA_ "GenSigSendType" SG_ 1428 NI2_AufbBeschl_VR "NoSigSendType";
BA_ "GenMsgCycleTime" BO_ 1349 500;
BA_ "GenMsgSendType" BO_ 1349 "Cyclic";
BA_ "GenSigSendType" SG_ 1349 PA3_System_codierung "OnChange";
BA_ "GenSigSendType" SG_ 1349 PA3_Anlage_defekt "OnChange";
BA_ "GenSigSendType" SG_ 1349 PA3_Taster_aktiviert "OnChange";
BA_ "GenSigSendType" SG_ 1349 PA3_Rueckwaertsgang_aktiv "OnChange";
BA_ "GenSigSendType" SG_ 1349 PA3_Geschwindigkeit_aus "OnChange";
BA_ "GenSigSendType" SG_ 1349 PA3_Tongeber_v_defekt "OnChange";
BA_ "GenSigSendType" SG_ 1349 PA3_Tongeber_h_defekt "OnChange";
BA_ "GenSigSendType" SG_ 1349 PA3_Audioabsenkung_Anforderung "OnChange";
BA_ "GenSigSendType" SG_ 1349 PA3_Eis_aus "OnChange";
BA_ "GenSigSendType" SG_ 1349 PA3_Schlechtweg_aus "OnChange";
BA_ "GenSigSendType" SG_ 1349 PA3_KD_Fehler "OnChange";
BA_ "GenSigSendType" SG_ 1349 PA3_Sensor_hll_defekt "OnChange";
BA_ "GenSigSendType" SG_ 1349 PA3_Sensor_hlm_defekt "OnChange";
BA_ "GenSigSendType" SG_ 1349 PA3_Sensor_hrm_defekt "OnChange";
BA_ "GenSigSendType" SG_ 1349 PA3_Sensor_hrr_defekt "OnChange";
BA_ "GenSigSendType" SG_ 1349 PA3_Sensor_vll_defekt "OnChange";
BA_ "GenSigSendType" SG_ 1349 PA3_Sensor_vlm_defekt "OnChange";
BA_ "GenSigSendType" SG_ 1349 PA3_Sensor_vrm_defekt "OnChange";
BA_ "GenSigSendType" SG_ 1349 PA3_Sensor_vrr_defekt "OnChange";
BA_ "GenSigSendType" SG_ 1349 PA3_Bereit "OnChange";
BA_ "GenSigSendType" SG_ 1349 PA3_Bereich_vo "OnChange";
BA_ "GenSigSendType" SG_ 1349 PA3_Bereich_hi "OnChange";
BA_ "GenSigSendType" SG_ 1349 PA3_Akust_aus "OnChange";
BA_ "GenSigSendType" SG_ 1349 PA3_Aufbau_erk "OnChange";
BA_ "GenMsgSendType" BO_ 1355 "IfActive";
BA_ "GenSigSendType" SG_ 1355 PA5_VL_Abstand "IfActive";
BA_ "GenSigSendType" SG_ 1355 PA5_VR_Abstand "IfActive";
BA_ "GenSigSendType" SG_ 1355 PA5_HL_Abstand "IfActive";
BA_ "GenSigSendType" SG_ 1355 PA5_HR_Abstand "IfActive";
BA_ "GenSigSendType" SG_ 1355 PA5_VML_Abstand "IfActive";
BA_ "GenSigSendType" SG_ 1355 PA5_VMR_Abstand "IfActive";
BA_ "GenSigSendType" SG_ 1355 PA5_HML_Abstand "IfActive";
BA_ "GenSigSendType" SG_ 1355 PA5_HMR_Abstand "IfActive";
BA_ "GenMsgCycleTime" BO_ 1166 100;
BA_ "GenMsgSendType" BO_ 1166 "Cyclic";
BA_ "GenSigSendType" SG_ 1166 PLA_Status_Aktive_Seite "Cyclic";
BA_ "GenSigSendType" SG_ 1166 PLA_Anf_Anzeige_Mini "Cyclic";
BA_ "GenSigSendType" SG_ 1166 PLA_Mini_Modus "Cyclic";
BA_ "GenSigSendType" SG_ 1166 PLA_Anf_Akustik "Cyclic";
BA_ "GenSigSendType" SG_ 1166 PLA_Anf_Anzeige_Schwellpfeil "Cyclic";
BA_ "GenSigSendType" SG_ 1166 PLA_Anf_Anzeige_Bremsfuss "Cyclic";
BA_ "GenSigSendType" SG_ 1166 PLA_Anf_Funktionsdisclaimer "Cyclic";
BA_ "GenSigSendType" SG_ 1166 PLA_Anf_Anzeigemodus "Cyclic";
BA_ "GenSigSendType" SG_ 1166 PLA_Anf_Meldungen "Cyclic";
BA_ "GenSigSendType" SG_ 1166 PLA_Anzahl_Segmente_Schwellpfeil "Cyclic";
BA_ "GenSigSendType" SG_ 1166 PLA_Status_Funktion "Cyclic";
BA_ "GenSigSendType" SG_ 1166 PLA_Status_beenden_Mini "Cyclic";
BA_ "GenSigSendType" SG_ 1166 PLA_Status_Laengsparken_Mini "Cyclic";
BA_ "GenSigSendType" SG_ 1166 PLA_Status_QP_Rueckw_Mini "Cyclic";
BA_ "GenSigSendType" SG_ 1166 PLA_Status_QP_Vorw_Mini "Cyclic";
BA_ "GenMsgCycleTime" BO_ 714 10;
BA_ "GenMsgSendType" BO_ 714 "Cyclic";
BA_ "GenSigSendType" SG_ 714 QS2_Ist_Wert "Cyclic";
BA_ "GenSigSendType" SG_ 714 QS2_Soll_Wert "Cyclic";
BA_ "GenSigSendType" SG_ 714 QS2_Status_VAQ "Cyclic";
BA_ "GenSigSendType" SG_ 714 QS2_Gleichlauf "Cyclic";
BA_ "GenSigSendType" SG_ 714 QS2_KD_Fehler "Cyclic";
BA_ "GenMsgSendType" BO_ 1437 "IfActive";
BA_ "GenSigSendType" SG_ 1437 RSF_Tastencode_1 "IfActiveWithRepetition";
BA_ "GenSigSendType" SG_ 1437 RSF_Tastencode_2 "IfActiveWithRepetition";
BA_ "GenSigSendType" SG_ 1437 RSF_Tastencode_Maske "IfActiveWithRepetition";
BA_ "GenMsgSendType" BO_ 16 "IfActive";
BA_ "GenSigSendType" SG_ 16 MSG1_WFS_RND "OnChange";
BA_ "GenSigSendType" SG_ 16 MSG1_WFS_CRC "OnChange";
BA_ "GenMsgSendType" BO_ 20 "IfActive";
BA_ "GenSigSendType" SG_ 20 MSG2_WFS_RND "OnChange";
BA_ "GenSigSendType" SG_ 20 MSG2_WFS_CRC "OnChange";
BA_ "GenMsgSendType" BO_ 22 "IfActive";
BA_ "GenSigSendType" SG_ 22 MSG3_WFS_RND "OnChange";
BA_ "GenSigSendType" SG_ 22 MSG3_WFS_CRC "OnChange";
BA_ "GenMsgSendType" BO_ 24 "IfActive";
BA_ "GenSigSendType" SG_ 24 MSG4_WFS_RND "OnChange";
BA_ "GenSigSendType" SG_ 24 MSG4_WFS_CRC "OnChange";
BA_ "GenMsgCycleTime" BO_ 1306 500;
BA_ "GenMsgSendType" BO_ 1306 "Cyclic";
BA_ "GenSigSendType" SG_ 1306 TOG_Zaehler "Cyclic";
BA_ "GenSigSendType" SG_ 1306 TOG_Fuellstand_1 "Cyclic";
BA_ "GenSigSendType" SG_ 1306 TOG_Fuellstand_2 "Cyclic";
BA_ "GenSigSendType" SG_ 1306 TOG_Fuellstand_3 "Cyclic";
BA_ "GenSigSendType" SG_ 1306 TOG_Fuellstand_4 "Cyclic";
BA_ "GenSigSendType" SG_ 1306 TOG_Oeltempzeit "Cyclic";
BA_ "GenSigSendType" SG_ 1306 TOG_Sensorfehler "Cyclic";
BA_ "GenSigSendType" SG_ 1306 TOG_Oelwarn_hoch "Cyclic";
BA_ "GenSigSendType" SG_ 1306 TOG_OelwarnUeber "Cyclic";
BA_ "GenSigSendType" SG_ 1306 TOG_OelmaxUeber "Cyclic";
BA_ "GenSigSendType" SG_ 1306 TOG_Oelmax_hoch "Cyclic";
BA_ "GenMsgSendType" BO_ 1937 "NoMsgSendType";
BA_ "GenSigSendType" SG_ 1937 TPDyn_ABS_2 "OnChange";
BA_ "GenMsgSendType" BO_ 1904 "NoMsgSendType";
BA_ "GenSigSendType" SG_ 1904 TPDyn_ADR_1 "OnChange";
BA_ "GenMsgSendType" BO_ 1896 "NoMsgSendType";
BA_ "GenSigSendType" SG_ 1896 TPDyn_Airbag_1 "OnChange";
BA_ "GenMsgSendType" BO_ 1906 "NoMsgSendType";
BA_ "GenSigSendType" SG_ 1906 TPDyn_Daempfer_1 "OnChange";
BA_ "GenMsgSendType" BO_ 1940 "NoMsgSendType";
BA_ "GenSigSendType" SG_ 1940 TPDyn_EPB_1 "OnChange";
BA_ "GenMsgSendType" BO_ 1864 "NoMsgSendType";
BA_ "GenSigSendType" SG_ 1864 TPDyn_FLA_1 "OnChange";
BA_ "GenMsgSendType" BO_ 1888 "NoMsgSendType";
BA_ "GenSigSendType" SG_ 1888 TPDyn_Getriebe_1 "OnChange";
BA_ "GenMsgSendType" BO_ 1889 "NoMsgSendType";
BA_ "GenSigSendType" SG_ 1889 TPDyn_Getriebe_2 "OnChange";
BA_ "GenMsgSendType" BO_ 1956 "NoMsgSendType";
BA_ "GenSigSendType" SG_ 1956 TPDyn_LDW_1 "OnChange";
BA_ "GenMsgSendType" BO_ 1957 "NoMsgSendType";
BA_ "GenSigSendType" SG_ 1957 TPDyn_LDW_2 "OnChange";
BA_ "GenMsgSendType" BO_ 1960 "NoMsgSendType";
BA_ "GenSigSendType" SG_ 1960 TPDyn_Lenkhilfe_1 "OnChange";
BA_ "GenMsgSendType" BO_ 1961 "NoMsgSendType";
BA_ "GenSigSendType" SG_ 1961 TPDyn_Lenkhilfe_2 "OnChange";
BA_ "GenMsgSendType" BO_ 1924 "NoMsgSendType";
BA_ "GenSigSendType" SG_ 1924 TPDyn_Dyn_LWR_1 "OnChange";
BA_ "GenMsgSendType" BO_ 1925 "NoMsgSendType";
BA_ "GenSigSendType" SG_ 1925 TPDyn_Dyn_LWR_2 "OnChange";
BA_ "GenMsgSendType" BO_ 1952 "NoMsgSendType";
BA_ "GenSigSendType" SG_ 1952 TPDyn_LWS "OnChange";
BA_ "GenMsgSendType" BO_ 1856 "NoMsgSendType";
BA_ "GenSigSendType" SG_ 1856 TPDyn_Motor_1 "OnChange";
BA_ "GenMsgSendType" BO_ 1857 "NoMsgSendType";
BA_ "GenSigSendType" SG_ 1857 TPDyn_Motor_2 "OnChange";
BA_ "GenMsgSendType" BO_ 1858 "NoMsgSendType";
BA_ "GenSigSendType" SG_ 1858 TPDyn_Motor_3 "OnChange";
BA_ "GenMsgSendType" BO_ 1859 "NoMsgSendType";
BA_ "GenSigSendType" SG_ 1859 TPDyn_Motor_4 "OnChange";
BA_ "GenMsgSendType" BO_ 1978 "NoMsgSendType";
BA_ "GenSigSendType" SG_ 1978 TPDyn_PLA_PDC "OnChange";
BA_ "GenMsgSendType" BO_ 1880 "NoMsgSendType";
BA_ "GenSigSendType" SG_ 1880 TPDyn_Quersperre_1 "OnChange";
BA_ "GenMsgSendType" BO_ 1881 "NoMsgSendType";
BA_ "GenSigSendType" SG_ 1881 TPDyn_Quersperre_2 "OnChange";
BA_ "GenMsgSendType" BO_ 1875 "NoMsgSendType";
BA_ "GenSigSendType" SG_ 1875 TPDyn_RKA_Plus_2 "OnChange";
BA_ "GenMsgSendType" BO_ 1920 "NoMsgSendType";
BA_ "GenSigSendType" SG_ 1920 TPDyn_WFS_1 "OnChange";
BA_ "GenMsgSendType" BO_ 1921 "NoMsgSendType";
BA_ "GenSigSendType" SG_ 1921 TPDyn_WFS_2 "OnChange";
BA_ "GenMsgSendType" BO_ 523 "NoMsgSendType";
BA_ "GenSigSendType" SG_ 523 ADR_TP_Er "OnChange";
BA_ "GenMsgSendType" BO_ 517 "NoMsgSendType";
BA_ "GenSigSendType" SG_ 517 Airbag_TP_Er "OnChange";
BA_ "GenMsgSendType" BO_ 522 "NoMsgSendType";
BA_ "GenSigSendType" SG_ 522 Allrad_TP_Er "OnChange";
BA_ "GenMsgSendType" BO_ 524 "NoMsgSendType";
BA_ "GenSigSendType" SG_ 524 Daempfer_TP_Er "OnChange";
BA_ "GenMsgSendType" BO_ 537 "NoMsgSendType";
BA_ "GenSigSendType" SG_ 537 EPB_TP_Er "OnChange";
BA_ "GenMsgSendType" BO_ 534 "NoMsgSendType";
BA_ "GenSigSendType" SG_ 534 FLA_TP_Er "OnChange";
BA_ "GenMsgSendType" BO_ 514 "NoMsgSendType";
BA_ "GenSigSendType" SG_ 514 Getriebe_TP_Er "OnChange";
BA_ "GenMsgSendType" BO_ 538 "NoMsgSendType";
BA_ "GenSigSendType" SG_ 538 LDW_TP_Er "OnChange";
BA_ "GenMsgSendType" BO_ 521 "NoMsgSendType";
BA_ "GenSigSendType" SG_ 521 Lenkhilfe_TP_Er "OnChange";
BA_ "GenMsgSendType" BO_ 518 "NoMsgSendType";
BA_ "GenSigSendType" SG_ 518 Dyn_LWR_TP_Er "OnChange";
BA_ "GenMsgSendType" BO_ 531 "NoMsgSendType";
BA_ "GenSigSendType" SG_ 531 LWS_TP_Er "OnChange";
BA_ "GenMsgSendType" BO_ 533 "NoMsgSendType";
BA_ "GenSigSendType" SG_ 533 Mot_Slave_1_TP_Er "OnChange";
BA_ "GenMsgSendType" BO_ 513 "NoMsgSendType";
BA_ "GenSigSendType" SG_ 513 Motor_TP_Er "OnChange";
BA_ "GenMsgSendType" BO_ 541 "NoMsgSendType";
BA_ "GenSigSendType" SG_ 541 PLA_PDC_TP_Er "OnChange";
BA_ "GenMsgSendType" BO_ 536 "NoMsgSendType";
BA_ "GenSigSendType" SG_ 536 Quersperre_TP_Er "OnChange";
BA_ "GenMsgSendType" BO_ 520 "NoMsgSendType";
BA_ "GenSigSendType" SG_ 520 RKA_Plus_TP_Er "OnChange";
BA_ "GenMsgSendType" BO_ 532 "NoMsgSendType";
BA_ "GenSigSendType" SG_ 532 WFS_TP_Er "OnChange";
BA_ "GenMsgCycleTime" BO_ 1096 10;
BA_ "GenMsgSendType" BO_ 1096 "Cyclic";
BA_ "GenSigSendType" SG_ 1096 WH1_StaShiftlock "Cyclic";
BA_ "GenSigSendType" SG_ 1096 WH1_Init "Cyclic";
BA_ "GenSigSendType" SG_ 1096 WH1_Position "Cyclic";
BA_ "GenSigSendType" SG_ 1096 WH1_Status "Cyclic";
BA_ "GenSigSendType" SG_ 1096 WH1_Testergebnis "Cyclic";
BA_ "GenSigSendType" SG_ 1096 WH1_Zaehler "Cyclic";
BA_ "GenSigSendType" SG_ 1096 WH1_Test_Flag "Cyclic";
BA_ "GenSigSendType" SG_ 1096 WH1_Taster_betaetigt "Cyclic";
BA_ "GenSigSendType" SG_ 1096 WH1_Position_inv "Cyclic";
BA_ "GenMsgCycleTime" BO_ 1102 10;
BA_ "GenMsgSendType" BO_ 1102 "Cyclic";
BA_ "GenSigSendType" SG_ 1102 WH2_Checksumme "Cyclic";
BA_ "GenSigSendType" SG_ 1102 WH2_Zaehler "Cyclic";
BA_ "GenSigSendType" SG_ 1102 WH2_Init "Cyclic";
BA_ "GenSigSendType" SG_ 1102 WH2_Test_Flag "Cyclic";
BA_ "GenSigSendType" SG_ 1102 WH2_Sport "Cyclic";
BA_ "GenSigSendType" SG_ 1102 WH2_Winter "Cyclic";
BA_ "GenSigSendType" SG_ 1102 WH2_Position "Cyclic";
BA_ "GenSigSendType" SG_ 1102 WH2_P_Taster "Cyclic";
BA_ "GenSigSendType" SG_ 1102 WH2_Ruhestromfehler "Cyclic";
BA_ "GenSigSendType" SG_ 1102 WH2_Sensorarray_Einfachfehler "Cyclic";
BA_ "GenSigSendType" SG_ 1102 WH2_Sensorarray_Mehrfachfehler "Cyclic";
BA_ "GenSigSendType" SG_ 1102 WH2_Fehler_Sporttaster "Cyclic";
BA_ "GenSigSendType" SG_ 1102 WH2_Fehler_Fahrstufenanzeige "Cyclic";
BA_ "GenSigSendType" SG_ 1102 WH2_Fehler_Spannungsversorgung "Cyclic";
BA_ "GenSigSendType" SG_ 1102 WH2_Timeout_Kombi_2 "Cyclic";
BA_ "GenSigSendType" SG_ 1102 WH2_Timeout_Getriebe_5 "Cyclic";
BA_ "GenSigSendType" SG_ 1102 WH2_Timeout_Gate_Komf_1 "Cyclic";
BA_ "GenSigSendType" SG_ 1102 WH2_Testergebnis "Cyclic";
BA_ "GenMsgCycleTime" BO_ 1394 100;
BA_ "GenMsgSendType" BO_ 1394 "Cyclic";
BA_ "GenSigSendType" SG_ 1394 ZA1_S_Kontakt "OnChange";
BA_ "GenSigSendType" SG_ 1394 ZA1_Klemme_15 "OnChange";
BA_ "GenSigSendType" SG_ 1394 ZA1_Klemme_X "OnChange";
BA_ "GenSigSendType" SG_ 1394 ZA1_Klemme_50 "OnChange";
BA_ "GenSigSendType" SG_ 1394 ZA1_Klemme_P "OnChange";
BA_ "GenMsgCycleTime" BO_ 919 100;
BA_ "GenMsgSendType" BO_ 919 "Cyclic";
BA_ "GenSigSendType" SG_ 919 ZK5_Checksumme "Cyclic";
BA_ "GenSigSendType" SG_ 919 ZK5_Zaehler "Cyclic";
BA_ "GenSigSendType" SG_ 919 ZK5_Endlage_ausgefahren "Cyclic";
BA_ "GenSigSendType" SG_ 919 ZK5_Endlage_eingefahren "Cyclic";
BA_ "GenSigSendType" SG_ 919 ZK5_Status_Spoiler "Cyclic";
BA_ "GenSigSendType" SG_ 919 ZV_SafeFunktion_aktiv "Cyclic";
BA_ "GenSigSendType" SG_ 919 ZK5_VD_Endlage_geschl "Cyclic";
BA_ "GenSigSendType" SG_ 919 ZK5_VD_Endlage_abgelegt "Cyclic";
BA_ "GenSigSendType" SG_ 919 ZK5_VD_Verbau "Cyclic";
BA_ "GenSigSendType" SG_ 919 VIP_Freigabe "Cyclic";
BA_ "GenMsgCycleTime" BO_ 1523 500;
BA_ "GenMsgSendType" BO_ 1523 "Cyclic";
BA_ "GenSigSendType" SG_ 1523 OBD_TG_F_Status_1 "Cyclic";
BA_ "GenSigSendType" SG_ 1523 OBD_TG_F_Status_2 "Cyclic";
BA_ "GenSigSendType" SG_ 1523 OBD_TG_F_Status_3 "Cyclic";
BA_ "GenSigSendType" SG_ 1523 OBD_TG_F_Status_4 "Cyclic";
BA_ "GenSigSendType" SG_ 1523 OBD_TG_Sens_Rohwert_1 "Cyclic";
BA_ "GenSigSendType" SG_ 1523 OBD_TG_Sens_Rohwert_2 "Cyclic";
BA_ "GenSigSendType" SG_ 1523 OBD_TG_Sens_Rohwert_3 "Cyclic";
BA_ "GenSigSendType" SG_ 1523 OBD_TG_Sens_Rohwert_4 "Cyclic";
BA_ "GenMsgCycleTime" BO_ 1175 100;
BA_ "GenMsgSendType" BO_ 1175 "Cyclic";
BA_ "GenSigSendType" SG_ 1175 PH_Freie_Weglaenge_Heck "Cyclic";
BA_ "GenSigSendType" SG_ 1175 PH_Freie_Weglaenge_Heck_Typ "Cyclic";
BA_ "GenSigSendType" SG_ 1175 PH_nachtr_Stopp_Anf "OnChange";
BA_ "GenSigSendType" SG_ 1175 PH_Abschaltursache "OnChange";
BA_ "GenSigSendType" SG_ 1175 PH_Opt_Anzeige_V_ein "OnChange";
BA_ "GenSigSendType" SG_ 1175 PH_Opt_Anzeige_H_ein "OnChange";
BA_ "GenSigSendType" SG_ 1175 PH_Opt_Anz_V_Hindernis "OnChange";
BA_ "GenSigSendType" SG_ 1175 PH_Opt_Anz_H_Hindernis "OnChange";
BA_ "GenSigSendType" SG_ 1175 PH_Tongeber_V_aktiv "OnChange";
BA_ "GenSigSendType" SG_ 1175 PH_Tongeber_H_aktiv "OnChange";
BA_ "GenSigSendType" SG_ 1175 PH_Tongeber_mute "OnChange";
BA_ "GenSigSendType" SG_ 1175 PH_Anf_Audioabsenkung "OnChange";
BA_ "GenSigSendType" SG_ 1175 PH_Tongeber_H_verfuegbar "OnChange";
BA_ "GenSigSendType" SG_ 1175 PLA_Anf_Aufschaltung_RVC "OnChange";
BA_ "GenSigSendType" SG_ 1175 PH_Stoermeldung "OnChange";
BA_ "GenSigSendType" SG_ 1175 PH_Anf_Verdeck "Cyclic";
BA_ "GenSigSendType" SG_ 1175 PH_Frequenz_hinten "Cyclic";
BA_ "GenSigSendType" SG_ 1175 PH_Lautstaerke_hinten "Cyclic";
BA_ "GenSigSendType" SG_ 1175 PH_Frequenz_vorn "Cyclic";
BA_ "GenSigSendType" SG_ 1175 PH_Lautstaerke_vorn "Cyclic";
BA_ "GenSigSendType" SG_ 1175 PH_Trigger_Bildaufschaltung "OnChange";
BA_ "GenSigSendType" SG_ 1175 PH_StartStopp_Info "OnChange";
BA_ "GenSigSendType" SG_ 1175 PH_Aufbauten_erk "OnChange";
BA_ "GenSigSendType" SG_ 1175 PH_BerErk_vorn "OnChange";
BA_ "GenSigSendType" SG_ 1175 PH_BerErk_hinten "OnChange";
BA_ "GenSigSendType" SG_ 1175 PH_defekt "OnChange";
BA_ "GenSigSendType" SG_ 1175 PH_gestoert "OnChange";
BA_ "GenSigSendType" SG_ 1175 PH_Systemzustand "OnChange";
BA_ "GenSigSendType" SG_ 1175 PH_Display_Kundenwunsch "OnChange";
BA_ "GenSigSendType" SG_ 1175 PH_KD_Fehler "OnChange";
BA_ "GenMsgSendType" BO_ 1353 "IfActive";
BA_ "GenSigSendType" SG_ 1353 PL_Luecke_P0_x "NoSigSendType";
BA_ "GenSigSendType" SG_ 1353 PL_Luecke_P0_y "NoSigSendType";
BA_ "GenSigSendType" SG_ 1353 PL_Luecke_P2_x "NoSigSendType";
BA_ "GenSigSendType" SG_ 1353 PL_Luecke_P2_y "NoSigSendType";
BA_ "GenMsgSendType" BO_ 1354 "IfActive";
BA_ "GenSigSendType" SG_ 1354 PL_Luecke_P1_x "NoSigSendType";
BA_ "GenSigSendType" SG_ 1354 PL_Luecke_P1_y "NoSigSendType";
BA_ "GenSigSendType" SG_ 1354 PL_Luecke_P3_x "NoSigSendType";
BA_ "GenSigSendType" SG_ 1354 PL_Luecke_P3_y "NoSigSendType";
BA_ "GenMsgCycleTime" BO_ 695 50;
BA_ "GenMsgSendType" BO_ 695 "Cyclic";
BA_ "GenSigSendType" SG_ 695 RCTA_Info_rechts "Cyclic";
BA_ "GenSigSendType" SG_ 695 RCTA_Anforderung_HMS "Cyclic";
BA_ "GenSigSendType" SG_ 695 RCTA_Info_links "Cyclic";
BA_ "GenSigSendType" SG_ 695 RCTA_Warnton "Cyclic";
BA_ "GenSigSendType" SG_ 695 RCTA_01_CHK "Cyclic";
BA_ "GenSigSendType" SG_ 695 RCTA_01_BZ "Cyclic";
BA_ "GenSigSendType" SG_ 695 RCTA_Bremsruck_Anforderung "Cyclic";
BA_ "GenSigSendType" SG_ 695 RCTA_Bremsruck_Freigabe "Cyclic";
BA_ "GenSigSendType" SG_ 695 RCTA_Status "Cyclic";
BA_ "GenSigSendType" SG_ 695 RCTA_Notbremsung_Freigabe "Cyclic";
BA_ "GenSigSendType" SG_ 695 RCTA_Notbremsung_Anforderung "Cyclic";
BA_ "GenMsgSendType" BO_ 2033 "NoMsgSendType";
BA_ "GenSigSendType" SG_ 2033 Req_Airbag_Deployment "OnChange";
BA_ "GenMsgSendType" BO_ 2041 "NoMsgSendType";
BA_ "GenSigSendType" SG_ 2041 Resp_Airbag_Deployment "OnChange";
BA_ "GenMsgCycleTime" BO_ 427 200;
BA_ "GenMsgSendType" BO_ 427 "Cyclic";
BA_ "GenSigSendType" SG_ 427 ESC_AHW_aktiv "OnChange";
BA_ "GenSigSendType" SG_ 427 ESC_AHW_nicht_verfuegbar "OnChange";
BA_ "GenSigSendType" SG_ 427 ESC_ANB_CM_aktiv "OnChange";
BA_ "GenSigSendType" SG_ 427 ESC_ANB_CM_nicht_verfuegbar "OnChange";
BA_ "GenSigSendType" SG_ 427 ESC_TSK_SRBM_Anf "OnChange";
BA_ "GenSigSendType" SG_ 427 ESC_TSK_SRBM_nicht_verfuegbar "OnChange";
BA_ "GenSigSendType" SG_ 427 ESC_Bremslicht_unplausibel "OnChange";
BA_ "GenSigSendType" SG_ 427 ESC_Konsistenz_ARA "OnChange";
BA_ "GenSigSendType" SG_ 427 ESC_Konsistenz_IPA "OnChange";
BA_ "GenSigSendType" SG_ 427 ESC_Konsistenz_FCW "OnChange";
BA_ "GenSigSendType" SG_ 427 ESC_Konsistenz_NV "OnChange";
BA_ "GenSigSendType" SG_ 427 ESC_Konsistenz_TSK "OnChange";
BA_ "GenSigSendType" SG_ 427 ESC_Konsistenz_vFGS "OnChange";
BA_ "GenSigSendType" SG_ 427 ESC_Konsistenz_STA "OnChange";
BA_ "GenSigSendType" SG_ 427 ESC_Konsistenz_EA "OnChange";
BA_ "GenSigSendType" SG_ 427 ESC_Konsistenz_BFF "OnChange";
BA_ "GenSigSendType" SG_ 427 ESC_Verz_ASIL_Verfuegbarkeit "OnChange";
BA_ "GenSigSendType" SG_ 427 ESC_Pumpenanlauf_aktiv "OnChange";
BA_ "GenSigSendType" SG_ 427 ESC_Konsistenz_AGW "OnChange";
BA_ "GenSigSendType" SG_ 427 ESC_Konsistenz_KAS "OnChange";
BA_ "GenSigSendType" SG_ 427 ESC_Konsistenz_PCF "OnChange";
BA_ "GenSigSendType" SG_ 427 ESP_33_CHK "Cyclic";
BA_ "GenSigSendType" SG_ 427 ESP_33_BZ "Cyclic";
BA_ "GenSigSendType" SG_ 427 ESC_Warnruck_aktiv "OnChange";
BA_ "GenSigSendType" SG_ 427 ESC_Warnruck_nicht_verfuegbar "OnChange";
BA_ "GenSigSendType" SG_ 427 ESC_Prefill_aktiv "OnChange";
BA_ "GenSigSendType" SG_ 427 ESC_Prefill_nicht_verfuegbar "OnChange";
BA_ "GenSigSendType" SG_ 427 ESC_HBA_aktiv "OnChange";
BA_ "GenSigSendType" SG_ 427 ESC_HBA_nicht_verfuegbar "OnChange";
BA_ "GenSigSendType" SG_ 427 ESC_Verz_Reg_aktiv "OnChange";
BA_ "GenSigSendType" SG_ 427 ESC_Verz_Reg_nicht_verfuegbar "OnChange";
BA_ "GenSigSendType" SG_ 427 ESC_Verz_Reg_TB_nicht_verfuegbar "OnChange";
BA_ "GenSigSendType" SG_ 427 ESC_Verz_Reg_ZB_nicht_verfuegbar "OnChange";
BA_ "GenSigSendType" SG_ 427 ESC_Konsistenz_ACC "OnChange";
BA_ "GenSigSendType" SG_ 427 ESC_Konsistenz_AWV "OnChange";
BA_ "GenSigSendType" SG_ 427 ESC_Konsistenz_RCTA "OnChange";
BA_ "GenSigSendType" SG_ 427 ESC_Fahrer_Bremsdruck_bestimmend "OnChange";
BA_ "GenSigSendType" SG_ 427 ESC_Konsistenz_MKB "OnChange";
BA_ "GenMsgCycleTime" BO_ 1091 500;
BA_ "GenMsgSendType" BO_ 1091 "Cyclic";
BA_ "GenSigSendType" SG_ 1091 RKA_Prio1_Warnung "OnChange";
BA_ "GenSigSendType" SG_ 1091 RKA_Prio2_Warnung "OnChange";
BA_ "GenSigSendType" SG_ 1091 RDK_Status "OnChange";
BA_ "GenSigSendType" SG_ 1091 RDK_neue_Solldruecke "OnChange";
BA_ "GenSigSendType" SG_ 1091 RKA_KD_Fehler "Cyclic";
BA_ "GenSigSendType" SG_ 1091 RDK_Sensor_Multiplex "Cyclic";
BA_ "GenSigSendType" SG_ 1091 RDK_xx_Status_Sensor "Cyclic";
BA_ "GenSigSendType" SG_ 1091 RDK_xx_Color "Cyclic";
BA_ "GenSigSendType" SG_ 1091 RDK_xx_Ist_Temp "Cyclic";
BA_ "GenSigSendType" SG_ 1091 RDK_xx_Ist_Druck "Cyclic";
BA_ "GenSigSendType" SG_ 1091 RDK_xx_Soll_Druck "Cyclic";
BA_ "GenSigSendType" SG_ 1091 RKA_Warnungen "OnChange";
BA_ "GenSigSendType" SG_ 1091 RKA_FMVSS_138_Warnung "OnChange";
BA_ "GenSigSendType" SG_ 1091 RKA_FMVSS_138_MIL "OnChange";
BA_ "GenSigSendType" SG_ 1091 RKA_Ack_IstZu_Solldruecke "OnChange";
BA_ "GenSigSendType" SG_ 1091 RKA_Menue "Cyclic";
BA_ "GenSigSendType" SG_ 1091 RKA_Akustik "Cyclic";
BA_ "GenMsgCycleTime" BO_ 1472 20;
BA_ "GenMsgSendType" BO_ 1472 "Cyclic";
BA_ "GenSigSendType" SG_ 1472 EP1_QualNeigWi "Cyclic";
BA_ "GenSigSendType" SG_ 1472 EP1_Zaehler "Cyclic";
BA_ "GenSigSendType" SG_ 1472 EP1_Fehler_Sta "Cyclic";
BA_ "GenSigSendType" SG_ 1472 EP1_Sta_EPB "Cyclic";
BA_ "GenSigSendType" SG_ 1472 EP1_Sta_Schalter "Cyclic";
BA_ "GenSigSendType" SG_ 1472 EP1_Spannkraft "Cyclic";
BA_ "GenSigSendType" SG_ 1472 EP1_Schalterinfo "Cyclic";
BA_ "GenSigSendType" SG_ 1472 EP1_Sta_NWS "Cyclic";
BA_ "GenSigSendType" SG_ 1472 EP1_Neig_winkel "Cyclic";
BA_ "GenSigSendType" SG_ 1472 EP1_Verzoegerung "Cyclic";
BA_ "GenSigSendType" SG_ 1472 EP1_Fehlereintr "Cyclic";
BA_ "GenSigSendType" SG_ 1472 EP1_Freigabe_Ver "Cyclic";
BA_ "GenSigSendType" SG_ 1472 EP1_AutoHold_zul "Cyclic";
BA_ "GenSigSendType" SG_ 1472 EP1_AutoHold_aktiv "Cyclic";
BA_ "GenSigSendType" SG_ 1472 EP1_SleepInd "Cyclic";
BA_ "GenSigSendType" SG_ 1472 EP1_Status_Kl_15 "Cyclic";
BA_ "GenSigSendType" SG_ 1472 EP1_Lampe_AutoP "Cyclic";
BA_ "GenSigSendType" SG_ 1472 EP1_Bremslicht "Cyclic";
BA_ "GenSigSendType" SG_ 1472 EP1_Warnton1 "Cyclic";
BA_ "GenSigSendType" SG_ 1472 EP1_Warnton2 "Cyclic";
BA_ "GenSigSendType" SG_ 1472 EP1_AnfShLock "Cyclic";
BA_ "GenSigSendType" SG_ 1472 EPB_Autoholdlampe "Cyclic";
BA_ "GenSigSendType" SG_ 1472 EP1_KuppModBer "Cyclic";
BA_ "GenSigSendType" SG_ 1472 EP1_HydrHalten "Cyclic";
BA_ "GenSigSendType" SG_ 1472 EP1_Fkt_Lampe "Cyclic";
BA_ "GenSigSendType" SG_ 1472 EP1_Warnton "Cyclic";
BA_ "GenSigSendType" SG_ 1472 EP1_Fehler_BKL "Cyclic";
BA_ "GenSigSendType" SG_ 1472 EP1_Fehler_gelb "Cyclic";
BA_ "GenSigSendType" SG_ 1472 EP1__Text "Cyclic";
BA_ "GenSigSendType" SG_ 1472 EP1_Checksum "Cyclic";
BA_ "GenMsgCycleTime" BO_ 65 1000;
BA_ "GenMsgSendType" BO_ 65 "Cyclic";
BA_ "GenSigSendType" SG_ 65 Airbag_03_CRC "Cyclic";
BA_ "GenSigSendType" SG_ 65 Airbag_03_BZ "Cyclic";
BA_ "GenSigSendType" SG_ 65 AB_MKB_Anforderung "OnChangeWithRepetition";
BA_ "GenSigSendType" SG_ 65 AB_MKB_gueltig "Cyclic";
BA_ "GenSigSendType" SG_ 65 AB_MKB_Safing "OnChangeWithRepetition";
BA_ "GenMsgSendType" BO_ 1658 "NoMsgSendType";
BA_ "GenSigSendType" SG_ 1658 BAP_Data_Anzeige_02 "OnChange";
BA_ "GenMsgSendType" BO_ 1750 "NoMsgSendType";
BA_ "GenSigSendType" SG_ 1750 BAP_Data_Debug_Cmd "OnChange";
BA_ "GenMsgSendType" BO_ 1811 "NoMsgSendType";
BA_ "GenSigSendType" SG_ 1811 ISO_ABS_Req_Data "OnChange";
BA_ "GenMsgSendType" BO_ 1792 "NoMsgSendType";
BA_ "GenSigSendType" SG_ 1792 ISO_ALL_01_Req_Data "OnChange";
BA_ "GenMsgSendType" BO_ 1751 "NoMsgSendType";
BA_ "GenSigSendType" SG_ 1751 BAP_Debug_Data "OnChange";
BA_ "GenMsgSendType" BO_ 1771 "NoMsgSendType";
BA_ "GenSigSendType" SG_ 1771 BAP_Data_RDK_02 "OnChange";
BA_ "GenMsgSendType" BO_ 1917 "NoMsgSendType";
BA_ "GenSigSendType" SG_ 1917 ISO_ABS_Resp_Data "OnChange";
BA_ "GenMsgCycleTime" BO_ 1482 200;
BA_ "GenMsgSendType" BO_ 1482 "Cyclic";
BA_ "GenSigSendType" SG_ 1482 EP2_Checksum "Cyclic";
BA_ "GenSigSendType" SG_ 1482 EP2_Zaehler "Cyclic";
BA_ "GenSigSendType" SG_ 1482 EPB_Status "OnChange";
VAL_ 1186 TSK_Wunschgeschw 1023 "kein_Wert_im_Speicher" 1022 "keine_Anzeige" ;
VAL_ 1186 TSK_Texte_Primaeranz 14 "Popup_Geschw_zu_hoch__Resume_unzulaessig" 13 "Limiter_Symbol_aktiv_xxx_kmh_mph" 12 "Limiter_Symbol_passiv_xxx_kmh_mph" 11 "Limiter_Fehler_mit_Akustik" 10 "Limiter_passiv_mit_Akustik" 9 "Opt_GeschwWarnung_dauerhaft_mit_einmal_Akustik" 8 "Opt_und_akustische_GeschwWarnung" 7 "Opt_Geschwindigkeitswarnung" 6 "ACC_Modus_aktiviert" 5 "GRA_Modus_aktiviert" 4 "Limiter_Modus_aktiviert" 3 "Bremse_ueberhitzt" 2 "GRA_Symbol_aktiv_xxx_kmh_mph" 1 "GRA_Symbol_passiv_xxx_kmh_mph" 0 "keine_Anzeige" ;
VAL_ 1186 TSK_Limiter_Fahrerinfo 3 "Vom_Fahrer_Ueberstimmt" 2 "Ueberschritten" 1 "Limit_erreicht" 0 "keine_Info" ;
VAL_ 1186 TSK_Limiter_Anzeige 1 "Display_Anzeige_Limiter" 0 "Display_Anzeige_GRA_ACC" ;
VAL_ 1186 TSK_Status_Anzeige 7 "irreversibel_aus" 6 "reversibel_aus" 5 "Limitierung_aktiv" 4 "Uebertreten" 3 "aktiv" 2 "passiv" 1 "Init" 0 "Hauptschalter_aus" ;
VAL_ 1343 SCR_Zustand 15 "reserved" 14 "reserved" 13 "reserved" 12 "reserved" 11 "reserved" 10 "reserved" 9 "Keine_RRW_Anzeige" 8 "Gefrorenes_Medium" 7 "Schraeglage" 6 "Systemfehler_2" 5 "Systemfehler_1" 4 "Warnstufe_2" 3 "Warnstufe_1" 2 "Hinweis_Fuellstand" 1 "Normale_Funktion" 0 "Initialisierung" ;
VAL_ 1343 SCR_Retriggersignal 1 "Retrigger_aktiv" 0 "Retrigger_nicht_aktiv" ;
VAL_ 1343 SCR_Nachfuellmenge_min 127 "Initwert" ;
VAL_ 1343 SCR_Nachfuellmenge_max 255 "Initwert" ;
VAL_ 1343 SCR_Nachfuellmenge_Einheit 3 "reserved" 2 "Gallone_UK" 1 "Gallone_US" 0 "Liter" ;
VAL_ 1343 SCR_Einheit 1 "miles" 0 "km" ;
VAL_ 1343 SCR_Fuellstand 127 "Initwert" ;
VAL_ 1160 MO6_SollM_Getr 255 "Fehler" ;
VAL_ 1160 MO6_Ist_Moment 255 "Fehler" ;
VAL_ 1160 MO6_Hoeheninfo 255 "Fehler" ;
VAL_ 1160 MO6_GRA_Soll 255 "nicht_erlaubt" 254 "GRA_aus" ;
VAL_ 1160 MO6_MomIntGeEing 255 "volle_Verfuegbarkeit_akt_vorh" 0 "Integral_bis_Limit_gefuellt" ;
VAL_ 1160 MO6_FF_Mux05 255 "nicht_genutzt" ;
VAL_ 1160 MO6_FF_Mux06 255 "nicht_genutzt" ;
VAL_ 1160 MO6_FF_Mux07 255 "nicht_genutzt" ;
VAL_ 1160 MO6_FF_Mux08 255 "nicht_genutzt" ;
VAL_ 1160 MO6_FF_Mux09 255 "nicht_genutzt" ;
VAL_ 1160 MO6_FF_Mux10 255 "nicht_genutzt" ;
VAL_ 1160 MO6_FF_Mux11 255 "nicht_genutzt" ;
VAL_ 1160 MO6_FF_Mux12 255 "nicht_genutzt" ;
VAL_ 1160 MO6_FF_Mux13 255 "nicht_genutzt" ;
VAL_ 1160 MO6_FF_Mux14 255 "nicht_genutzt" ;
VAL_ 1160 MO6_FF_Mux15 255 "nicht_genutzt" ;
VAL_ 1160 MO6_Freigabe_GRA 1 "freigegeben" 0 "nicht_freigegeben" ;
VAL_ 1160 MO6_Schutz_Toel 1 "Schaltanforderung" 0 "keine_Anforderung" ;
VAL_ 1160 MO6_Luftpfad_akt 1 "Eingriff_ueber_Luftpfad" 0 "keinEingriff_od_nur_ueb_Zundpfad" ;
VAL_ 1160 MO6_RegPartikel 1 "Beeinflussung" 0 "keine_Beeinflussung" ;
VAL_ 1162 MO8_AnzeigeDZ 4095 "Fehler" ;
VAL_ 1162 MO_Effizienzmodus 1 "Effizienz_Modus" 0 "nicht_im_Effizienz_Modus" ;
VAL_ 1162 MO8_SGT_Soundakt 1 "Anf_des_Stellgliedtests" 0 "kein_Stellgliedtest" ;
VAL_ 1162 MO8_Spoiler_ausf 1 "Spoiler_ausfahren" 0 "Spoiler_nicht_ausfahren" ;
VAL_ 1162 MO8_Sportschalter 1 "Sportschalter_aktiv" 0 "Sportschalter_nicht_aktiv" ;
VAL_ 1162 MO8_LampeDZBegr 1 "Lampe_ein" 0 "Lampe_aus" ;
VAL_ 1162 MO8_Enable_Oeldr_Motor 1 "Oeldruckausw_Motor" 0 "Oeldruckausw_Kombi" ;
VAL_ 1162 MO8_Oeldr_Warn_Motor 1 "Lampe_ein" 0 "Lampe_aus" ;
VAL_ 1162 MO8_Avus_Motorschutz 3 "DZwarnung_3" 2 "DZwarnung_2" 1 "DZwarnung_1" 0 "keine_Warnung" ;
VAL_ 1162 MO8_Anzeigecode 1 "Leistung_Antriebsstrang__Powermeter" 0 "Anzeigedrehzahl" ;
VAL_ 1162 MO_P_verriegelt 3 "Fehler" 2 "verriegelt" 1 "nicht_verriegelt" 0 "Init" ;
VAL_ 1162 MO_Schaltempf_verfbar 1 "verfuegbar" 0 "nicht_verfuegbar" ;
VAL_ 1162 MO_Istgang 9 "Gang_9" 8 "Gang_8" 7 "Gang_7" 6 "Gang_6" 5 "Gang_5" 4 "Gang_4" 3 "Gang_3" 2 "Gang_2" 1 "Gang_1" 0 "kein_Gang_eingelegt" ;
VAL_ 1162 MO_Sollgang 15 "Neutralgang" 9 "Gang_9" 8 "Gang_8" 7 "Gang_7" 6 "Gang_6" 5 "Gang_5" 4 "Gang_4" 3 "Gang_3" 2 "Gang_2" 1 "Gang_1" 0 "keine_Empfehlung" ;
VAL_ 1800 MC1_Anz_Betrieb 1 "Gasbetrieb" 0 "Benzinbetrieb" ;
VAL_ 1800 MC1_Schalter 1 "Gasbetrieb" 0 "Benzin_od_Schalter_nicht_verb" ;
VAL_ 1800 MC1_akt_Betrieb 1 "Gasbetrieb" 0 "Benzinbetrieb" ;
VAL_ 1800 MC1_CNG_LPG 1 "LPG" 0 "CNG" ;
VAL_ 1800 MO_LPG_Tankstopp 1 "Tankstopp_erkannt" 0 "kein_Tankstopp" ;
VAL_ 1800 MO_Erdgasqualitaet 7 "nicht_definiert" 6 "nicht_definiert" 5 "Qualitaet_70Proz" 4 "Qualitaet_80Proz" 3 "Qualitaet_90Proz" 2 "Qualitaet_100Proz" 1 "Anzeige_waehrend_QualAdaption_nach_Betankung_oder_Fehler" 0 "Anzeige_in_MFA_nicht_auswaehlbar" ;
VAL_ 1800 MC1_Fuellungsgrad 255 "Fehler" 254 "Initialisierung_Tankgeber" ;
VAL_ 1800 MC1_Ueb_Verbr 1 "mind_1_Ueberlauf" 0 "kein_Ueberlauf" ;
VAL_ 1800 MO_AnzeigeGasbetrieb 7 "Benzintank_leer" 6 "Gasbetrieb_nicht_moeglich" 5 "Umschaltung_nicht_moeglich" 4 "Benzinbetrieb" 3 "Umschaltung_Benzinbetrieb" 2 "Gasbetrieb" 1 "Umschaltung_Gasbetrieb" 0 "keine_Textmeldung" ;
VAL_ 1800 MO_Gastemperatur 255 "Anzeige_Striche" 0 "Init_nicht_verfuegbar" ;
VAL_ 1800 MO_Verbrauchsaequivalent 255 "Fehler" 254 "Init_Adaption_nach_Betankung" 0 "Funktion_nicht_unterstuetzt" ;
VAL_ 1562 MO_Red_FahrleistungsLampe 1 "Lampe_ein" 0 "Lampe_aus" ;
VAL_ 1562 Ladestecker_gesteckt 1 "aktiv" 0 "inaktiv" ;
VAL_ 1562 Ladevorgang_aktiv 1 "aktiv" 0 "inaktiv" ;
VAL_ 1562 HV_Bordnetz_aktiv 1 "aktiv" 0 "inaktiv" ;
VAL_ 1562 HV_PTC_LeistRed 3 "LeistBegr_25" 2 "LeistBegr_50" 1 "LeistBegr_75" 0 "keine_LeistBegr" ;
VAL_ 1562 HV_PTC_aus 1 "aktiv" 0 "inaktiv" ;
VAL_ 1562 Ladestecker_verr_Status 3 "Fehler" 2 "Init" 1 "verriegelt" 0 "entriegelt" ;
VAL_ 1562 HV_Anf_ReichweiteNV 3 "Fehler" 2 "Eskalationsstufe_2" 1 "Eskalationsstufe_1" 0 "keine_Massnahmen_Init" ;
VAL_ 1562 MO_Wahl_Pos 6 "B" 5 "D" 4 "N" 3 "R" 2 "P" 0 "Init" ;
VAL_ 1562 QB_Ladestecker_gesteckt 1 "Ersatz_Init_oder_Fehlerwert" 0 "gueltiger_Wert" ;
VAL_ 1562 MO_Fehler_Notabschaltung_Klima 3 "ohne_Funktion" 2 "HVIL_Fehler" 1 "HVIL_ist_OK" 0 "Init" ;
VAL_ 1562 QB_Ladezustand_HV_Batterie 1 "Ersatz_Init_oder_Fehlerwert" 0 "gueltiger_Wert" ;
VAL_ 1562 BMS_Temperierung_Anf 7 "Umwaelzungsbedarf" 6 "hoher_Heizbedarf" 5 "mittlerer_Heizbedarf" 4 "niedriger_Heizbedarf" 3 "kein_Temperierungsbedarf_Init" 2 "niedriger_Kuehlbedarf" 1 "mittlerer_Kuehlbedarf" 0 "hoher_Kuehlbedarf" ;
VAL_ 1562 Energieinhalt_HV_Batt 511 "Fehler" 510 "Init" ;
VAL_ 1562 Ladezustand_HV_Batterie 255 "Fehler" ;
VAL_ 1154 MH1_VM_Mom_oE 255 "Fehler" ;
VAL_ 1154 MH1_IstStatusK0 3 "Fehler" 2 "zu" 1 "Uebergang" 0 "auf" ;
VAL_ 1154 MH1_Startmodus_PQ35 1 "Direktstart" 0 "Impulsstart" ;
VAL_ 1154 MH1_VM_aktiv 1 "VM_aktiv" 0 "VM_nicht_aktiv" ;
VAL_ 1154 MH1_Zielzustand_Hybrid 7 "Fehler" 5 "Fahrbereit_VM" 4 "Fahrbereit_EM" 3 "EM_Fahren" 2 "hyb_Fahren" 1 "LL_VM" 0 "Init" ;
VAL_ 1154 MH1_Schaltverh 1 "Schaltverhinderung" 0 "keine_Schaltverh" ;
VAL_ 1154 MH1_VerlParam_Msum 3 "KnickDZ_EM_Kurve" 2 "max_EM_Moment" 1 "KnickDZ_Rekup_Kurve" 0 "max_Rekup_Mom" ;
VAL_ 1154 MH1_E_Faktor 15 "minus1" 14 "minus2" 13 "minus3" 12 "minus4" 11 "minus5" 10 "minus6" 9 "minus7" 8 "minus8" 7 "plus7" 6 "plus6" 5 "plus5" 4 "plus4" 3 "plus3" 2 "plus2" 1 "plus1" 0 "VM_Kennfeld" ;
VAL_ 1154 MH1_Drehzahl_VM 65280 "Fehler" ;
VAL_ 1154 MH1_max_ind_VM_Mom 255 "Fehler" ;
VAL_ 1154 MH1_Notstart 1 "Notstart_aktiv" 0 "kein_Notstart" ;
VAL_ 1154 MH1_LowSpeedModus 1 "LowSpeed_ohne_LL_DZ" 0 "LowSpeed_mit_LL_DZ" ;
VAL_ 1154 MH1_ACCGRA_aktiv 1 "GRAACC_aktiv" 0 "GRAACC_nicht_aktiv" ;
VAL_ 1154 MH1_EMode_Info 3 "nicht_relevant" 2 "nicht_relevant" 1 "Depleting_Mode" 0 "Normal_Mode" ;
VAL_ 1154 MH1_QB_Bremspedalwert 1 "Ersatz_Init_oder_Fehlerwert" 0 "gueltiger_Wert" ;
VAL_ 1154 MH1_Bremspedalwert 255 "Fehler" ;
VAL_ 1823 MSI_KD_Fehler 1 "Fehlerspeichereintrag" 0 "kein_Fehlerspeichereintrag" ;
VAL_ 1428 NI2_Hoehenflag 1 "Rohwerte" 0 "kalibrierte_Hoehenwerte" ;
VAL_ 1428 NI2_Hoehe_VL 255 "Fehler" 254 "nicht_initialisiert" ;
VAL_ 1428 NI2_Hoehe_VL_Roh 255 "Fehler" 254 "nicht_initialisiert" 253 "notdef" 252 "" 251 "notdef" ;
VAL_ 1428 NI2_Hoehe_VR 255 "Fehler" 254 "nicht_initialisiert" ;
VAL_ 1428 NI2_Hoehe_VR_Roh 255 "Fehler" 254 "nicht_initialisiert" 253 "notdef" 252 "notdef" 251 "notdef" ;
VAL_ 1428 NI2_Hoehe_HL 255 "Fehler" 254 "nicht_initialisiert" ;
VAL_ 1428 NI2_Hoehe_HL_Roh 255 "Fehler" 254 "nicht_initialisiert" 253 "notdef" 252 "notdef" 251 "notdef" ;
VAL_ 1428 NI2_Hoehe_HR 255 "Fehler" 254 "nicht_initialisiert" ;
VAL_ 1428 NI2_Hoehe_HR_Roh 255 "Fehler" 254 "nicht_initialisiert" 253 "notdef" 252 "notdef" 251 "notdef" ;
VAL_ 1428 NI2_AufbBeschl_VL 255 "Fehler" 254 "notdef" ;
VAL_ 1428 NI2_AufbBeschl_VR 255 "Fehler" 254 "notdef" ;
VAL_ 1349 PA3_KD_Fehler 1 "Fehlerspeichereintrag" 0 "kein_Fehlerspeichereintrag" ;
VAL_ 1355 PA5_VL_Abstand 255 "kein_Hindernis" ;
VAL_ 1355 PA5_VR_Abstand 255 "kein_Hindernis" ;
VAL_ 1355 PA5_HL_Abstand 255 "kein_Hindernis" ;
VAL_ 1355 PA5_HR_Abstand 255 "kein_Hindernis" ;
VAL_ 1355 PA5_VML_Abstand 255 "kein_Hindernis" ;
VAL_ 1355 PA5_VMR_Abstand 255 "kein_Hindernis" ;
VAL_ 1355 PA5_HML_Abstand 255 "kein_Hindernis" ;
VAL_ 1355 PA5_HMR_Abstand 255 "kein_Hindernis" ;
VAL_ 1166 PLA_Status_Aktive_Seite 1 "Links" 0 "Rechts" ;
VAL_ 1166 PLA_Anf_Anzeige_Mini 1 "Anzeige Mini" 0 "keine Anzeige" ;
VAL_ 1166 PLA_Mini_Modus 3 "Mini Vorwaerts Querparken" 2 "Mini Rueckwaerts Querparken" 1 "Mini Laengsparken" 0 "kein Mini angezeigt" ;
VAL_ 1166 PLA_Anf_Akustik 1 "Akustik (Gong 1000)" 0 "keine Akustik" ;
VAL_ 1166 PLA_Anf_Anzeige_Schwellpfeil 1 "Anzeige Schwellpfeil" 0 "Keine Schwellpfeilanzeige" ;
VAL_ 1166 PLA_Anf_Anzeige_Bremsfuss 1 "Anzeige_Bremsfuss" 0 "Keine_Anzeige_Bremsfuss" ;
VAL_ 1166 PLA_Anf_Funktionsdisclaimer 3 "Ausparken Laengsparken" 2 "Vorwaerts Querparken" 1 "Rueckwaerts Querparken" 0 "Laengsparken" ;
VAL_ 1166 PLA_Anf_Anzeigemodus 15 "Reserved" 14 "Reserved" 13 "Reserved" 12 "Textmeldungen niederprior" 11 "Textmeldung hochprior" 10 "Reserved" 9 "Reserved" 8 "Ausparken Laengsparken Singlescreen" 7 "Reserved" 6 "Vorwaerts Querparken Singlescreen" 5 "Reserved" 4 "Rueckwaerts Querparken Singlescreen" 3 "Reserved" 2 "Laengsparken Singlescreen" 1 "Reserved" 0 "Keine Anzeige" ;
VAL_ 1166 PLA_Anf_Meldungen 0 "keine Meldung" ;
VAL_ 1166 PLA_Status_Funktion 15 "Reserved" 14 "Reserved" 13 "Reserved" 12 "Reserved" 11 "Reserved" 10 "Reserved" 9 "Reserved" 8 "Reserved" 7 "Reserved" 6 "Disclaimer in Anzeige" 5 "Rangieren rueckwaerts" 4 "Rangieren vorwaerts" 3 "POS OK" 2 "PL gefunden" 1 "PL- Suche Standby" 0 "PL- Suche" ;
VAL_ 1166 PLA_Status_beenden_Mini 3 "Funktion nicht vorhanden" 2 "Funktion einparken moeglich" 1 "Funktion ausgewaehlt" 0 "Funktion vorhanden" ;
VAL_ 1166 PLA_Status_Laengsparken_Mini 3 "Funktion nicht vorhanden" 2 "Funktion einparken moeglich" 1 "Funktion ausgewaehlt" 0 "Funktion vorhanden" ;
VAL_ 1166 PLA_Status_QP_Rueckw_Mini 3 "Funktion nicht vorhanden" 2 "Funktion einparken moeglich" 1 "Funktion ausgewaehlt" 0 "Funktion vorhanden" ;
VAL_ 1166 PLA_Status_QP_Vorw_Mini 3 "Funktion nicht vorhanden" 2 "Funktion einparken moeglich" 1 "Funktion ausgewaehlt" 0 "Funktion vorhanden" ;
VAL_ 714 QS2_Ist_Wert 255 "Fehler" ;
VAL_ 714 QS2_Soll_Wert 255 "Fehler" ;
VAL_ 714 QS2_Status_VAQ 6 "Fehler_zu" 5 "norm_Abschaltung" 4 "norm_mit_ESP_Eing" 3 "norm_ohne_ESP_Eing" 2 "Kom_gestoert" 1 "Fehler_auf" 0 "Init" ;
VAL_ 714 QS2_Gleichlauf 1 "Gleichlauf" 0 "Schlupf" ;
VAL_ 714 QS2_KD_Fehler 1 "Fehlerspeichereintrag" 0 "kein_Fehlerspeichereintrag" ;
VAL_ 1306 TOG_Fuellstand_1 2047 "unguelt_Wert_oder_Bereichsueberl" 1 "Init" 0 "kein_Wert" ;
VAL_ 1306 TOG_Fuellstand_2 2047 "unguelt_Wert_oder_Bereichsueberl" 1 "Init" 0 "kein_Wert" ;
VAL_ 1306 TOG_Fuellstand_3 2047 "unguelt_Wert_oder_Bereichsueberl" 1 "Init" 0 "kein_Wert" ;
VAL_ 1306 TOG_Fuellstand_4 2047 "unguelt_Wert_oder_Bereichsueberl" 1 "Init" 0 "kein_Wert" ;
VAL_ 1306 TOG_Oeltempzeit 1023 "Bereichsueberl" 1 "Init" 0 "kein_Wert" ;
VAL_ 1306 TOG_Sensorfehler 1 "Fehler" 0 "Sensor_iO" ;
VAL_ 1306 TOG_Oelwarn_hoch 1 "Schwelle_ueberschritten" 0 "Schwelle_nicht_ueberschritten" ;
VAL_ 1306 TOG_OelwarnUeber 1 "Schwelle_ueberschritten" 0 "Schwelle_nicht_ueberschritten" ;
VAL_ 1306 TOG_OelmaxUeber 1 "Schwelle_ueberschritten" 0 "Schwelle_nicht_ueberschritten" ;
VAL_ 1306 TOG_Oelmax_hoch 1 "Schwelle_ueberschritten" 0 "Schwelle_nicht_ueberschritten" ;
VAL_ 1096 WH1_StaShiftlock 7 "Shiftlock_ist_fehlerhaft" 6 "nicht_verbaut" 3 "Shiftlock_ist_aktiviert" 2 "Shiftlock_ist_deaktiviert" 0 "Initwert" ;
VAL_ 1096 WH1_Init 1 "Initphase" 0 "keine_Initphase" ;
VAL_ 1096 WH1_Position 15 "Fehler" 14 "Tipp_Gasse" 13 "Position_L" 12 "Position_S_Sport" 11 "Position_Tipp_minus" 10 "Position_Tipp_plus" 9 "Position_N_ohne_Spotausl" 8 "Position_P_Stop" 7 "Position_R" 6 "Position_N" 5 "Position_D" 4 "Position_4" 3 "Position_3" 2 "Position_2" 1 "Position_1" ;
VAL_ 1096 WH1_Status 128 "Mehrfacher_Sensorfehler" 64 "Einfacher_Sensorfehler" 32 "Einfacher_Sensorfehler" 16 "Reserve" 8 "Reserve" 4 "Reserve" 2 "Reserve" 1 "Shiftlockfehler" 0 "fehlerfrei" ;
VAL_ 1096 WH1_Test_Flag 1 "Testergebnis_gueltig" 0 "Testergebnis_ungueltig" ;
VAL_ 1096 WH1_Taster_betaetigt 1 "betaetigt" 0 "nicht_betaetigt" ;
VAL_ 1102 WH2_Init 1 "Initphase" 0 "keine_Initphase" ;
VAL_ 1102 WH2_Test_Flag 1 "Testergebnis_gueltig" 0 "Testergebnis_ungueltig" ;
VAL_ 1102 WH2_Sport 1 "Sporttaster_betaetigt" 0 "nicht_betaetigt" ;
VAL_ 1102 WH2_Winter 1 "Wintertaster_betaetigt" 0 "nicht_betaetigt" ;
VAL_ 1102 WH2_Position 7 "Tip_R" 6 "Ruhelage_X" 5 "Zwischenpos_V" 4 "Tip_D" 3 "Tip_minus" 2 "Tip_plus" 1 "Ruhelage_U" 0 "ungueltig" ;
VAL_ 1102 WH2_P_Taster 3 "Fehler" 2 "P_Taster_betaetigt" 1 "P_Taster_nicht_betaetigt" 0 "Init" ;
VAL_ 1102 WH2_Ruhestromfehler 1 "Ruhestromfehler" 0 "kein_Ruhestromfehler" ;
VAL_ 1102 WH2_Sensorarray_Einfachfehler 1 "Sensorik_Einzelfehler" 0 "kein_Sensorik_Einzelfehler" ;
VAL_ 1102 WH2_Sensorarray_Mehrfachfehler 1 "Sensorik_Mehrfachfehler" 0 "kein_Sensorik_Mehrfachfehler" ;
VAL_ 1102 WH2_Fehler_Sporttaster 1 "Sporttaster_unterbr" 0 "Sporttaster_nicht_unterbr" ;
VAL_ 1102 WH2_Fehler_Fahrstufenanzeige 1 "Anzeige_Waehlhebel_defekt" 0 "keine_defekte_Anzeige" ;
VAL_ 1102 WH2_Fehler_Spannungsversorgung 1 "UnterUebersp_Fehler" 0 "kein_UnterUebersp_Fehler" ;
VAL_ 1102 WH2_Timeout_Kombi_2 1 "Timeout_Kombi2" 0 "kein_Timeout_Kombi2" ;
VAL_ 1102 WH2_Timeout_Getriebe_5 1 "Timeout_Getriebe5" 0 "kein_Timeout_Getriebe5" ;
VAL_ 1102 WH2_Timeout_Gate_Komf_1 1 "Timeout_GateKomf1" 0 "kein_Timeout_GateKomf1" ;
VAL_ 919 ZK5_Endlage_ausgefahren 1 "Endlage_erreicht" 0 "Endlage_nicht_erreicht" ;
VAL_ 919 ZK5_Endlage_eingefahren 1 "Endlage_erreicht" 0 "Endlage_nicht_erreicht" ;
VAL_ 919 ZV_SafeFunktion_aktiv 1 "aktiv" 0 "inaktiv" ;
VAL_ 919 ZK5_VD_Endlage_geschl 1 "Endlage_erreicht" 0 "Endlage_nicht_erreicht" ;
VAL_ 919 ZK5_VD_Endlage_abgelegt 1 "Endlage_erreicht" 0 "Endlage_nicht_erreicht" ;
VAL_ 919 ZK5_VD_Verbau 1 "man_Verdeck" 0 "autom_Verdeck" ;
VAL_ 919 VIP_Freigabe 1 "Freigabe" 0 "keine_Freigabe" ;
VAL_ 1523 OBD_TG_F_Status_1 15 "frei" 14 "frei" 13 "frei" 12 "frei" 11 "KS_MP_OC" 10 "KS_MP" 9 "KS_M_OC" 8 "KS_P_OC" 7 "RC_M" 6 "RC_P" 5 "OOR_M" 4 "OOR_P" 3 "OC" 2 "KS_P" 1 "KS_M" 0 "kein_Fehler" ;
VAL_ 1523 OBD_TG_F_Status_2 15 "frei" 14 "frei" 13 "frei" 12 "frei" 11 "KS_MP_OC" 10 "KS_MP" 9 "KS_M_OC" 8 "KS_P_OC" 7 "RC_M" 6 "RC_P" 5 "OOR_M" 4 "OOR_P" 3 "OC" 2 "KS_P" 1 "KS_M" 0 "kein_Fehler" ;
VAL_ 1523 OBD_TG_F_Status_3 15 "frei" 14 "frei" 13 "frei" 12 "frei" 11 "KS_MP_OC" 10 "KS_MP" 9 "KS_M_OC" 8 "KS_P_OC" 7 "RC_M" 6 "RC_P" 5 "OOR_M" 4 "OOR_P" 3 "OC" 2 "KS_P" 1 "KS_M" 0 "kein_Fehler" ;
VAL_ 1523 OBD_TG_F_Status_4 15 "frei" 14 "frei" 13 "frei" 12 "frei" 11 "KS_MP_OC" 10 "KS_MP" 9 "KS_M_OC" 8 "KS_P_OC" 7 "RC_M" 6 "RC_P" 5 "OOR_M" 4 "OOR_P" 3 "OC" 2 "KS_P" 1 "KS_M" 0 "kein_Fehler" ;
VAL_ 1175 PH_Freie_Weglaenge_Heck 511 "Fehler" 510 "Init" ;
VAL_ 1175 PH_Freie_Weglaenge_Heck_Typ 1 "Hindernis_detektiert" 0 "Maximaler_Messbereich" ;
VAL_ 1175 PH_nachtr_Stopp_Anf 1 "angefordert" 0 "nicht_angefordert" ;
VAL_ 1175 PH_Abschaltursache 7 "Fehler" 5 "Kl_15_Bit_Null" 4 "PLA_Absch" 3 "PDC_Taster_Absch" 2 "v_Absch" 1 "Absch_Herausn_RGang" 0 "keine_Sys_aktiv" ;
VAL_ 1175 PH_Opt_Anzeige_V_ein 1 "opt_Anzeige_vorn_aktiv" ;
VAL_ 1175 PH_Opt_Anzeige_H_ein 1 "opt_Anzeige_hinten_aktiv" ;
VAL_ 1175 PH_Opt_Anz_V_Hindernis 1 "vorn_Hind_im_Warnbereich" ;
VAL_ 1175 PH_Opt_Anz_H_Hindernis 1 "hinten_Hind_im_Warnbereich" ;
VAL_ 1175 PH_Tongeber_V_aktiv 1 "Tongeber_vorne_aktiv" ;
VAL_ 1175 PH_Tongeber_H_aktiv 1 "Tongeber_hinten_aktiv" ;
VAL_ 1175 PH_Tongeber_mute 1 "Tongeber_stumm" ;
VAL_ 1175 PH_Anf_Audioabsenkung 1 "Anf_Audioabsenkung" ;
VAL_ 1175 PH_Tongeber_H_verfuegbar 1 "verfuegbar" 0 "nicht_verfuegbar" ;
VAL_ 1175 PLA_Anf_Aufschaltung_RVC 1 "RVC_Aufschalteanforderung" 0 "Keine_RVC_Aufschalteanf" ;
VAL_ 1175 PH_Stoermeldung 6 "Textmeldung \"PDC gestoert\" ohne Gong" 5 "Textmeldung \"PDC gestoert\" mit Gong" 4 "Textmeldung \"PDC vorn gestoert\" ohne Gong" 3 "Textmeldung \"PDC vorn gestoert\" mit Gong" 2 "Textmeldung \"PDC hinten gestoert\" ohne Gong" 1 "Textmeldung \"PDC hinten gestoert\" mit Gong" 0 "keine Anzeige / kein Gong (PDC nicht aktiv bzw. fehlerfrei)" ;
VAL_ 1175 PH_Anf_Verdeck 3 "reserviert" 2 "reserviert" 1 "Verdeckbetrieb_sperren" 0 "Verdeckbetrieb_freigegeben" ;
VAL_ 1175 PH_StartStopp_Info 3 "Systemfehler" 2 "Motoranlauf_zwingend_notwendig_(Startanforderung)" 1 "Motoranlauf_nicht_zwingend_notwendig_(Stoppverbot,keine_Startanforderung)" 0 "Motorlauf_nicht_notwendig_(Stoppfreigabe)" ;
VAL_ 1175 PH_BerErk_vorn 3 "Kollisionsbereich" 2 "Hauptwarnbereich" 1 "Vorwarnbereich_nur_NFZ" 0 "Init" ;
VAL_ 1175 PH_BerErk_hinten 3 "Kollisionsbereich" 2 "Hauptwarnbereich" 1 "Vorwarnbereich_nur_NFZ" 0 "Init" ;
VAL_ 1175 PH_defekt 1 "PH_wg_Defekt_deaktiv" ;
VAL_ 1175 PH_gestoert 1 "PH_wg_Stoerung_temp_deaktiv" ;
VAL_ 1175 PH_Systemzustand 7 "Fehler_gestoert" 3 "Anlage_auto_akt" 2 "Anlage_man_akt" 1 "Anlage_wg_RGang_akt" 0 "Anlage_aus" ;
VAL_ 1175 PH_Display_Kundenwunsch 3 "automatisch" 2 "Rear_View" 1 "Graphik" 0 "Anzeige_aus" ;
VAL_ 1175 PH_KD_Fehler 1 "Fehlerspeichereintrag" 0 "kein_Fehlerspeichereintrag" ;
VAL_ 695 RCTA_Info_rechts 7 "RCTA_meldet_rechts_Kollision_steht_bevor" 6 "RCTA_hat_rechts_sehr_kritisch_erkannt" 5 "RCTA_hat_rechts_kritisch_erkannt" 4 "RCTA_hat_rechts_relevant_aber_unkritisch_erkannt" 3 "RCTA_hat_rechts_unkritisch_erkannt" 2 "RCTA_hat_rechts_frei_erkannt" 1 "RCTA_hat_rechts_blind_erkannt" 0 "RCTA_hat_rechts_nichts_erkannt" ;
VAL_ 695 RCTA_Anforderung_HMS 5 "loesen_ueber_Rampe" 4 "anfahren" 3 "Halten Standby" 2 "parken" 1 "halten" 0 "keine_Anforderung" ;
VAL_ 695 RCTA_Info_links 7 "RCTA_meldet_links_Kollision_steht_bevor" 6 "RCTA_hat_links_sehr_kritisch_erkannt" 5 "RCTA_hat_links_kritisch_erkannt" 4 "RCTA_hat_links_relevant_aber_unkritisch_erkannt" 3 "RCTA_hat_links_unkritisch_erkannt" 2 "RCTA_hat_links_frei_erkannt" 1 "RCTA_hat_links_blind_erkannt" 0 "RCTA_hat_links_nichts_erkannt" ;
VAL_ 695 RCTA_Warnton 1 "Ein" 0 "Aus" ;
VAL_ 695 RCTA_Bremsruck_Anforderung 1 "angefordert" 0 "nicht_angefordert" ;
VAL_ 695 RCTA_Bremsruck_Freigabe 1 "Freigabe" 0 "keine_Freigabe" ;
VAL_ 695 RCTA_Status 3 "Fehler" 2 "Aktiv" 1 "Passiv" 0 "Aus" ;
VAL_ 695 RCTA_Notbremsung_Freigabe 1 "Freigabe" 0 "keine_Freigabe" ;
VAL_ 695 RCTA_Notbremsung_Anforderung 255 "Fehler" 0 "Init" ;
VAL_ 427 ESC_AHW_aktiv 7 "tbd" 6 "tbd" 5 "tbd" 4 "tbd" 3 "Aktivitaet_durch_ACC" 2 "Aktivitaet_durch_ARA" 1 "Aktivitaet_durch_IPA" 0 "keine_Aktivitaet" ;
VAL_ 427 ESC_AHW_nicht_verfuegbar 1 "nicht_verfuegbar" 0 "verfuegbar" ;
VAL_ 427 ESC_ANB_CM_aktiv 1 "Aktivitaet_durch_AWV" 0 "keine_Aktivitaet" ;
VAL_ 427 ESC_ANB_CM_nicht_verfuegbar 1 "nicht_verfuegbar" 0 "verfuegbar" ;
VAL_ 427 ESC_TSK_SRBM_Anf 1 "Aktivitaet_durch_TSK" 0 "keine_Aktivitaet" ;
VAL_ 427 ESC_TSK_SRBM_nicht_verfuegbar 1 "nicht_verfuegbar" 0 "verfuegbar" ;
VAL_ 427 ESC_Bremslicht_unplausibel 1 "unplausibel" 0 "plausibel" ;
VAL_ 427 ESC_Konsistenz_ARA 1 "nicht_konsistent" 0 "konsistent" ;
VAL_ 427 ESC_Konsistenz_IPA 1 "nicht_konsistent" 0 "konsistent" ;
VAL_ 427 ESC_Konsistenz_FCW 1 "nicht_konsistent" 0 "konsistent" ;
VAL_ 427 ESC_Konsistenz_NV 1 "nicht_konsistent" 0 "konsistent" ;
VAL_ 427 ESC_Konsistenz_TSK 1 "nicht_konsistent" 0 "konsistent" ;
VAL_ 427 ESC_Konsistenz_vFGS 1 "nicht_konsistent" 0 "konsistent" ;
VAL_ 427 ESC_Konsistenz_STA 1 "nicht_konsistent" 0 "konsistent" ;
VAL_ 427 ESC_Konsistenz_EA 1 "nicht_konsistent" 0 "konsistent" ;
VAL_ 427 ESC_Konsistenz_BFF 1 "nicht_konsistent" 0 "konsistent" ;
VAL_ 427 ESC_Verz_ASIL_Verfuegbarkeit 7 "reserved" 6 "reserved" 5 "reserved" 4 "Verfuegbar_ab_ASIL_C" 3 "Verfuegbar_ab_ASIL_B" 2 "Verfuegbar_ab_ASIL_A" 1 "Verfuegbar_ab_ASIL_QM" 0 "Nicht_verfuegbar" ;
VAL_ 427 ESC_Pumpenanlauf_aktiv 1 "aktiv" 0 "inaktiv" ;
VAL_ 427 ESC_Konsistenz_AGW 1 "nicht_konsistent" 0 "konsistent" ;
VAL_ 427 ESC_Konsistenz_KAS 1 "nicht_konsistent" 0 "konsistent" ;
VAL_ 427 ESC_Konsistenz_PCF 1 "nicht_konsistent" 0 "konsistent" ;
VAL_ 427 ESC_Warnruck_aktiv 9 "Aktivitaet_durch_AGW" 8 "Aktivitaet_durch_KAS" 7 "Aktivitaet_durch_PCF" 6 "Aktivitaet_durch_EA" 5 "Aktivitaet_durch_FCWP" 4 "Aktivitaet_durch_FCWO" 3 "Aktivitaet_durch_RCTA" 2 "Aktivitaet_durch_vFGS" 1 "Aktivitaet_durch_AWV" 0 "keine_Aktivitaet" ;
VAL_ 427 ESC_Warnruck_nicht_verfuegbar 1 "nicht_verfuegbar" 0 "verfuegbar" ;
VAL_ 427 ESC_Prefill_aktiv 1 "Prefill_aktiv" 0 "keine_Aktivitaet" ;
VAL_ 427 ESC_Prefill_nicht_verfuegbar 1 "nicht_verfuegbar" 0 "verfuegbar" ;
VAL_ 427 ESC_HBA_aktiv 1 "HBA_aktiv" 0 "keine_Aktivitaet" ;
VAL_ 427 ESC_HBA_nicht_verfuegbar 1 "nicht_verfuegbar" 0 "verfuegbar" ;
VAL_ 427 ESC_Verz_Reg_aktiv 15 "Initialisierung" 14 "reserviert" 12 "Aktivitaet_durch_PCF" 11 "Aktivitaet_durch_EA" 10 "Aktivitaet_durch_BFF" 9 "Aktivitaet_durch_MKB" 8 "Aktivitaet_durch_ARA" 7 "Aktivitaet_durch_STA" 6 "Aktivitaet_durch_PLA_IPA" 5 "Aktivitaet_durch_RCTA" 4 "Aktivitaet_durch_TSK" 3 "Aktivitaet_durch_vFGS" 2 "Aktivitaet_ZB_durch_AWV" 1 "Aktivitaet_TB_durch_AWV" 0 "keine_Aktivitaet" ;
VAL_ 427 ESC_Verz_Reg_nicht_verfuegbar 1 "nicht_verfuegbar" 0 "verfuegbar" ;
VAL_ 427 ESC_Verz_Reg_TB_nicht_verfuegbar 1 "nicht_verfuegbar" 0 "verfuegbar" ;
VAL_ 427 ESC_Verz_Reg_ZB_nicht_verfuegbar 1 "nicht_verfuegbar" 0 "verfuegbar" ;
VAL_ 427 ESC_Konsistenz_ACC 1 "nicht_konsistent" 0 "konsistent" ;
VAL_ 427 ESC_Konsistenz_AWV 1 "nicht_konsistent" 0 "konsistent" ;
VAL_ 427 ESC_Konsistenz_RCTA 1 "nicht_konsistent" 0 "konsistent" ;
VAL_ 427 ESC_Fahrer_Bremsdruck_bestimmend 1 "Fahrer_Bremsdruck_bestimmend" 0 "Fahrer_nicht_Bremsdruck_bestimmend" ;
VAL_ 427 ESC_Konsistenz_MKB 1 "nicht_konsistent" 0 "konsistent" ;
VAL_ 1091 RKA_Prio1_Warnung 1 "Prio1_Warnung" 0 "keine_Warnung" ;
VAL_ 1091 RKA_Prio2_Warnung 1 "Prio2_Warnung" 0 "keine_Warnung" ;
VAL_ 1091 RDK_Status 1 "Ein" 0 "Aus" ;
VAL_ 1091 RDK_neue_Solldruecke 1 "es_liegen_neue_Solldruecke_vor" 0 "keine_neuen_Solldruecke" ;
VAL_ 1091 RKA_KD_Fehler 1 "Fehlerspeichereintrag" 0 "kein_Fehlerspeichereintrag" ;
VAL_ 1091 RDK_Sensor_Multiplex 4 "RR" 3 "hr" 2 "hl" 1 "vr" 0 "vl" ;
VAL_ 1091 RDK_xx_Status_Sensor 1 "gueltig" 0 "ungueltig" ;
VAL_ 1091 RDK_xx_Color 2 "rot" 1 "gelb" 0 "gruen" ;
VAL_ 1091 RKA_Warnungen 15 "Belegung_nicht_moeglich_BY" 14 "Belegung_nicht_moeglich_BY" 13 "RD_hr_Taster" 12 "RD_hl_Taster" 11 "RD_vr_Taster" 10 "RD_vl_Taster" 9 "Systemfehler" 8 "neue_Druecke_erk" 7 "KBI_Hinweis_BA" 6 "RD_pruefen_Taster" 5 "RD_hr" 4 "RD_hl" 3 "RD_vr" 2 "RD_vl" 1 "RD_pruefen" 0 "keine_Warnung" ;
VAL_ 1091 RKA_FMVSS_138_Warnung 1 "Lampe_ein" 0 "Lampe_aus" ;
VAL_ 1091 RKA_FMVSS_138_MIL 1 "MIL_an" 0 "MIL_aus" ;
VAL_ 1091 RKA_Ack_IstZu_Solldruecke 1 "Bestaetigung_Soll_gleich_Istdruck" 0 "keine_Bestaetigung" ;
VAL_ 1091 RKA_Menue 1 "kein_Menue_RKA" 0 "Menue_RKA_gefordert" ;
VAL_ 1091 RKA_Akustik 1 "Akustik" 0 "keine_Akustik" ;
VAL_ 1472 EP1_QualNeigWi 1 "Ersatz_Init_oder_Fehlerwert" 0 "gueltiger_Wert" ;
VAL_ 1472 EP1_Fehler_Sta 3 "beide_Seiten_fehlerhaft" 2 "rechte_Seite_fehlerhaft" 1 "linke_Seite_fehlerhaft" 0 "volle_Funktion" ;
VAL_ 1472 EP1_Sta_EPB 1 "Bremse_geschlossen" 0 "Bremse_geoeffnet" ;
VAL_ 1472 EP1_Sta_Schalter 1 "Schalter_ausser_Funktion" 0 "volle_Funktion" ;
VAL_ 1472 EP1_Spannkraft 31 "Fehler" ;
VAL_ 1472 EP1_Schalterinfo 3 "Schalterfehler" 2 "Fahreranforderung_schliessen" 1 "Fahreranforderung_oeffnen" 0 "keine_Fahreranforderung" ;
VAL_ 1472 EP1_Sta_NWS 1 "keine_Funktion" 0 "volle_Funktion" ;
VAL_ 1472 EP1_Fehlereintr 1 "Fehlerspeichereintrag" 0 "kein_Fehlerspeichereintrag" ;
VAL_ 1472 EP1_Freigabe_Ver 1 "Verzoegerungsanf_freigegeben" 0 "Verzoegerungsanf_nicht_freigegeb" ;
VAL_ 1472 EP1_AutoHold_zul 1 "Pers_zulaessig" 0 "Pers_nicht_zulaessig" ;
VAL_ 1472 EP1_AutoHold_aktiv 1 "ja" 0 "nein" ;
VAL_ 1472 EP1_SleepInd 1 "Sleep_bereit" 0 "CAN_wird_benoetigt" ;
VAL_ 1472 EP1_Status_Kl_15 1 "Kl_15_ein" 0 "Kl_15_aus" ;
VAL_ 1472 EP1_Lampe_AutoP 1 "Lampe_ein" 0 "Lampe_aus" ;
VAL_ 1472 EP1_Bremslicht 1 "Ein" 0 "Aus" ;
VAL_ 1472 EP1_Warnton1 1 "Ein" 0 "Aus" ;
VAL_ 1472 EP1_Warnton2 1 "Ein" 0 "Aus" ;
VAL_ 1472 EP1_AnfShLock 1 "Ein" 0 "Aus" ;
VAL_ 1472 EPB_Autoholdlampe 1 "Lampe_ein" 0 "Lampe_aus" ;
VAL_ 1472 EP1_KuppModBer 3 "Sensor_defekt" 2 "Sensorsignal_ungenau" 1 "Kupplsensor_im_Modbereich" 0 "Kuppsensor_aus_Modbereich" ;
VAL_ 1472 EP1_HydrHalten 1 "Fzg_hydr_geh" 0 "Fzg_nicht_hydr_geh" ;
VAL_ 1472 EP1_Fkt_Lampe 1 "Lampe_ein" 0 "Lampe_aus" ;
VAL_ 1472 EP1_Warnton 1 "Warnton_an" 0 "Warnton_aus" ;
VAL_ 1472 EP1_Fehler_BKL 1 "BKL_an" 0 "BKL_aus" ;
VAL_ 1472 EP1_Fehler_gelb 1 "Lampe_ein" 0 "Lampe_aus" ;
VAL_ 1472 EP1__Text 8 "Text_8" 7 "reserviert" 6 "reserviert" 5 "Text_5" 4 "Text_4" 3 "Text_3" 2 "Text_2" 1 "Text_1" 0 "kein_Text" ;
VAL_ 65 AB_MKB_Anforderung 1 "Multikollisionsbremsung_angefordert" 0 "Multikollisionsbremsung_nicht_angefordert" ;
VAL_ 65 AB_MKB_gueltig 1 "Multikollisionsbremsung_freigeschaltet" 0 "Multikollisionsbremsung_nicht_freigeschaltet" ;
VAL_ 65 AB_MKB_Safing 1 "Multikollisionsbremsung_bestaetigt" 0 "Multikollisionsbremsung_nicht_bestaetigt" ;
VAL_ 1482 EPB_Status 3 "Fehler_oder_unbekannt" 2 "Aktuator_im_Lauf" 1 "Bremse_geschl_(Spannkraft_voll/reduziert)" 0 "offen" ;
